VERSION "HNNBNNNYNNNNNNNNNNNNNNNNNNNNNNNNNNNNNNNNNN/4/%%%/4/'%**4NNN///"

NS_ :

BS_:

BU_: Frontradar Frontsensorik

BO_ 262 ESP_05: 8 Vector__XXX
 SG_ ESP_05_CRC : 0|8@1+ (1,0) [0|255] ""  Frontradar,Frontsensorik
 SG_ ESP_05_BZ : 8|4@1+ (1,0) [0|15] ""  Frontradar,Frontsensorik
 SG_ ESP_QBit_Bremsdruck : 12|1@1+ (1,0) [0|1] ""  Frontradar,Frontsensorik
 SG_ ESP_QBit_Fahrer_bremst : 13|1@1+ (1,0) [0|1] ""  Frontradar
 SG_ ESP_Schwelle_Unterdruck : 14|2@1+ (1,0) [0|3] "" Vector__XXX
 SG_ ESP_Bremsdruck : 16|10@1+ (0.3,-30) [-30|276.6] "Unit_Bar"  Frontradar,Frontsensorik
 SG_ ESP_Fahrer_bremst : 26|1@1+ (1,0) [0|1] ""  Frontradar
 SG_ ESP_Verz_TSK_aktiv : 27|1@1+ (1,0) [0|1] "" Vector__XXX
 SG_ ESP_Lenkeingriff_ADS : 28|1@1+ (1,0) [0|1] "" Vector__XXX
 SG_ ESP_Konsistenz_TSK : 29|1@1+ (1,0) [0|1] "" Vector__XXX
 SG_ ESP_Bremsruck_AWV2 : 30|1@1+ (1,0) [0|1] "" Vector__XXX
 SG_ ESP_Konsistenz_AWV2 : 31|1@1+ (1,0) [0|1] "" Vector__XXX
 SG_ ECD_Fehler : 32|1@1+ (1,0) [0|1] "" Vector__XXX
 SG_ ECD_nicht_verfuegbar : 33|1@1+ (1,0) [0|1] "" Vector__XXX
 SG_ ESP_Status_Bremsentemp : 34|1@1+ (1,0) [0|1] ""  Frontradar
 SG_ ESP_Autohold_Standby : 35|1@1+ (1,0) [0|1] ""  Frontradar
 SG_ ESP_HDC_Standby : 36|1@1+ (1,0) [0|1] ""  Frontradar
 SG_ ESP_HBA_aktiv : 37|1@1+ (1,0) [0|1] "" Vector__XXX
 SG_ ESP_Prefill_ausgeloest : 38|1@1+ (1,0) [0|1] "" Vector__XXX
 SG_ ESP_Rueckwaertsfahrt_erkannt : 39|1@1+ (1,0) [0|1] "" Vector__XXX
 SG_ ESP_Status_Anfahrhilfe : 40|1@1+ (1,0) [0|1] "" Vector__XXX
 SG_ ESP_HDC_aktiv : 41|1@1+ (1,0) [0|1] ""  Frontradar
 SG_ ESP_StartStopp_Info : 42|2@1+ (1,0) [0|3] "" Vector__XXX
 SG_ ESP_Eingr_HL : 44|1@1+ (1,0) [0|1] "" Vector__XXX
 SG_ ESP_Eingr_HR : 45|1@1+ (1,0) [0|1] "" Vector__XXX
 SG_ ESP_Eingr_VL : 46|1@1+ (1,0) [0|1] "" Vector__XXX
 SG_ ESP_Eingr_VR : 47|1@1+ (1,0) [0|1] "" Vector__XXX
 SG_ ESP_BKV_Unterdruck : 48|8@1+ (4,0) [4|1012] "Unit_MilliBar" Vector__XXX
 SG_ ESP_Autohold_aktiv : 56|1@1+ (1,0) [0|1] ""  Frontradar
 SG_ ESP_FStatus_Anfahrhilfe : 57|1@1+ (1,0) [0|1] "" Vector__XXX
 SG_ ESP_Verz_EPB_aktiv : 58|1@1+ (1,0) [0|1] ""  Frontradar
 SG_ ECD_Bremslicht : 59|1@1+ (1,0) [0|1] "" Vector__XXX
 SG_ ESP_Verzoeg_EPB_verf : 60|1@1+ (1,0) [0|1] "" Vector__XXX
 SG_ ESP_Status_Bremsdruck : 61|1@1+ (1,0) [0|1] ""  Frontradar,Frontsensorik
 SG_ ESP_Anforderung_EPB : 62|2@1+ (1,0) [0|3] "" Vector__XXX

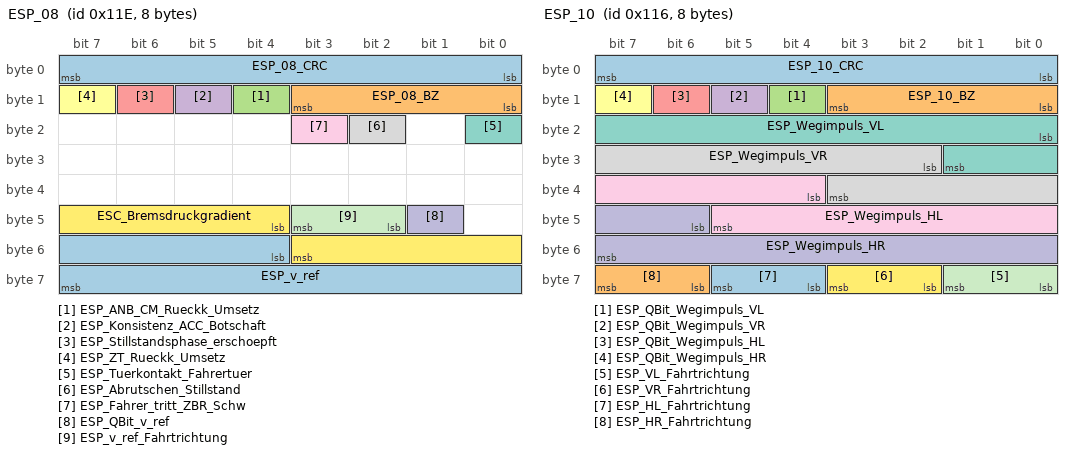
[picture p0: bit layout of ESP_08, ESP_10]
BO_ 286 ESP_08: 8 Vector__XXX
 SG_ ESP_08_CRC : 0|8@1+ (1,0) [0|255] "" Vector__XXX
 SG_ ESP_08_BZ : 8|4@1+ (1,0) [0|15] "" Vector__XXX
 SG_ ESP_ANB_CM_Rueckk_Umsetz : 12|1@1+ (1,0) [0|1] "" Vector__XXX
 SG_ ESP_Konsistenz_ACC_Botschaft : 13|1@1+ (1,0) [0|1] "" Vector__XXX
 SG_ ESP_Stillstandsphase_erschoepft : 14|1@1+ (1,0) [0|1] "" Vector__XXX
 SG_ ESP_ZT_Rueckk_Umsetz : 15|1@1+ (1,0) [0|1] "" Vector__XXX
 SG_ ESP_Tuerkontakt_Fahrertuer : 16|1@1+ (1,0) [0|1] "" Vector__XXX
 SG_ ESP_Abrutschen_Stillstand : 18|1@1+ (1,0) [0|1] "" Vector__XXX
 SG_ ESP_Fahrer_tritt_ZBR_Schw : 19|1@1+ (1,0) [0|1] "" Vector__XXX
 SG_ ESP_QBit_v_ref : 41|1@1+ (1,0) [0|1] "" Vector__XXX
 SG_ ESP_v_ref_Fahrtrichtung : 42|2@1+ (1,0) [0|3] "" Vector__XXX
 SG_ ESC_Bremsdruckgradient : 44|8@1+ (10,0) [0|2500] "Unit_BarPerSecon" Vector__XXX
 SG_ ESP_v_ref : 52|12@1+ (0.125,0) [0|511.5] "Unit_KiloMeterPerHour" Vector__XXX

BO_ 278 ESP_10: 8 Vector__XXX
 SG_ ESP_10_CRC : 0|8@1+ (1,0) [0|255] ""  Frontradar
 SG_ ESP_10_BZ : 8|4@1+ (1,0) [0|15] ""  Frontradar
 SG_ ESP_QBit_Wegimpuls_VL : 12|1@1+ (1,0) [0|1] ""  Frontradar
 SG_ ESP_QBit_Wegimpuls_VR : 13|1@1+ (1,0) [0|1] ""  Frontradar
 SG_ ESP_QBit_Wegimpuls_HL : 14|1@1+ (1,0) [0|1] ""  Frontradar
 SG_ ESP_QBit_Wegimpuls_HR : 15|1@1+ (1,0) [0|1] ""  Frontradar
 SG_ ESP_Wegimpuls_VL : 16|10@1+ (1,0) [0|1000] ""  Frontradar
 SG_ ESP_Wegimpuls_VR : 26|10@1+ (1,0) [0|1000] ""  Frontradar
 SG_ ESP_Wegimpuls_HL : 36|10@1+ (1,0) [0|1000] ""  Frontradar
 SG_ ESP_Wegimpuls_HR : 46|10@1+ (1,0) [0|1000] ""  Frontradar
 SG_ ESP_VL_Fahrtrichtung : 56|2@1+ (1,0) [0|3] ""  Frontradar
 SG_ ESP_VR_Fahrtrichtung : 58|2@1+ (1,0) [0|3] ""  Frontradar
 SG_ ESP_HL_Fahrtrichtung : 60|2@1+ (1,0) [0|3] ""  Frontradar
 SG_ ESP_HR_Fahrtrichtung : 62|2@1+ (1,0) [0|3] ""  Frontradar

BO_ 418 ESP_15: 8 Vector__XXX
 SG_ ESP_15_CRC : 0|8@1+ (1,0) [0|255] ""  Frontradar
 SG_ ESP_15_BZ : 8|4@1+ (1,0) [0|15] ""  Frontradar
 SG_ HMS_P_beibehalten_GE : 12|2@1+ (1,0) [0|3] "" Vector__XXX
 SG_ HMS_Konsistenz_GE : 14|1@1+ (1,0) [0|1] "" Vector__XXX
 SG_ HMS_Konsistenz_IPA : 15|1@1+ (1,0) [0|1] "" Vector__XXX
 SG_ HMS_Konsistenz_EBKV : 16|1@1+ (1,0) [0|1] "" Vector__XXX
 SG_ HMS_Konsistenz_RCTA : 17|1@1+ (1,0) [0|1] "" Vector__XXX
 SG_ HMS_Konsistenz_STA : 18|1@1+ (1,0) [0|1] "" Vector__XXX
 SG_ HMS_Konsistenz_MO : 19|1@1+ (1,0) [0|1] "" Vector__XXX
 SG_ HMS_halten_nicht_verfuegbar : 20|1@1+ (1,0) [0|1] "" Vector__XXX
 SG_ NL_PRIM_STP_01_Status : 21|3@1+ (1,0) [0|7] "" Vector__XXX
 SG_ HMS_Notstopp_Status : 29|3@1+ (1,0) [0|7] "" Vector__XXX
 SG_ HMS_parken_nicht_verfuegbar : 32|1@1+ (1,0) [0|1] "" Vector__XXX
 SG_ HMS_Anforderung_GE : 33|3@1+ (1,0) [0|7] "" Vector__XXX
 SG_ HMS_Systemstatus : 36|4@1+ (1,0) [0|15] ""  Frontradar
 SG_ HMS_Stillstand : 40|3@1+ (1,0) [0|7] "" Vector__XXX
 SG_ HMS_aktives_System : 43|5@1+ (1,0) [0|31] ""  Frontradar
 SG_ HMS_Konsistenz_HVLM : 48|1@1+ (1,0) [0|1] "" Vector__XXX
 SG_ HMS_Konsistenz_ACC : 49|1@1+ (1,0) [0|1] "" Vector__XXX
 SG_ HMS_Fehlerstatus : 50|3@1+ (1,0) [0|7] ""  Frontradar
 SG_ ESP_Index_Haltemoment : 53|1@1+ (1,0) [0|1] "" Vector__XXX
 SG_ ESP_Haltemoment : 54|10@1+ (10,0) [0|10210] "Unit_NewtoMeter" Vector__XXX

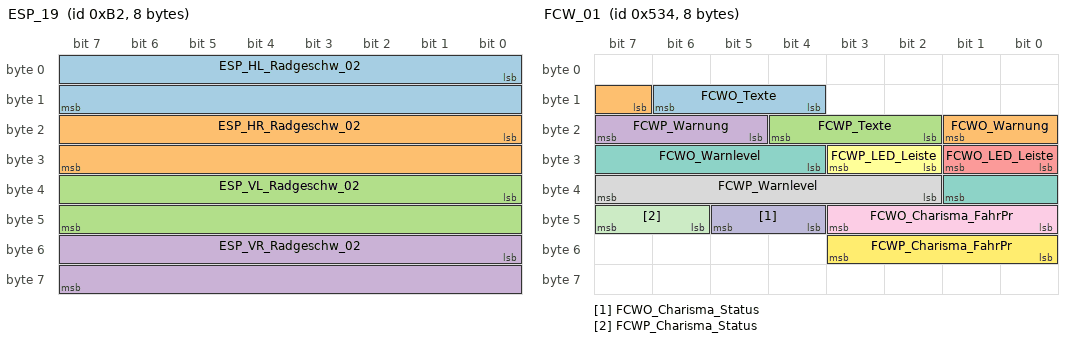
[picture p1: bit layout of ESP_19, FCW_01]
BO_ 178 ESP_19: 8 Vector__XXX
 SG_ ESP_HL_Radgeschw_02 : 0|16@1+ (0.0075,0) [0|491.49] "Unit_KiloMeterPerHour"  Frontradar
 SG_ ESP_HR_Radgeschw_02 : 16|16@1+ (0.0075,0) [0|491.49] "Unit_KiloMeterPerHour"  Frontradar
 SG_ ESP_VL_Radgeschw_02 : 32|16@1+ (0.0075,0) [0|491.49] "Unit_KiloMeterPerHour"  Frontradar
 SG_ ESP_VR_Radgeschw_02 : 48|16@1+ (0.0075,0) [0|491.49] "Unit_KiloMeterPerHour"  Frontradar

BO_ 1629 ESP_20: 8 Vector__XXX
 SG_ ESP_20_CRC : 0|8@1+ (1,0) [0|255] ""  Frontradar,Frontsensorik
 SG_ ESP_20_BZ : 8|4@1+ (1,0) [0|15] ""  Frontradar,Frontsensorik
 SG_ BR_Systemart : 12|2@1+ (1,0) [0|3] "" Vector__XXX
 SG_ ESP_SpannungsAnf_02 : 14|2@1+ (1,0) [0|3] "" Vector__XXX
 SG_ ESP_Zaehnezahl : 16|8@1+ (1,0) [0|255] ""  Frontradar,Frontsensorik
 SG_ ESP_Charisma_FahrPr : 24|4@1+ (1,0) [0|15] "" Vector__XXX
 SG_ ESP_Charisma_Status : 28|2@1+ (1,0) [0|3] "" Vector__XXX
 SG_ ESP_Wiederstart_Anz_01 : 30|1@1+ (1,0) [0|1] "" Vector__XXX
 SG_ ESP_Wiederstart_Anz_02 : 31|1@1+ (1,0) [0|1] "" Vector__XXX
 SG_ ESP_Wiederstart_Anz_03 : 32|1@1+ (1,0) [0|1] "" Vector__XXX
 SG_ ESP_Wiederstart_Anz_04 : 33|1@1+ (1,0) [0|1] "" Vector__XXX
 SG_ ESP_Stoppverbot_Anz_01 : 34|1@1+ (1,0) [0|1] "" Vector__XXX
 SG_ ESP_Stoppverbot_Anz_02 : 35|1@1+ (1,0) [0|1] "" Vector__XXX
 SG_ ESP_Stoppverbot_Anz_03 : 36|1@1+ (1,0) [0|1] "" Vector__XXX
 SG_ ESP_Stoppverbot_Anz_04 : 37|1@1+ (1,0) [0|1] "" Vector__XXX
 SG_ ESP_Stoppverbot_Anz_05 : 38|1@1+ (1,0) [0|1] "" Vector__XXX
 SG_ ESP_Stoppverbot_Anz_06 : 39|1@1+ (1,0) [0|1] "" Vector__XXX
 SG_ ESP_Stoppverbot_Anz_07 : 40|1@1+ (1,0) [0|1] "" Vector__XXX
 SG_ ESP_Stoppverbot_Anz_Std : 41|1@1+ (1,0) [0|1] "" Vector__XXX
 SG_ ESP_Dachrelingsensor : 42|2@1+ (1,0) [0|3] "" Vector__XXX
 SG_ ESP_Stoppverbot_Anz_08 : 44|1@1+ (1,0) [0|1] "" Vector__XXX
 SG_ HDC_Charisma_FahrPr : 45|4@1+ (1,0) [0|15] "" Vector__XXX
 SG_ HDC_Charisma_Status : 49|2@1+ (1,0) [0|3] "" Vector__XXX
 SG_ BR_QBit_Reifenumfang : 51|1@1+ (1,0) [0|1] ""  Frontradar,Frontsensorik
 SG_ BR_Reifenumfang : 52|12@1+ (1,0) [0|4095] "Unit_MilliMeter"  Frontradar,Frontsensorik

BO_ 253 ESP_21: 8 Vector__XXX
 SG_ ESP_21_CRC : 0|8@1+ (1,0) [0|255] ""  Frontradar,Frontsensorik
 SG_ ESP_21_BZ : 8|4@1+ (1,0) [0|15] ""  Frontradar,Frontsensorik
 SG_ BR_Eingriffsmoment : 12|10@1+ (1,-509) [-509|509] "" Vector__XXX
 SG_ ESP_PLA_Bremseingriff : 22|1@1+ (1,0) [0|1] "" Vector__XXX
 SG_ ESP_Diagnose : 23|1@1+ (1,0) [0|1] ""  Frontradar
 SG_ ESC_Reku_Freigabe : 24|1@1+ (1,0) [0|1] "" Vector__XXX
 SG_ ESC_v_Signal_Qualifier_High_Low : 25|3@1+ (1,0) [0|7] "" Vector__XXX
 SG_ ESP_Vorsteuerung : 28|1@1+ (1,0) [0|1] "" Vector__XXX
 SG_ ESP_AWV3_Brems_aktiv : 29|1@1+ (1,0) [0|1] "" Vector__XXX
 SG_ OBD_Schlechtweg : 30|1@1+ (1,0) [0|1] "" Vector__XXX
 SG_ OBD_QBit_Schlechtweg : 31|1@1+ (1,0) [0|1] "" Vector__XXX
 SG_ ESP_v_Signal : 32|16@1+ (0.01,0) [0|655.32] "Unit_KiloMeterPerHour"  Frontradar,Frontsensorik
 SG_ ASR_Tastung_passiv : 48|1@1+ (1,0) [0|1] ""  Frontradar,Frontsensorik
 SG_ ESP_Tastung_passiv : 49|1@1+ (1,0) [0|1] ""  Frontradar,Frontsensorik
 SG_ ESP_Systemstatus : 50|1@1+ (1,0) [0|1] ""  Frontradar
 SG_ ASR_Schalteingriff : 51|2@1+ (1,0) [0|3] "" Vector__XXX
 SG_ ESP_Haltebestaetigung : 53|1@1+ (1,0) [0|1] ""  Frontradar
 SG_ ESP_MKB_Abbruch_Geschw : 54|1@1+ (1,0) [0|1] "" Vector__XXX
 SG_ ESP_QBit_v_Signal : 55|1@1+ (1,0) [0|1] ""  Frontradar,Frontsensorik
 SG_ ABS_Bremsung : 56|1@1+ (1,0) [0|1] ""  Frontradar,Frontsensorik
 SG_ ASR_Anf : 57|1@1+ (1,0) [0|1] ""  Frontradar
 SG_ MSR_Anf : 58|1@1+ (1,0) [0|1] ""  Frontradar
 SG_ EBV_Eingriff : 59|1@1+ (1,0) [0|1] ""  Frontradar
 SG_ EDS_Eingriff : 60|1@1+ (1,0) [0|1] ""  Frontradar
 SG_ ESP_Eingriff : 61|1@1+ (1,0) [0|1] ""  Frontradar,Frontsensorik
 SG_ ESP_ASP : 62|1@1+ (1,0) [0|1] ""  Frontradar
 SG_ ESP_Anhaltevorgang_ACC_aktiv : 63|1@1+ (1,0) [0|1] "" Vector__XXX

BO_ 427 ESP_33: 8 Vector__XXX
 SG_ ESP_33_CRC : 0|8@1+ (1,0) [0|255] ""  Frontradar
 SG_ ESP_33_BZ : 8|4@1+ (1,0) [0|15] ""  Frontradar
 SG_ ESC_AHW_aktiv : 12|3@1+ (1,0) [0|7] ""  Frontradar
 SG_ ESC_AHW_nicht_verfuegbar : 15|1@1+ (1,0) [0|1] ""  Frontradar
 SG_ ESC_ANB_CM_aktiv : 16|2@1+ (1,0) [0|3] ""  Frontradar
 SG_ ESC_ANB_CM_nicht_verfuegbar : 18|1@1+ (1,0) [0|1] ""  Frontradar
 SG_ ESC_Warnruck_aktiv : 19|4@1+ (1,0) [0|15] ""  Frontradar
 SG_ ESC_Warnruck_nicht_verfuegbar : 23|1@1+ (1,0) [0|1] ""  Frontradar
 SG_ ESC_Prefill_aktiv : 24|1@1+ (1,0) [0|1] ""  Frontradar
 SG_ ESC_Prefill_nicht_verfuegbar : 25|1@1+ (1,0) [0|1] ""  Frontradar
 SG_ ESC_HBA_aktiv : 26|1@1+ (1,0) [0|1] ""  Frontradar
 SG_ ESC_HBA_nicht_verfuegbar : 27|1@1+ (1,0) [0|1] ""  Frontradar
 SG_ ESC_TSK_SRBM_Anf : 28|1@1+ (1,0) [0|1] ""  Frontradar
 SG_ ESC_TSK_SRBM_nicht_verfuegbar : 29|1@1+ (1,0) [0|1] "" Vector__XXX
 SG_ ESC_Verz_Reg_aktiv : 30|4@1+ (1,0) [0|15] ""  Frontradar
 SG_ ESC_Verz_Reg_nicht_verfuegbar : 34|1@1+ (1,0) [0|1] ""  Frontradar
 SG_ ESC_Verz_Reg_TB_nicht_verfuegbar : 35|1@1+ (1,0) [0|1] ""  Frontradar
 SG_ ESC_Verz_Reg_ZB_nicht_verfuegbar : 36|1@1+ (1,0) [0|1] ""  Frontradar
 SG_ ESC_Bremslicht_unplausibel : 37|1@1+ (1,0) [0|1] ""  Frontradar
 SG_ ESC_Konsistenz_ACC : 38|1@1+ (1,0) [0|1] ""  Frontradar
 SG_ ESC_Konsistenz_AWV : 39|1@1+ (1,0) [0|1] ""  Frontradar
 SG_ ESC_Konsistenz_ARA : 40|1@1+ (1,0) [0|1] "" Vector__XXX
 SG_ ESC_Konsistenz_IPA : 41|1@1+ (1,0) [0|1] "" Vector__XXX
 SG_ ESC_Konsistenz_FCW : 42|1@1+ (1,0) [0|1] "" Vector__XXX
 SG_ ESC_Konsistenz_NV : 43|1@1+ (1,0) [0|1] "" Vector__XXX
 SG_ ESC_Konsistenz_RCTA : 44|1@1+ (1,0) [0|1] "" Vector__XXX
 SG_ ESC_Konsistenz_TSK : 45|1@1+ (1,0) [0|1] "" Vector__XXX
 SG_ ESC_Konsistenz_vFGS : 46|1@1+ (1,0) [0|1] "" Vector__XXX
 SG_ ESC_Konsistenz_STA : 47|1@1+ (1,0) [0|1] "" Vector__XXX
 SG_ ESC_Fahrer_Bremsdruck_bestimmend : 48|1@1+ (1,0) [0|1] "" Vector__XXX
 SG_ ESC_Konsistenz_EA : 49|1@1+ (1,0) [0|1] "" Vector__XXX
 SG_ ESC_Konsistenz_BFF : 50|1@1+ (1,0) [0|1] "" Vector__XXX
 SG_ ESC_Konsistenz_MKB : 51|1@1+ (1,0) [0|1] "" Vector__XXX
 SG_ ESC_Verz_ASIL_Verfuegbarkeit : 52|3@1+ (1,0) [0|7] ""  Frontradar
 SG_ ESC_Pumpenanlauf_aktiv : 55|1@1+ (1,0) [0|1] ""  Frontradar
 SG_ ESC_Konsistenz_AGW : 56|1@1+ (1,0) [0|1] "" Vector__XXX
 SG_ ESC_Konsistenz_KAS : 57|1@1+ (1,0) [0|1] "" Vector__XXX
 SG_ ESC_Konsistenz_PCF : 58|1@1+ (1,0) [0|1] "" Vector__XXX

BO_ 264 Fahrwerk_01: 8 Vector__XXX
 SG_ Fahrwerk_01_CRC : 0|8@1+ (1,0) [0|255] "" Vector__XXX
 SG_ Fahrwerk_01_BZ : 8|4@1+ (1,0) [0|15] "" Vector__XXX
 SG_ FA_Hoehenwerte_kalibriert M : 12|1@1+ (1,0) [0|1] "" Vector__XXX
 SG_ FA_ESP_Zuschaltung : 13|1@1+ (1,0) [0|1] "" Vector__XXX
 SG_ FA_Hoehenwert_VL_00 m0 : 16|8@1+ (1,-127) [-127|126] "Unit_MilliMeter" Vector__XXX
 SG_ FA_Hoehenwert_VL_01 m1 : 16|8@1+ (0.4,0) [0|100] "Unit_PerCent" Vector__XXX
 SG_ FA_Hoehenwert_VR_00 m0 : 24|8@1+ (1,-127) [-127|126] "Unit_MilliMeter" Vector__XXX
 SG_ FA_Hoehenwert_VR_01 m1 : 24|8@1+ (0.4,0) [0|100] "Unit_PerCent" Vector__XXX
 SG_ FA_Hoehenwert_HL_00 m0 : 32|8@1+ (1,-127) [-127|126] "Unit_MilliMeter" Vector__XXX
 SG_ FA_Hoehenwert_HL_01 m1 : 32|8@1+ (0.4,0) [0|100] "Unit_PerCent" Vector__XXX
 SG_ FA_Hoehenwert_HR_00 m0 : 40|8@1+ (1,-127) [-127|126] "Unit_MilliMeter" Vector__XXX
 SG_ FA_Hoehenwert_HR_01 m1 : 40|8@1+ (0.4,0) [0|100] "Unit_PerCent" Vector__XXX

BO_ 1332 FCW_01: 8 Vector__XXX
 SG_ FCWO_Texte : 12|3@1+ (1,0) [0|7] "" Vector__XXX
 SG_ FCWO_Warnung : 15|3@1+ (1,0) [0|7] "" Vector__XXX
 SG_ FCWP_Texte : 18|3@1+ (1,0) [0|7] "" Vector__XXX
 SG_ FCWP_Warnung : 21|3@1+ (1,0) [0|7] "" Vector__XXX
 SG_ FCWO_LED_Leiste : 24|2@1+ (1,0) [0|3] "" Vector__XXX
 SG_ FCWP_LED_Leiste : 26|2@1+ (1,0) [0|3] "" Vector__XXX
 SG_ FCWO_Warnlevel : 28|6@1+ (1,0) [0|63] "" Vector__XXX
 SG_ FCWP_Warnlevel : 34|6@1+ (1,0) [0|63] ""  Frontradar
 SG_ FCWO_Charisma_FahrPr : 40|4@1+ (1,0) [0|15] "" Vector__XXX
 SG_ FCWO_Charisma_Status : 44|2@1+ (1,0) [0|3] "" Vector__XXX
 SG_ FCWP_Charisma_Status : 46|2@1+ (1,0) [0|3] "" Vector__XXX
 SG_ FCWP_Charisma_FahrPr : 48|4@1+ (1,0) [0|15] "" Vector__XXX

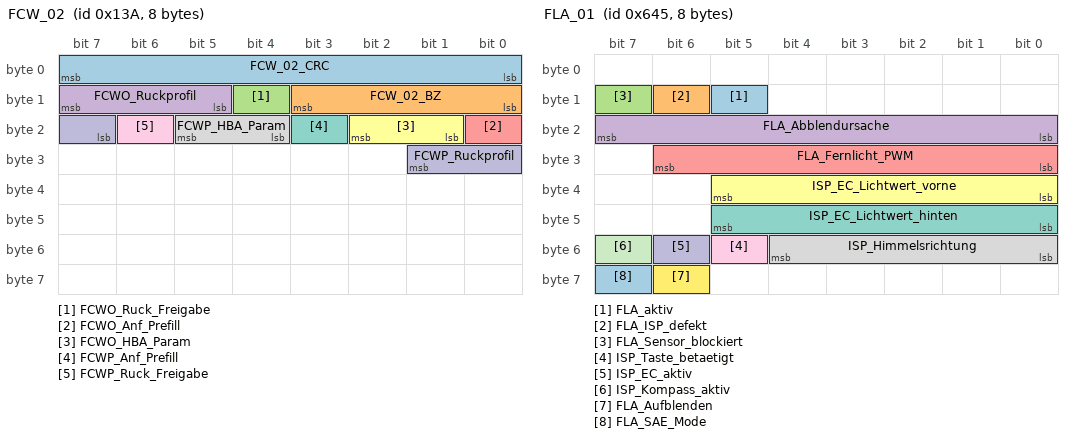
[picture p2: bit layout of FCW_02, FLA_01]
BO_ 314 FCW_02: 8 Vector__XXX
 SG_ FCW_02_CRC : 0|8@1+ (1,0) [0|255] "" Vector__XXX
 SG_ FCW_02_BZ : 8|4@1+ (1,0) [0|15] "" Vector__XXX
 SG_ FCWO_Ruck_Freigabe : 12|1@1+ (1,0) [0|1] "" Vector__XXX
 SG_ FCWO_Ruckprofil : 13|3@1+ (1,0) [0|7] "" Vector__XXX
 SG_ FCWO_Anf_Prefill : 16|1@1+ (1,0) [0|1] "" Vector__XXX
 SG_ FCWO_HBA_Param : 17|2@1+ (1,0) [0|3] "" Vector__XXX
 SG_ FCWP_Anf_Prefill : 19|1@1+ (1,0) [0|1] "" Vector__XXX
 SG_ FCWP_HBA_Param : 20|2@1+ (1,0) [0|3] "" Vector__XXX
 SG_ FCWP_Ruck_Freigabe : 22|1@1+ (1,0) [0|1] "" Vector__XXX
 SG_ FCWP_Ruckprofil : 23|3@1+ (1,0) [0|7] "" Vector__XXX

BO_ 1605 FLA_01: 8 Frontsensorik
 SG_ FLA_aktiv : 13|1@1+ (1,0) [0|1] "" Vector__XXX
 SG_ FLA_ISP_defekt : 14|1@1+ (1,0) [0|1] "" Vector__XXX
 SG_ FLA_Sensor_blockiert : 15|1@1+ (1,0) [0|1] "" Vector__XXX
 SG_ FLA_Abblendursache : 16|8@1+ (1,0) [0|255] "" Vector__XXX
 SG_ FLA_Fernlicht_PWM : 24|7@1+ (1,0) [0|100] "Unit_PerCent" Vector__XXX
 SG_ ISP_EC_Lichtwert_vorne : 32|6@1+ (1,0) [0|61] "Unit_None" Vector__XXX
 SG_ ISP_EC_Lichtwert_hinten : 40|6@1+ (1,0) [0|61] "Unit_None" Vector__XXX
 SG_ ISP_Himmelsrichtung : 48|5@1+ (12,0) [0|348] "Unit_DegreOfArc" Vector__XXX
 SG_ ISP_Taste_betaetigt : 53|1@1+ (1,0) [0|1] "" Vector__XXX
 SG_ ISP_EC_aktiv : 54|1@1+ (1,0) [0|1] "" Vector__XXX
 SG_ ISP_Kompass_aktiv : 55|1@1+ (1,0) [0|1] "" Vector__XXX
 SG_ FLA_Aufblenden : 62|1@1+ (1,0) [0|1] "" Vector__XXX
 SG_ FLA_SAE_Mode : 63|1@1+ (1,0) [0|1] "" Vector__XXX

BO_ 987 Gateway_72: 8 Vector__XXX
 SG_ BCM_01_alt : 0|1@1+ (1,0) [0|1] ""  Frontradar,Frontsensorik
 SG_ SMLS_01_alt : 1|1@1+ (1,0) [0|1] ""  Frontradar,Frontsensorik
 SG_ ZV_02_alt : 2|1@1+ (1,0) [0|1] ""  Frontradar
 SG_ Wischer_01_alt : 3|1@1+ (1,0) [0|1] ""  Frontradar,Frontsensorik
 SG_ Anhaenger_01_alt : 4|1@1+ (1,0) [0|1] ""  Frontradar,Frontsensorik
 SG_ Klima_Sensor_02_alt : 5|1@1+ (1,0) [0|1] ""  Frontradar,Frontsensorik
 SG_ Verdeck_01_alt : 6|1@1+ (1,0) [0|1] "" Vector__XXX
 SG_ Klima_11_alt : 7|1@1+ (1,0) [0|1] "" Vector__XXX
 SG_ WFS_01_alt : 8|1@1+ (1,0) [0|1] ""  Frontradar,Frontsensorik
 SG_ Licht_Anf_01_alt : 9|1@1+ (1,0) [0|1] "" Vector__XXX
 SG_ ZV_verriegelt_extern_soll : 10|1@1+ (1,0) [0|1] "" Vector__XXX
 SG_ BH_Lichthupe : 11|1@1+ (1,0) [0|1] "" Vector__XXX
 SG_ WFS_Klemmenfreigabe : 12|1@1+ (1,0) [0|1] "" Vector__XXX
 SG_ ZV_Tankklappe_offen : 13|1@1+ (1,0) [0|1] "" Vector__XXX
 SG_ AAG_Anhaenger_abgesteckt : 14|1@1+ (1,0) [0|1] "" Vector__XXX
 SG_ BCM1_LDS_Stellung : 15|3@1+ (1,0) [0|7] "" Vector__XXX
 SG_ VS_Verdeck_Anf : 18|1@1+ (1,0) [0|1] "" Vector__XXX
 SG_ VS_VD_entriegelt : 19|1@1+ (1,0) [0|1] "" Vector__XXX
 SG_ ZV_HFS_offen : 20|1@1+ (1,0) [0|1] ""  Frontradar
 SG_ ZV_HBFS_offen : 21|1@1+ (1,0) [0|1] ""  Frontradar
 SG_ VS_VD_offen_ver : 22|1@1+ (1,0) [0|1] "" Vector__XXX
 SG_ VS_VD_zu_ver : 23|1@1+ (1,0) [0|1] "" Vector__XXX
 SG_ ZV_BT_offen : 24|1@1+ (1,0) [0|1] ""  Frontradar
 SG_ BCM1_Rueckfahrlicht_Schalter : 25|1@1+ (1,0) [0|1] ""  Frontradar,Frontsensorik
 SG_ ZV_FT_offen : 26|1@1+ (1,0) [0|1] ""  Frontradar
 SG_ Wischer_vorne_aktiv : 27|1@1+ (1,0) [0|1] ""  Frontradar,Frontsensorik
 SG_ AAG_Anhaenger_erkannt : 28|1@1+ (1,0) [0|1] ""  Frontradar,Frontsensorik
 SG_ BCM1_MH_Schalter : 29|1@1+ (1,0) [0|1] ""  Frontradar
 SG_ ZV_HD_offen : 30|1@1+ (1,0) [0|1] "" Vector__XXX
 SG_ Waschen_vorne_aktiv : 31|1@1+ (1,0) [0|1] "" Vector__XXX
 SG_ KL_Thermomanagement : 32|2@1+ (1,0) [0|3] "" Vector__XXX
 SG_ WFS_Schluessel_Fahrberecht : 34|4@1+ (1,0) [0|15] ""  Frontradar,Frontsensorik
 SG_ BCM_Rueckfahrlicht_Anf : 38|1@1+ (1,0) [0|1] "" Vector__XXX
 SG_ WWSs_01_alt : 39|1@1+ (1,0) [0|1] ""  Frontradar,Frontsensorik
 SG_ BCM_Tankklappensteller_Fehler : 40|1@1+ (1,0) [0|1] "" Vector__XXX
 SG_ ZV_verriegelt_soll : 42|2@1+ (1,0) [0|3] "" Vector__XXX
 SG_ ZV_Schluessel_Zugang : 44|4@1+ (1,0) [0|15] "" Vector__XXX
 SG_ WFS_ID_Geb_autorisiert_in_Kl15 : 48|1@1+ (1,0) [0|1] "" Vector__XXX
 SG_ BH_Fernlicht : 49|1@1+ (1,0) [0|1] ""  Frontsensorik
 SG_ BH_Blinker_li : 50|1@1+ (1,0) [0|1] ""  Frontradar,Frontsensorik
 SG_ BH_Blinker_re : 51|1@1+ (1,0) [0|1] ""  Frontradar,Frontsensorik
 SG_ BCM1_OBD_FStatus_ATemp : 52|4@1+ (1,0) [0|15] "" Vector__XXX
 SG_ BCM1_Aussen_Temp_ungef : 56|8@1+ (0.5,-50) [-50|76] "Unit_DegreCelsi"  Frontradar,Frontsensorik

BO_ 988 Gateway_73: 8 Vector__XXX
 SG_ Motor_12_alt : 0|1@1+ (1,0) [0|1] ""  Frontradar
 SG_ ESP_07_alt : 1|1@1+ (1,0) [0|1] ""  Frontradar
 SG_ Getriebe_11_alt : 2|1@1+ (1,0) [0|1] "" Vector__XXX
 SG_ Getriebe_13_alt : 3|1@1+ (1,0) [0|1] ""  Frontradar
 SG_ Getriebe_17_alt : 4|1@1+ (1,0) [0|1] ""  Frontradar
 SG_ GW_73_va_15 : 5|1@1+ (1,0) [0|1] "" Vector__XXX
 SG_ GW_73_va_16 : 6|1@1+ (1,0) [0|1] "" Vector__XXX
 SG_ GW_73_va_17 : 7|1@1+ (1,0) [0|1] "" Vector__XXX
 SG_ MO_QBit_Drehzahl_01 : 8|1@1+ (1,0) [0|1] ""  Frontradar
 SG_ MKE_Texte : 9|2@1+ (1,0) [0|3] ""  Frontradar
 SG_ MKE_Stufe : 11|3@1+ (1,0) [0|7] ""  Frontradar
 SG_ MO_Drehzahl_01 : 16|16@1+ (0.25,0) [0|16383] "Unit_MinutInver"  Frontradar
 SG_ GE_Fahrstufe : 40|4@1+ (1,0) [0|15] "" Vector__XXX
 SG_ GE_reserv_Fahrstufe : 44|1@1+ (1,0) [0|1] "" Vector__XXX
 SG_ GE_Notlauf : 45|1@1+ (1,0) [0|1] ""  Frontradar
 SG_ ESP_Rollenmodus_Deaktivieren : 46|1@1+ (1,0) [0|1] ""  Frontradar
 SG_ GE_Freilauf_Status : 47|3@1+ (1,0) [0|7] ""  Frontradar

BO_ 991 Gateway_76: 8 Vector__XXX
 SG_ Innenlicht_11_alt : 0|1@1+ (1,0) [0|1] ""  Frontsensorik
 SG_ Spiegel_01_alt : 1|1@1+ (1,0) [0|1] "" Vector__XXX
 SG_ Anhaenger_01_alt : 2|1@1+ (1,0) [0|1] ""  Frontradar
 SG_ Licht_hinten_01_alt : 3|1@1+ (1,0) [0|1] ""  Frontradar
 SG_ LH_EPS_01_alt : 4|1@1+ (1,0) [0|1] ""  Frontsensorik
 SG_ Klima_12_alt : 5|1@1+ (1,0) [0|1] ""  Frontsensorik
 SG_ SMLS_01_alt : 6|1@1+ (1,0) [0|1] ""  Frontsensorik
 SG_ Getriebe_14_alt : 7|1@1+ (1,0) [0|1] ""  Frontradar
 SG_ PLA_01_alt : 8|1@1+ (1,0) [0|1] ""  Frontradar
 SG_ PLA_Status_PLA_EPS : 12|4@1+ (1,0) [0|15] ""  Frontradar
 SG_ IL_Innenlicht_aktiv : 16|1@1+ (1,0) [0|1] ""  Frontsensorik
 SG_ FAS_Taster_Fehler : 17|1@1+ (1,0) [0|1] ""  Frontsensorik
 SG_ AAG_Bremslicht_H_def : 18|1@1+ (1,0) [0|1] ""  Frontradar
 SG_ LH_3_Bremsl_def : 19|1@1+ (1,0) [0|1] ""  Frontradar
 SG_ LH_Bremsl_li_ges_def : 20|1@1+ (1,0) [0|1] ""  Frontradar
 SG_ LH_Bremsl_re_ges_def : 21|1@1+ (1,0) [0|1] ""  Frontradar
 SG_ KL_Beschlagsgefahr : 22|1@1+ (1,0) [0|1] ""  Frontsensorik
 SG_ FAS_Taster : 23|1@1+ (1,0) [0|1] ""  Frontsensorik
 SG_ SP_abklappen : 24|1@1+ (1,0) [0|1] "" Vector__XXX
 SG_ SP_anklappen : 25|1@1+ (1,0) [0|1] "" Vector__XXX
 SG_ KL_Umluftklappe_Status : 26|4@1+ (1,0) [0|15] "" Vector__XXX
 SG_ GE_amax_moeglich : 30|9@1+ (0.024,-2.016) [-2.016|10.224] "Unit_MeterPerSeconSquar"  Frontradar
 SG_ KL_Geblspng_Soll : 40|8@1+ (0.05,1.45) [1.5|14] "Unit_Volt" Vector__XXX
 SG_ EPS_Charisma_FahrPr : 58|4@1+ (1,0) [0|15] ""  Frontsensorik
 SG_ GE_Zustand_Kuppltemp : 62|2@1+ (1,0) [0|3] ""  Frontradar

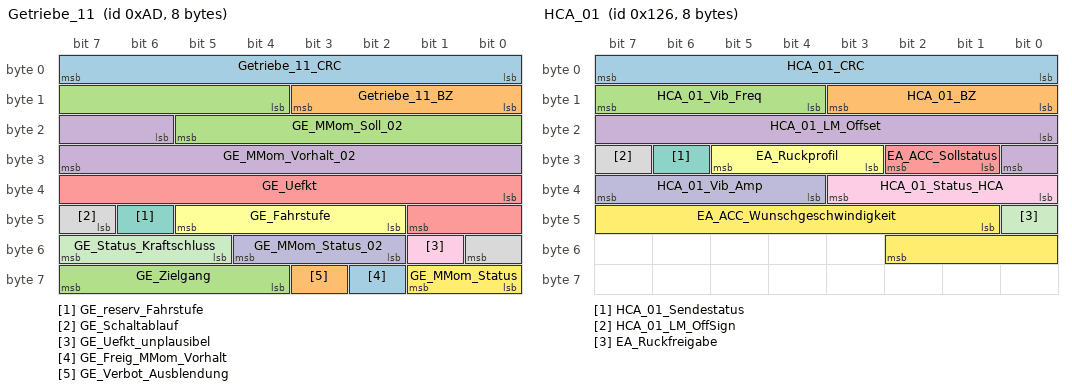
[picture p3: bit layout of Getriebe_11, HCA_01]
BO_ 173 Getriebe_11: 8 Vector__XXX
 SG_ Getriebe_11_CRC : 0|8@1+ (1,0) [0|255] ""  Frontradar
 SG_ Getriebe_11_BZ : 8|4@1+ (1,0) [0|15] ""  Frontradar
 SG_ GE_MMom_Soll_02 : 12|10@1+ (1,-509) [-509|509] "" Vector__XXX
 SG_ GE_MMom_Vorhalt_02 : 22|10@1+ (1,-509) [-509|509] "" Vector__XXX
 SG_ GE_Uefkt : 32|10@1+ (0.1,0) [0|102.2] "" Vector__XXX
 SG_ GE_Fahrstufe : 42|4@1+ (1,0) [0|15] ""  Frontradar
 SG_ GE_reserv_Fahrstufe : 46|1@1+ (1,0) [0|1] "" Vector__XXX
 SG_ GE_Schaltablauf : 47|2@1+ (1,0) [0|3] "" Vector__XXX
 SG_ GE_Uefkt_unplausibel : 49|1@1+ (1,0) [0|1] "" Vector__XXX
 SG_ GE_MMom_Status_02 : 50|3@1+ (1,0) [0|7] "" Vector__XXX
 SG_ GE_Status_Kraftschluss : 53|3@1+ (1,0) [0|7] "" Vector__XXX
 SG_ GE_MMom_Status : 56|2@1+ (1,0) [0|3] "" Vector__XXX
 SG_ GE_Freig_MMom_Vorhalt : 58|1@1+ (1,0) [0|1] "" Vector__XXX
 SG_ GE_Verbot_Ausblendung : 59|1@1+ (1,0) [0|1] "" Vector__XXX
 SG_ GE_Zielgang : 60|4@1+ (1,0) [0|15] "" Vector__XXX

BO_ 299 GRA_ACC_01: 8 Vector__XXX
 SG_ GRA_ACC_01_CRC : 0|8@1+ (1,0) [0|255] ""  Frontradar
 SG_ GRA_ACC_01_BZ : 8|4@1+ (1,0) [0|15] ""  Frontradar
 SG_ GRA_Hauptschalter : 12|1@1+ (1,0) [0|1] ""  Frontradar
 SG_ GRA_Abbrechen : 13|1@1+ (1,0) [0|1] ""  Frontradar
 SG_ GRA_Typ_Hauptschalter : 14|1@1+ (1,0) [0|1] ""  Frontradar
 SG_ GRA_Limiter : 15|1@1+ (1,0) [0|1] "" Vector__XXX
 SG_ GRA_Tip_Setzen : 16|1@1+ (1,0) [0|1] ""  Frontradar
 SG_ GRA_Tip_Hoch : 17|1@1+ (1,0) [0|1] ""  Frontradar
 SG_ GRA_Tip_Runter : 18|1@1+ (1,0) [0|1] ""  Frontradar
 SG_ GRA_Tip_Wiederaufnahme : 19|1@1+ (1,0) [0|1] ""  Frontradar
 SG_ GRA_Verstellung_Zeitluecke : 20|2@1+ (1,0) [0|3] ""  Frontradar
 SG_ GRA_Codierung : 22|2@1+ (1,0) [0|3] ""  Frontradar
 SG_ GRA_Fehler : 24|1@1+ (1,0) [0|1] ""  Frontradar
 SG_ GRA_LIM_Taste_verfuegbar : 25|1@1+ (1,0) [0|1] "" Vector__XXX
 SG_ GRA_Tip_Stufe_2 : 26|1@1+ (1,0) [0|1] ""  Frontradar
 SG_ GRA_Typ_Bedienteil : 27|3@1+ (1,0) [0|7] ""  Frontradar
 SG_ GRA_reserveByte4 : 30|2@1+ (1,0) [0|3] "" Vector__XXX
 SG_ GRA_reserveByte5 : 32|8@1+ (1,0) [0|255] "" Vector__XXX
 SG_ GRA_reserveByte6 : 40|8@1+ (1,0) [0|255] "" Vector__XXX
 SG_ GRA_reserveByte7 : 48|8@1+ (1,0) [0|255] "" Vector__XXX
 SG_ GRA_reserveByte8 : 56|8@1+ (1,0) [0|255] "" Vector__XXX

BO_ 294 HCA_01: 8 Frontsensorik
 SG_ HCA_01_CRC : 0|8@1+ (1,0) [0|255] "" Vector__XXX
 SG_ HCA_01_BZ : 8|4@1+ (1,0) [0|15] "" Vector__XXX
 SG_ HCA_01_Vib_Freq : 12|4@1+ (1,15) [15|30] "Unit_Hertz" Vector__XXX
 SG_ HCA_01_LM_Offset : 16|9@1+ (0.01,0) [0|5.11] "Unit_NewtoMeter" Vector__XXX
 SG_ EA_ACC_Sollstatus : 25|2@1+ (1,0) [0|3] ""  Frontradar
 SG_ EA_Ruckprofil : 27|3@1+ (1,0) [0|7] "" Vector__XXX
 SG_ HCA_01_Sendestatus : 30|1@1+ (1,0) [0|1] "" Vector__XXX
 SG_ HCA_01_LM_OffSign : 31|1@1+ (1,0) [0|1] "" Vector__XXX
 SG_ HCA_01_Status_HCA : 32|4@1+ (1,0) [0|15] "" Vector__XXX
 SG_ HCA_01_Vib_Amp : 36|4@1+ (0.2,0) [0|3] "Unit_NewtoMeter" Vector__XXX
 SG_ EA_Ruckfreigabe : 40|1@1+ (1,0) [0|1] "" Vector__XXX
 SG_ EA_ACC_Wunschgeschwindigkeit : 41|10@1+ (0.32,0) [0|327.04] "Unit_KiloMeterPerHour"  Frontradar

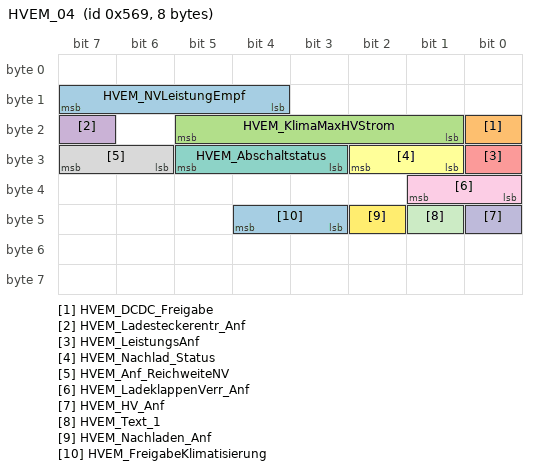
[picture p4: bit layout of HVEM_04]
BO_ 1385 HVEM_04: 8 Vector__XXX
 SG_ HVEM_NVLeistungEmpf : 12|4@1+ (100,0) [0|1500] "Unit_Watt" Vector__XXX
 SG_ HVEM_DCDC_Freigabe : 16|1@1+ (1,0) [0|1] "" Vector__XXX
 SG_ HVEM_KlimaMaxHVStrom : 17|5@1+ (1,0) [0|31] "Unit_Amper" Vector__XXX
 SG_ HVEM_Ladesteckerentr_Anf : 23|1@1+ (1,0) [0|1] "" Vector__XXX
 SG_ HVEM_LeistungsAnf : 24|1@1+ (1,0) [0|1] "" Vector__XXX
 SG_ HVEM_Nachlad_Status : 25|2@1+ (1,0) [0|3] "" Vector__XXX
 SG_ HVEM_Abschaltstatus : 27|3@1+ (1,0) [0|7] "" Vector__XXX
 SG_ HVEM_Anf_ReichweiteNV : 30|2@1+ (1,0) [0|3] "" Vector__XXX
 SG_ HVEM_LadeklappenVerr_Anf : 32|2@1+ (1,0) [0|3] "" Vector__XXX
 SG_ HVEM_HV_Anf : 40|1@1+ (1,0) [0|1] "" Vector__XXX
 SG_ HVEM_Text_1 : 41|1@1+ (1,0) [0|1] "" Vector__XXX
 SG_ HVEM_Nachladen_Anf : 42|1@1+ (1,0) [0|1] "" Vector__XXX
 SG_ HVEM_FreigabeKlimatisierung : 43|2@1+ (1,0) [0|3] "" Vector__XXX

BO_ 1879 ISO_ACC_Req: 8 Vector__XXX
 SG_ ISO_ACC_Req_Data : 0|64@1+ (1,0) [0|1.84467440737096E+019] ""  Frontradar

BO_ 1985 ISO_ACC_Resp: 8 Frontradar
 SG_ ISO_ACC_Resp_Data : 0|64@1+ (1,0) [0|1.84467440737096E+019] "" Vector__XXX

BO_ 1840 ISO_FLA_Req: 8 Vector__XXX
 SG_ ISO_FLA_Req_Data : 0|64@1+ (1,0) [0|1.84467440737096E+019] "" Vector__XXX

BO_ 1946 ISO_FLA_Resp: 8 Vector__XXX
 SG_ ISO_FLA_Resp_Data : 0|64@1+ (1,0) [0|1.84467440737096E+019] "" Vector__XXX

BO_ 1793 ISO_Funktionaler_Req_01: 8 Vector__XXX
 SG_ ISO_01_Req_Data : 0|64@1+ (1,0) [0|1.84467440737096E+019] "" Vector__XXX

BO_ 1794 ISO_Funktionaler_Req_02: 8 Vector__XXX
 SG_ ISO_02_Req_Data : 0|64@1+ (1,0) [0|1.84467440737096E+019] "" Vector__XXX

BO_ 1796 ISO_Funktionaler_Req_04: 8 Vector__XXX
 SG_ ISO_04_Req_Data : 0|64@1+ (1,0) [0|1.84467440737096E+019] "" Vector__XXX

BO_ 1797 ISO_Funktionaler_Req_05: 8 Vector__XXX
 SG_ ISO_05_Req_Data : 0|64@1+ (1,0) [0|1.84467440737096E+019] "" Vector__XXX

BO_ 1798 ISO_Funktionaler_Req_06: 8 Vector__XXX
 SG_ ISO_06_Req_Data : 0|64@1+ (1,0) [0|1.84467440737096E+019] "" Vector__XXX

BO_ 1799 ISO_Funktionaler_Req_07: 8 Vector__XXX
 SG_ ISO_07_Req_Data : 0|64@1+ (1,0) [0|1.84467440737096E+019] "" Vector__XXX

BO_ 1800 ISO_Funktionaler_Req_08: 8 Vector__XXX
 SG_ ISO_08_Req_Data : 0|64@1+ (1,0) [0|1.84467440737096E+019] "" Vector__XXX

CM_ SG_ 262 ESP_05_CRC "Für MLB:
'Berechnung siehe Lastenheft 'Kommunikationsabsicherung für FlexRay und CAN''

Ab MQB und MLBevo:
'Berechnung siehe Lastenheft 'End-to-End Kommunikationsabsicherung''

Endwerte siehe Begleitdokument 'S-PDU Kennungsfolgen'";
CM_ SG_ 262 ESP_QBit_Bremsdruck "QBit des Bremsdrucks. Gesetzt bei Ersatzwert, Init oder Fehler.";
CM_ SG_ 262 ESP_QBit_Fahrer_bremst "Gültigkeit der Bremsdruckschwelleninformation des Signals ESP_Fahrer_bremst vom ESP SG
0x1 = Druckschwelleninformation kann noch nicht oder aufgrund eines Fehlers nicht ausgegeben werden
";
CM_ SG_ 262 ESP_Schwelle_Unterdruck "Verwendung im MQB für HBV-Projekte oder wenn für St/St ein Unterdrucksensor verbaut ist";
CM_ SG_ 262 ESP_Bremsdruck "Rohwert des Bremsdrucks [Vordruck durch Fahrervorgabe (Pvor). Bei aktivem Druckaufbau (Stabilisierungseingriffe) kein Pvor]
";
CM_ SG_ 262 ESP_Fahrer_bremst "Bit wird gesetzt beim Überschreiten der Bremsdruckschwelle

Weiterführende Informationen im Lastenheft spezifiziert und in der entsprechenden Fachabteilung zu erfragen.
";
CM_ SG_ 262 ESP_Verz_TSK_aktiv "Rückmeldeinformation an den Triebsstrangkoordinator/ACC, dass die ECD-Verzögerungsanforderung aktuell umgesetzt wird";
CM_ SG_ 262 ESP_Lenkeingriff_ADS "Im Falle eines fahrzeugstabilisierenden Lenkeingriffs des ADS-Systems soll ACC/GRA deaktiviert werden.

Im MQB wird dieses Signal nicht unterstützt!";
CM_ SG_ 262 ESP_Konsistenz_TSK "Rückmeldung zum Sender einer Verzögerungsanforderung (Triebstrangskoordinator) bezüglich Prüfung der Checksumme, des Botschaftszählers, des langen Timeout und DLC. Wird auch gesetzt bei Verzögerungsanforderung größer einer applizierbaren Schwelle.
";
CM_ SG_ 262 ESP_Bremsruck_AWV2 "Das Signal dient als Rückmeldung zum ACC, dass ein angeforderter AWV2-Bremsruck durchgeführt wird. Die positive Rückmeldung löst u.a. eine entsprechende Fahrerinformation im Kombiinstrument aus";
CM_ SG_ 262 ESP_Konsistenz_AWV2 "Rückmeldung zum Sender einer AWV-Anforderung (ACC-Steuergerät) bezüglich Prüfung der Checksumme, des Botschaftszählers, des langen Timeout und DLC.
";
CM_ SG_ 262 ECD_Fehler "ESP kann die Verzögerungsregelung/Bremsenregelung aufgrund eines internen Fehlers nicht ausführen, mit Fehlereintrag im ESP.
";
CM_ SG_ 262 ECD_nicht_verfuegbar "ESP kann die Verzögerungsregelung/Bremsenregelung temporär nicht ausführen (z.B. Netzwerkmanagement-Betriebe - KL15 Aus; v<18km/h; ESP in Diagnose, ...), ohne Fehlereintrag im ESP.

";
CM_ SG_ 262 ESP_Status_Bremsentemp "ECD-Bremsscheibentemperaturmodell. Rückmeldung für Sender einer ECD Verzögerungsanforderung, ohne Fehlereintrag im ESP";
CM_ SG_ 262 ESP_Autohold_Standby "Rückmeldung an EPB, dass der Fahrer die Funktion Autohold mindestens einmal angefordert hat. Im Fall eines ESP-Ausfalles oder einer Übernahmeaufforderung erfolgt die EPB-Zuschaltung nur nach Setzen dieses Bits. Bit wird gesetzt nach Betätigung des Autohol";
CM_ SG_ 262 ESP_HDC_Standby "Verwendung/Bedienung im MQB und AU57x Allroad:
Flag wird vom ESP gesetzt, wenn über den HDC-Taster die HDC-Funktion eingeschalten wurde";
CM_ SG_ 262 ESP_HBA_aktiv "Verwendung/Bedienung ab D4
Signal gibt an, ob der hydraulische Bremsassistent im Regler aktiviert wurde

Im MQB wird das Signal nicht unterstützt!

";
CM_ SG_ 262 ESP_Prefill_ausgeloest "MLB: Verwendung/Bedienung ab D4
zeigt, ob die Funktion Prefill (aufgrund Fahrpedalgradient) ausgelöst wird; zeigt keinen Funktionszustand bezüglich Fehlerstilllegung

MQB: Wird gesetzt bei jeder Art von aktivem Prefill";
CM_ SG_ 262 ESP_Rueckwaertsfahrt_erkannt "nur bei AU57x und AU416 sowie Audi B8PA
Info, ob Rückwärtsfahrt über internen Algorithmus sicher erkannt

Im MQB wird das Signal nicht unterstützt!";
CM_ SG_ 262 ESP_Status_Anfahrhilfe "Funktionsstatus des Berganfahrassistenten
MQB: Auswertung im Getriebe zwecks Standabkopplung";
CM_ SG_ 262 ESP_HDC_aktiv "MQB und AU57x Allroad: Mit diesem Statusbit wird eine gerade aktive Regelung des Bergabfahrassistenten (Hill Descent Control) signalisiert.";
CM_ SG_ 262 ESP_StartStopp_Info "Stopp-Freigabe und Start-Anforderung an den Start-Stopp-Koordinator";
CM_ SG_ 262 ESP_Eingr_HL "wird von QSP und Neigungsanzeige verwendet

Flag wird vom ESP gesetzt, sobald aufgrund eines ESP-Eingriffs am Rad aktiv Druck aufgebaut wird.
Frühestens mit öffnen des Ventils und spätestens bei einem Bremsmoment von 100Nm. Flag bleibt solange gesetzt ";
CM_ SG_ 262 ESP_Eingr_HR "wird von QSP und Neigungsanzeige verwendet

Flag wird vom ESP gesetzt, sobald aufgrund eines ESP-Eingriffs am Rad aktiv Druck aufgebaut wird.
Frühestens mit öffnen des Ventils und spätestens bei einem Bremsmoment von 100Nm. Flag bleibt solange gesetzt ";
CM_ SG_ 262 ESP_Eingr_VL "wird von QSP und Neigungsanzeige verwendet

Flag wird vom ESP gesetzt, sobald aufgrund eines ESP-Eingriffs am Rad aktiv Druck aufgebaut wird.
Frühestens mit öffnen des Ventils und spätestens bei einem Bremsmoment von 100Nm. Flag bleibt solange gesetzt ";
CM_ SG_ 262 ESP_Eingr_VR "wird von QSP und Neigungsanzeige verwendet

Flag wird vom ESP gesetzt, sobald aufgrund eines ESP-Eingriffs am Rad aktiv Druck aufgebaut wird.
Frühestens mit öffnen des Ventils und spätestens bei einem Bremsmoment von 100Nm. Flag bleibt solange gesetzt ";
CM_ SG_ 262 ESP_BKV_Unterdruck "Der maximale Wert wird auf 1012 mbar begrenzt.
Dieses Signal wird im AU64x nicht unterstützt.

Hinweis: Auch bei nicht verbautem BKV-Unterdrucksensor könnte während der Initialisierung der Initialisierungswert gesendet werden.";
CM_ SG_ 262 ESP_Autohold_aktiv "Rückmeldung an EPB, dass Autohold aktiv ist.";
CM_ SG_ 262 ESP_FStatus_Anfahrhilfe "Bei gesetztem Bit steht die Funktion Berganfahrassistent (Hillhold) nicht zur Verfügung";
CM_ SG_ 262 ESP_Verz_EPB_aktiv "Bei gesetztem Bit wird die Verzögerungsanforderung von EPB umgesetzt.";
CM_ SG_ 262 ECD_Bremslicht "Bremslichtansteuerung durch ECD-Funktion";
CM_ SG_ 262 ESP_Verzoeg_EPB_verf "Bei gesetztem Bit ist der Verzögerungsregeler für EPB verfügbar.";
CM_ SG_ 262 ESP_Status_Bremsdruck "MLB: Bei gesetztem Bit liegt p > ca. 2 bar an, hervorgerufen durch Fahrer, ASR, FZR, ECD, Bremsregler ... bei Abfall des Bits ist p < X bar, bei aktivem ECD-Eingriff Ende des Eingriffs 

Weiterführende Informationen im Lastenheft spezifiziert und in der";
CM_ SG_ 262 ESP_Anforderung_EPB "ESP fordert von der EPB Öffnen bzw. Schliessen an. Notwendig wegen Autohold-Funktion.";
CM_ BO_ 286 "ab MQB mit DLC 8";
CM_ SG_ 286 ESP_08_CRC "Für MLB:
'Berechnung siehe Lastenheft 'Kommunikationsabsicherung für FlexRay und CAN''

Ab MQB und MLBevo:
'Berechnung siehe Lastenheft 'End-to-End Kommunikationsabsicherung''

Endwerte siehe Begleitdokument 'S-PDU Kennungsfolgen'";
CM_ SG_ 286 ESP_ANB_CM_Rueckk_Umsetz "Das Signal dient als Rückmeldung zum ACC, dass eine angeforderte ANB-CM durchgeführt wird. Die positive Rückmeldung löst u.a. eine entsprechende Fahrerinformation im Kombiinstrument aus";
CM_ SG_ 286 ESP_Konsistenz_ACC_Botschaft "Rückmeldung zum Sender der Verzögerungsanforderung ACC bezüglich Prüfung CHK/CRC, BZ und langer Timeout. Wird auch gesetzt bei einer Verzögerungsanforderung größer als eine applizierbare Schwelle.

Im D4/C7: Botschaft ACC_05
Im MQB: Botschaft ACC_07";
CM_ SG_ 286 ESP_Stillstandsphase_erschoepft "Rückmeldung vom ESP, dass eine angefordertes sicheres Halten im Stillstand nicht mehr länger möglich ist.";
CM_ SG_ 286 ESP_ZT_Rueckk_Umsetz "Das Signal dient als Rückmeldung zum ACC, dass eine angeforderte Zielbremsung/Teilbremsung durchgeführt wird. Die positive Rückmeldung löst u.a. eine entsprechende Fahrerinformation im Kombiinstrument aus";
CM_ SG_ 286 ESP_Tuerkontakt_Fahrertuer "Logischer Pegel der HW-Leitung zum Türkontaktschalter im ESP-SG.
0 > Schalter geschlossen
1 > Schalter offen

Ungefilterter und unplausibilisierter Status der HW-Leitung vom Fahrertür-Türkontaktschalter zum ESP.
Redundanz für Systemsicherheit notwend";
CM_ SG_ 286 ESP_Abrutschen_Stillstand "Das ESP teilt über dieses Bit mit, dass ein Abrutschen im Stillstand erkannt wurde.

Im MQB wird das Signal nicht unterstützt!";
CM_ SG_ 286 ESP_Fahrer_tritt_ZBR_Schw "Rückmeldung des ESP an AWV, ob der Fahrer die aktuell gültige ZBR-Schwelle übertritt";
CM_ SG_ 286 ESP_QBit_v_ref "QBit der Referenzgeschwindigkeit ESP_v_ref. Gesetzt bei Ersatzwert, Init oder Fehler.
Detailinformationen zu dem Signal sind dem Lastenheft 'Signalexport - Funktionale Anforderungen an ESP' zu entnehmen - Signal ESP_St_v_fzg_ref";
CM_ SG_ 286 ESP_v_ref_Fahrtrichtung "Signal stellt die Informationen über die Fahrtrichtung des Fahrzeuges dar. Sie wird als Vorzeichen der Referenzgeschwindigkeit ESP_v_ref interpretiert und basiert auf den Drehrichtungen der Räder.
Detailinformationen zu dem Signal sind dem Lastenheft 'Si";
CM_ SG_ 286 ESC_Bremsdruckgradient "Das Signal zeigt den vom Fahrer gedruckten Bremsdruckgradienten";
CM_ SG_ 286 ESP_v_ref "MLBevo:
Signal wird nur von einem BOSCH ESP System zur Verfügung gestellt. Exklusives Signal vom BOSCH ESP zum BOSCH Airbag für ROSEII Funktion und für Fahrwerkregelsysteme. 
Verwendung nur nach vorheriger Abstimmung mit den verantwortlichen EF Fachbere";
CM_ SG_ 278 ESP_10_CRC "Für MLB:
'Berechnung siehe Lastenheft 'Kommunikationsabsicherung für FlexRay und CAN''

Ab MQB und MLBevo:
'Berechnung siehe Lastenheft 'End-to-End Kommunikationsabsicherung''

Endwerte siehe Begleitdokument 'S-PDU Kennungsfolgen'

Wird im Projekt";
CM_ SG_ 278 ESP_10_BZ "Botschaftszähler

Wird im Projekt D4 und D4Hybrid nicht verwendet!  Wird im D4 PA verwendet";
CM_ SG_ 278 ESP_QBit_Wegimpuls_VL "Qualifizierungsbit Wegimpulszähler VL

Wird im Projekt D4 und D4Hybrid nicht verwendet!  Wird im D4 PA verwendet";
CM_ SG_ 278 ESP_QBit_Wegimpuls_VR "Qualifizierungsbit Wegimpulszähler VR

Wird im Projekt D4 und D4Hybrid nicht verwendet!  Wird im D4 PA verwendet";
CM_ SG_ 278 ESP_QBit_Wegimpuls_HL "Qualifizierungsbit Wegimpulszähler HL

Wird im Projekt D4 und D4Hybrid nicht verwendet!  Wird im D4 PA verwendet";
CM_ SG_ 278 ESP_QBit_Wegimpuls_HR "Qualifizierungsbit Wegimpulszähler HR

Wird im Projekt D4 und D4Hybrid nicht verwendet!  Wird im D4 PA verwendet";
CM_ SG_ 278 ESP_Wegimpuls_VL "Wegimpulszähler VL.
Anzahl der Wegimpulse Vorderrad links (steigende und fallende Flanke)
Zähler läuft grundsätzlich vorwärts, auch bei Rückwärtsfahrt.
Nach SG-Reset ist immer, ohne Ausnahme, 1mal der Init Wert 1021 zu senden.

Wird im Projekt D4 und";
CM_ SG_ 278 ESP_Wegimpuls_VR "Wegimpulszähler VR.
Anzahl der Wegimpulse Vorderrad rechts (steigende und fallende Flanke)
Zähler läuft grundsätzlich vorwärts, auch bei Rückwärtsfahrt.
Nach SG-Reset ist immer, ohne Ausnahme, 1mal der Init Wert 1021 zu senden.

Wird im Projekt D4 un";
CM_ SG_ 278 ESP_Wegimpuls_HL "Wegimpulszähler HL.
Anzahl der Wegimpulse Hinterrad links (steigende und fallende Flanke)
Zähler läuft grundsätzlich vorwärts, auch bei Rückwärtsfahrt.
Nach SG-Reset ist immer, ohne Ausnahme, 1mal der Init Wert 1021 zu senden.

Wird im Projekt D4 und";
CM_ SG_ 278 ESP_Wegimpuls_HR "Wegimpulszähler HR.
Anzahl der Wegimpulse Hinterrad rechts (steigende und fallende Flanke)
Zähler läuft grundsätzlich vorwärts, auch bei Rückwärtsfahrt.
Nach SG-Reset ist immer, ohne Ausnahme, 1mal der Init Wert 1021 zu senden.

Wird im Projekt D4 un";
CM_ SG_ 278 ESP_VL_Fahrtrichtung "Drehrichtung Rad VL

Weiterführende Informationen im Lastenheft spezifiziert und in der entsprechenden Fachabteilung zu erfragen.

Wird im Projekt D4 und D4Hybrid nicht verwendet!  Wird im D4 PA verwendet";
CM_ SG_ 278 ESP_VR_Fahrtrichtung "Drehrichtung Rad VR

Weiterführende Informationen im Lastenheft spezifiziert und in der entsprechenden Fachabteilung zu erfragen.

Wird im Projekt D4 und D4Hybrid nicht verwendet!  Wird im D4 PA verwendet";
CM_ SG_ 278 ESP_HL_Fahrtrichtung "Drehrichtung Rad HL

Weiterführende Informationen im Lastenheft spezifiziert und in der entsprechenden Fachabteilung zu erfragen.

Wird im Projekt D4 und D4Hybrid nicht verwendet!  Wird im D4 PA verwendet";
CM_ SG_ 278 ESP_HR_Fahrtrichtung "Drehrichtung Rad HR

Weiterführende Informationen im Lastenheft spezifiziert und in der entsprechenden Fachabteilung zu erfragen.

Wird im Projekt D4 und D4Hybrid nicht verwendet!  Wird im D4 PA verwendet";
CM_ BO_ 418 "MLBevo verlangsamte 100ms-Botscahft";
CM_ SG_ 418 ESP_15_CRC "Für MLB:
'Berechnung siehe Lastenheft 'Kommunikationsabsicherung für FlexRay und CAN''

Ab MQB und MLBevo:
'Berechnung siehe Lastenheft 'End-to-End Kommunikationsabsicherung''

Endwerte siehe Begleitdokument 'S-PDU Kennungsfolgen'

Wird im Projekt";
CM_ SG_ 418 ESP_15_BZ "Botschaftszähler";
CM_ SG_ 418 HMS_P_beibehalten_GE "Fordert das Getriebe auf in Stellung 'P' zu bleiben.";
CM_ SG_ 418 HMS_Konsistenz_GE "Zeigt an, ob die Kommunikation und die Anforderungen plausibel sind.";
CM_ SG_ 418 HMS_Konsistenz_IPA "Zeigt an, ob die Kommunikation und die Anforderungen plausibel sind.
";
CM_ SG_ 418 HMS_Konsistenz_EBKV "Zeigt an, ob die Kommunikation und die Anforderungen plausibel sind.
";
CM_ SG_ 418 HMS_Konsistenz_RCTA "Zeigt an, ob die Kommunikation und die Anforderungen plausibel sind.";
CM_ SG_ 418 HMS_Konsistenz_STA "Zeigt an, ob die Kommunikation und die Anforderungen plausibel sind.";
CM_ SG_ 418 HMS_Konsistenz_MO "Zeigt an, ob die Kommunikation und die Anforderungen plausibel sind.";
CM_ SG_ 418 HMS_halten_nicht_verfuegbar "Rueckmeldung HMS-Teilfunktion 'Halten' nicht verfuegbar.";
CM_ SG_ 418 NL_PRIM_STP_01_Status "Das Primär- Bremsregelsystem übermittelt seinen Systemstatus an zFAS und Sekundär- Bremsregelsystem. 

Der Staupilot ermittelt sich über den Status des Primär-und des Sekundärbremsregelsystems den Gesamtzustand des Notlaufreglers. ";
CM_ SG_ 418 HMS_Notstopp_Status "Statusinformation des Notstoppsystems an die beteiligten Systeme.";
CM_ SG_ 418 HMS_parken_nicht_verfuegbar "Rueckmeldung HMS-Teilfunktionen 'Parken' nicht verfuegbar.";
CM_ SG_ 418 HMS_Anforderung_GE "Fordert vom Getriebe bestimmte Schaltstellungen an.";
CM_ SG_ 418 HMS_Systemstatus "Zeigt den aktuellen Systemstatus des HMS an.";
CM_ SG_ 418 HMS_Stillstand "Das Signal zeigt, basierend auf den vier ESP-Raddrehzahlinformatioen, gefiltert und/oder entprellt mehrstufig den Fahrzeuggeschwindigkeitszustand an.";
CM_ SG_ 418 HMS_aktives_System "Zeigt an, von welchem System die Anforderung gerade umgesetzt wird.";
CM_ SG_ 418 HMS_Konsistenz_HVLM "Zeigt an, ob die Kommunikation und die Anforderungen plausibel sind.";
CM_ SG_ 418 HMS_Konsistenz_ACC "Zeigt an, ob die Kommunikation und die Anforderungen plausibel sind.";
CM_ SG_ 418 HMS_Fehlerstatus "Zeigt den Fehlerstatus des Haltemanagementsystems HMS an.
Details zu den Werten 3/4:
3=Systemeinschränkung, Parken EPB oder GSG nicht möglich
4=Systemstörung bzw. Parken EPB und GSG nicht möglich  ";
CM_ SG_ 418 ESP_Index_Haltemoment "Zeigt an, ob das Summen-Radmoment von ESP_Haltemoment ein Bremsmoment (bergab) oder ein Antriebsmoment (bergauf) darstellt.";
CM_ SG_ 418 ESP_Haltemoment "Zeigt in Abhängigkeit von ESP_Index_Haltemoment das notwendige Summen-Radmoment an (bergab: Bremsmoment; bergauf: Antriebsmoment), das mindestens notwendig ist um das Fahrzeug an der aktuellen Neigung zu halten.";
CM_ SG_ 178 ESP_HL_Radgeschw_02 "Radgeschwindigkeit hinten links";
CM_ SG_ 178 ESP_HR_Radgeschw_02 "Radgeschwindigkeit hinten rechts";
CM_ SG_ 178 ESP_VL_Radgeschw_02 "Radgeschwindigkeit vorne links";
CM_ SG_ 178 ESP_VR_Radgeschw_02 "Radgeschwindigkeit vorne rechts";
CM_ BO_ 1629 "neu im MQB";
CM_ SG_ 1629 ESP_20_CRC "Für MLB:
'Berechnung siehe Lastenheft 'Kommunikationsabsicherung für FlexRay und CAN''

Ab MQB und MLBevo:
'Berechnung siehe Lastenheft 'End-to-End Kommunikationsabsicherung''

Endwerte siehe Begleitdokument 'S-PDU Kennungsfolgen'";
CM_ SG_ 1629 BR_Systemart "Identifikation des verbauten Bremssystems

Dient dem Kombi zur Plausibilisierung";
CM_ SG_ 1629 ESP_SpannungsAnf_02 "Forderung des ESP-SG's zur Spannungsanhebung.";
CM_ SG_ 1629 ESP_Zaehnezahl "Konstanter Wert der Zähnezahl des verwendeten Impulsrades wird ausgegeben, jeder Empfänger der Wegimpulse muss die Zähnezahl einlesen, um eine volle Umdrehung des Rades zu erkennen. 

Weiterführende Informationen im Lastenheft spezifiziert und in der en";
CM_ SG_ 1629 ESP_Charisma_FahrPr "MLBevo: Aktuelles Fahrprogramm des Charisma-Teilnehmers (siehe Systemlastenheft Drive Select)
MQB: Istwert der Kennlinie (siehe Systemlastenheft MQB FPA)";
CM_ SG_ 1629 ESP_Charisma_Status "Systemstatus des Charismateilnehmers

Wert 0x3 ist nur für Fahrzeuge ab MQB relevant";
CM_ SG_ 1629 ESP_Wiederstart_Anz_01 "Dieses Signal gibt die detaillierte Begründung für einen Wiederstart vom Bremsensteuergerät an. ";
CM_ SG_ 1629 ESP_Wiederstart_Anz_02 "Dieses Signal gibt die detaillierte Begründung für einen Wiederstart vom Bremsensteuergerät an. ";
CM_ SG_ 1629 ESP_Wiederstart_Anz_03 "Dieses Signal gibt die detaillierte Begründung für einen Wiederstart vom Bremsensteuergerät an. ";
CM_ SG_ 1629 ESP_Wiederstart_Anz_04 "Dieses Signal gibt die detaillierte Begründung für einen Wiederstart vom Bremsensteuergerät an.";
CM_ SG_ 1629 ESP_Stoppverbot_Anz_01 "Dieses Signal gibt die detaillierte Begründung für ein Stoppverbot vom Bremsensteuergerät an.";
CM_ SG_ 1629 ESP_Stoppverbot_Anz_02 "Dieses Signal gibt die detaillierte Begründung für ein Stoppverbot vom Bremsensteuergerät an.";
CM_ SG_ 1629 ESP_Stoppverbot_Anz_03 "Dieses Signal gibt die detaillierte Begründung für ein Stoppverbot vom Bremsensteuergerät an.";
CM_ SG_ 1629 ESP_Stoppverbot_Anz_04 "Dieses Signal gibt die detaillierte Begründung für ein Stoppverbot vom Bremsensteuergerät an.";
CM_ SG_ 1629 ESP_Stoppverbot_Anz_05 "Dieses Signal gibt die detaillierte Begründung für ein Stoppverbot vom Bremsensteuergerät an.";
CM_ SG_ 1629 ESP_Stoppverbot_Anz_06 "Dieses Signal gibt die detaillierte Begründung für ein Stoppverbot vom Bremsensteuergerät an.";
CM_ SG_ 1629 ESP_Stoppverbot_Anz_07 "Dieses Signal gibt die detaillierte Begründung für ein Stoppverbot vom Bremsensteuergerät an.";
CM_ SG_ 1629 ESP_Stoppverbot_Anz_Std "Dieses Signal gibt die detaillierte Begründung für ein Stoppverbot vom Bremsensteuergerät an.";
CM_ SG_ 1629 ESP_Dachrelingsensor "Erkennung auf Verbau des Dachrelingsensors und Dachquerträger.";
CM_ SG_ 1629 ESP_Stoppverbot_Anz_08 "Dieses Signal gibt die detaillierte Begründung für ein Stoppverbot vom Bremsensteuergerät an.";
CM_ SG_ 1629 HDC_Charisma_FahrPr "MLBevo: Aktuelles Fahrprogramm des Charisma-Teilnehmers (siehe Systemlastenheft Drive Select)
MQB: Istwert der Kennlinie (siehe Systemlastenheft MQB FPA)";
CM_ SG_ 1629 HDC_Charisma_Status "Systemstatus des Charismateilnehmers

Wert 0x3 ist nur für Fahrzeuge ab MQB relevant";
CM_ SG_ 1629 BR_QBit_Reifenumfang "Gesetzt bei Ersatzwert, Init oder Fehler.";
CM_ SG_ 1629 BR_Reifenumfang "Mittlerer Radumfang gerechnet in Millimeter.
Von der Bremse plausibilisierter Wert (Kopie von KBI_Reifenumfang wenn dieser plausibel) oder Ersatzwert aus Bremse wenn KBI_Reifenumfang unplausibel. Bitte das QBit beachten!";
CM_ BO_ 253 "Neue Momente im MQB
Struktur ab MQB mit CRC8 entstanden aus ESP_01";
CM_ SG_ 253 ESP_21_CRC "Für MLB:
'Berechnung siehe Lastenheft 'Kommunikationsabsicherung für FlexRay und CAN''

Ab MQB und MLBevo:
'Berechnung siehe Lastenheft 'End-to-End Kommunikationsabsicherung''

Endwerte siehe Begleitdokument 'S-PDU Kennungsfolgen'";
CM_ SG_ 253 BR_Eingriffsmoment "Einheitenloser Wert! Faktor in MO_Faktor_Momente_02 in Motor_Code_01 beachten!
Schnelle reduzierende (ASR) oder erhöhende (MSR) Momentanforderung an den Motor.";
CM_ SG_ 253 ESP_PLA_Bremseingriff "Signalisierung des aktiven Bremseingriffes des ESP aufgrund einer Bremsanforderung vom PLA.";
CM_ SG_ 253 ESP_Diagnose "MLB: Nach Diagnoseende wird ein SW-Reset ausgelöst welcher einen Kommunikatiosausfall für max. 150ms verursacht. Dies ist bei SG mit verschärfter Timeoutüberwachung (nicht nach Konzern-LH) zu beachten.

MQB: Weiterführende Informationen im Lastenheft sp";
CM_ SG_ 253 ESC_Reku_Freigabe "Mit diesem Bit wird die Rekuperation im Motorsteuergerät erlaubt. Bei Ausfall ESC wird Rekuperation nicht freigegeben.";
CM_ SG_ 253 ESC_v_Signal_Qualifier_High_Low "Das Qualifizerungssignal ESC_v_Signal_Qualifier_High_Low gibt eine Information über die Güte der vom Bremsregelsystem ausgegebenen Geschwindigkeitsinformation 'mittlere Geschwindigkeit', wobei Vertrauensbereiche für das ausgegebene Geschwindigkeitssignal ";
CM_ SG_ 253 ESP_Vorsteuerung "zur Unterscheidung zwischen ESP-Vorsteuermaßnahmen und ESP-Regeleingriffen";
CM_ SG_ 253 ESP_AWV3_Brems_aktiv "Teil-, Ziel- oder Notbremsung wird im ESP für AWV3 umgesetzt (das MSG nutzt diese Info für den Abwurf der GRA-Regelung).";
CM_ SG_ 253 OBD_Schlechtweg "Für Ausblendung der Zündaussetzererkennung im Motorsteuergerät (Otto). Bit wird gesetzt, wenn Rad-Drehbeschleunigung im ESP > Grenzwert ist. Vorteil gegenüber Radgeschwindigkeiten, dass ESP alle 2 ms dynamisch die Rad-Drehbeschleunigung errechnet und dem ";
CM_ SG_ 253 ESP_v_Signal "Geschwindigkeitssignal vom ABS/ASR oder ESP. Mittelwert der angetriebenen Räder.
Bei MSR oder ABS Eingriffen wird die ABS-Referenzgeschwindigkeit für >= 200ms eingespiegelt (Zeit wird mit Aktiv-Flanke der Funktionsbits getriggert)

MQB: Bei Frontantrie";
CM_ SG_ 253 ASR_Tastung_passiv "ASR deaktiviert oder Schwellen geändert (projektabhängig)
Weiterführende Informationen im Lastenheft spezifiziert und in der entsprechenden Fachabteilung zu erfragen.
";
CM_ SG_ 253 ESP_Tastung_passiv "ESP deaktiviert oder Schwellen geändert (projektabhängig)
Weiterführende Informationen im Lastenheft spezifiziert und in der entsprechenden Fachabteilung zu erfragen.";
CM_ SG_ 253 ESP_Systemstatus "Fehler steht für Stillegung ESP mit Fehlereintrag.

MLB: Flag wird bei Unterspannung im Stand bis einmalig 6km/h (AU48x) oder 10 km/h (AU641, AU57x) überschritten nicht gesetzt (Ausblendung Startvorgang)
Im AU64x, AU57x gilt ESP D4 Funktionsanforderung";
CM_ SG_ 253 ASR_Schalteingriff "Wunsch an das Getriebe während einer ASR Regelung

MLB: Es wird nur 0x0 und 0x1 genutzt

";
CM_ SG_ 253 ESP_Haltebestaetigung "Rückmeldung vom ESP-SG, dass das Fahrzeug aufgrund einer externen Bremsanforderung (z. B. ACC, PLA, ANB, o. ä.) abgebremst wurde und im Stillstand gehalten wird.";
CM_ SG_ 253 ESP_MKB_Abbruch_Geschw "Im Falle einer Multikollisionsbremsung teilt das ESP den Abbruch der MKB aufgrund der unteren Geschwindigkeitsschwelle mit.";
CM_ SG_ 253 ESP_QBit_v_Signal "Geschwindigkeit wird vom ABS/ASR oder ESP aus Ersatzwerten errechnet, wenn Bit gesetzt ist. Güte des Signals ist verändert.";
CM_ SG_ 253 ABS_Bremsung "Antiblockiersystem, Bit zeigt auch Druckabbau an (z.B. ESP hat zuviel Druck aufgebaut oder ungebremste Regelung auf Bahnübergang)
Weiterführende Informationen im Lastenheft spezifiziert und in der entsprechenden Fachabteilung zu erfragen.";
CM_ SG_ 253 ASR_Anf "MLB: Die Momentenanforderung 'ASR_MSR_Moment_schnell' und 'ASR_Moment_langsam' sind auszuführen
MQB: Die Momentenanforderung 'BR_Eingriffsmoment' ist auszuführen";
CM_ SG_ 253 MSR_Anf "MLB: Die Momentenanforderung 'ASR_MSR_Moment_schnell' ist auszuführen.
MQB: Die Momentenanforderung 'BR_Eingriffsmoment' ist auszuführen";
CM_ SG_ 253 EBV_Eingriff "Elektronische Bremskraftverteilung, aktueller Eingriff (Druckhalten, Druckabbau)

Im MLB: kein ABS / ESP-Eingriff ???";
CM_ SG_ 253 EDS_Eingriff "Elektronische Differentialsperre";
CM_ SG_ 253 ESP_Eingriff "Eingriff des Fahrdynamikreglers";
CM_ SG_ 253 ESP_ASP "MLB: Anhaenger-Stabilisierungs-Programm
MQB: Gespannstabilisierung";
CM_ SG_ 253 ESP_Anhaltevorgang_ACC_aktiv "Zeigt an, ob ACC-Anhaltevorgang aktiv";
CM_ SG_ 427 ESP_33_CRC "Für MLB:
'Berechnung siehe Lastenheft 'Kommunikationsabsicherung für FlexRay und CAN''

Ab MQB und MLBevo:
'Berechnung siehe Lastenheft 'End-to-End Kommunikationsabsicherung''

Endwerte siehe Begleitdokument 'S-PDU Kennungsfolgen'";
CM_ SG_ 427 ESC_AHW_aktiv "Rueckmeldung Anhaltewegregelung aktiv
";
CM_ SG_ 427 ESC_AHW_nicht_verfuegbar "Rueckmeldung Anhaltewegregelung nicht verfuegbar
";
CM_ SG_ 427 ESC_ANB_CM_aktiv "Rueckmeldung ANB_CM (Autom_Notbremsung_Collision_Mitigation) aktiv
";
CM_ SG_ 427 ESC_ANB_CM_nicht_verfuegbar "Rueckmeldung ANB_CM nicht verfuegbar
";
CM_ SG_ 427 ESC_Warnruck_aktiv "Rueckmeldung Warnruck aktiv";
CM_ SG_ 427 ESC_Warnruck_nicht_verfuegbar "Rueckmeldung Warnruck nicht verfuegbar";
CM_ SG_ 427 ESC_Prefill_aktiv "Rueckmeldung Prefill aktiv";
CM_ SG_ 427 ESC_Prefill_nicht_verfuegbar "Rueckmeldung Prefill nicht verfuegbar";
CM_ SG_ 427 ESC_HBA_aktiv "Rueckmeldung HBA (hydraulischer Bremsassistent) aktiv";
CM_ SG_ 427 ESC_HBA_nicht_verfuegbar "Rueckmeldung HBA (hydraulischer Bremsassistent) nicht verfuegbar";
CM_ SG_ 427 ESC_TSK_SRBM_Anf "Quittierung fuer TSK (SRBM=Summenradbremsmoment) Anforderung";
CM_ SG_ 427 ESC_TSK_SRBM_nicht_verfuegbar "Rueckmeldung TSK (SRBM= Summenradbremsmoment) nicht verfuegbar";
CM_ SG_ 427 ESC_Verz_Reg_aktiv "Rueckmeldung Verzoegerungsregelung aktiv";
CM_ SG_ 427 ESC_Verz_Reg_nicht_verfuegbar "Rueckmeldung Verzoegerungsregelung nicht verfuegbar";
CM_ SG_ 427 ESC_Verz_Reg_TB_nicht_verfuegbar "Rueckmeldung Verzoegerungsregelung (Teilbremsung) nicht verfuegbar";
CM_ SG_ 427 ESC_Verz_Reg_ZB_nicht_verfuegbar "Rueckmeldung Verzoegerungsregelung ZB (Zielbremsung) nicht verfuegbar";
CM_ SG_ 427 ESC_Bremslicht_unplausibel "Plausibilisierung der Rückmeldeinformation von BCM/AAG bezüglich Anforderung ESC_Bremslicht";
CM_ SG_ 427 ESC_Konsistenz_ACC "Rueckmeldung Konsistenz der ACC Botschaften";
CM_ SG_ 427 ESC_Konsistenz_AWV "Rueckmeldung Konsistenz der AWV Botschaften";
CM_ SG_ 427 ESC_Konsistenz_ARA "Rueckmeldung Konsistenz der ARA Botschaften";
CM_ SG_ 427 ESC_Konsistenz_IPA "Rueckmeldung Konsistenz der IPA Botschaften";
CM_ SG_ 427 ESC_Konsistenz_FCW "Rueckmeldung Konsistenz der FCW Botschaften";
CM_ SG_ 427 ESC_Konsistenz_NV "Rueckmeldung Konsistenz der NightVision Botschaften";
CM_ SG_ 427 ESC_Konsistenz_RCTA "Rueckmeldung Konsistenz der RCTA (Rear Cross Traffic Alert) Botschaften";
CM_ SG_ 427 ESC_Konsistenz_TSK "Rueckmeldung Konsistenz der TSK Botschaften";
CM_ SG_ 427 ESC_Konsistenz_vFGS "Rueckmeldung Konsistenz der vFGS Botschaften";
CM_ SG_ 427 ESC_Konsistenz_STA "Rueckmeldung Konsistenz der STA Botschaften";
CM_ SG_ 427 ESC_Fahrer_Bremsdruck_bestimmend "Das Signal zeigt an, dass der Fahrer Bremsdruck bestimmend ist";
CM_ SG_ 427 ESC_Konsistenz_EA "Rueckmeldung Konsistenz der EA Botschaften (HCA)";
CM_ SG_ 427 ESC_Konsistenz_BFF "Rückmeldung Konsistenz der Verzögerungsanforderung an das ESC-Steuergerät der Funktion 'Bremsen im freien Fahren' vom PDC_PLA_ARA-Steuergerät";
CM_ SG_ 427 ESC_Konsistenz_MKB "Rückmeldung Konsistenz für MKB-Verzögerungsanfoorderung";
CM_ SG_ 427 ESC_Verz_ASIL_Verfuegbarkeit "Gibt die Verfuegbarkeit der VZM-Regelung an, wobei folgende Zustaende beruecksichtigt werden:
-Nicht Verfuegbarkeit wegen Sonderbetriebszustaenden (z.B. Produktionsmodus)
-ueber VZM abgebaute Fahrzeuggeschwindigkeit bei Verzögerungen a>5m/s², wobei gilt";
CM_ SG_ 427 ESC_Pumpenanlauf_aktiv "Bestätigung der Durchführung eines Vorsteuerpumpenanlaufes";
CM_ SG_ 427 ESC_Konsistenz_AGW "Rückmeldung Konsistenz der AGW-Botschaft an das ESC.";
CM_ SG_ 427 ESC_Konsistenz_KAS "Rückmeldung Konsistenz für Kreuzungsassistent-Anforderungen";
CM_ SG_ 427 ESC_Konsistenz_PCF "Rückmeldung der Konsistenz der PCF-Anforderungen";
CM_ BO_ 264 "ab MQB mit CRC-8";
CM_ SG_ 264 Fahrwerk_01_CRC "Für MLB:
'Berechnung siehe Lastenheft 'Kommunikationsabsicherung für FlexRay und CAN''

Ab MQB und MLBevo:
'Berechnung siehe Lastenheft 'End-to-End Kommunikationsabsicherung''

Endwerte siehe Begleitdokument 'S-PDU Kennungsfolgen'";
CM_ SG_ 264 FA_Hoehenwerte_kalibriert "Legt fest, wie die Höhensensorwerte interpretiert werden müssen. Umschaltung kalibrierte Höhenwerte / Rohsignale in Byte 3-6

Achtung:
Im AUDI B8 Konstante: 0x1. D.h. es werden nur Rohwerte bedient!
Im AUDI D4 Konstante: 0x0. D.h. es werden nur Millim";
CM_ SG_ 264 FA_ESP_Zuschaltung "Zwangsweise Aktivierung der ESP-Funktionalität wird angefordert auch bei Passivtastung";
CM_ SG_ 264 FA_Hoehenwert_VL_00 "Aktueller Höhenwert (kalibriert) Vorne Links; ungefiltertes Signal
Einheit, Offset und Faktor sind abhänig von 'FA_Hoehenwert_kalibriert'

Achtung:
Wird im AUDI B8 nicht bedient";
CM_ SG_ 264 FA_Hoehenwert_VL_01 "Aktueller Höhenwert (Rohwerte) Vorne Links; ungefiltertes Signal
Einheit, Offset und Faktor sind abhänig von 'FA_Hoehenwert_kalibriert'";
CM_ SG_ 264 FA_Hoehenwert_VR_00 "Aktueller Höhenwert (kalibriert) Vorne Rechts; ungefiltertes Signal
Einheit, Offset und Faktor sind abhänig von 'FA_Hoehenwert_kalibriert'

Achtung:
Wird im AUDI B8 nicht bedient";
CM_ SG_ 264 FA_Hoehenwert_VR_01 "Aktueller Höhenwert (Rohwerte) Vorne Rechts; ungefiltertes Signal
Einheit, Offset und Faktor sind abhänig von 'FA_Hoehenwert_kalibriert'";
CM_ SG_ 264 FA_Hoehenwert_HL_00 "Aktueller Höhenwert (kalibriert) Hinten Links; ungefiltertes Signal
Einheit, Offset und Faktor sind abhänig von 'FA_Hoehenwert_kalibriert'

Achtung:
Wird im AUDI B8 nicht bedient";
CM_ SG_ 264 FA_Hoehenwert_HL_01 "Aktueller Höhenwert (Rohwerte) Hinten Links; ungefiltertes Signal
Einheit, Offset und Faktor sind abhänig von 'FA_Hoehenwert_kalibriert'";
CM_ SG_ 264 FA_Hoehenwert_HR_00 "Aktueller Höhenwert (kalibriert) Hinten Rechts; ungefiltertes Signal
Einheit, Offset und Faktor sind abhänig von 'FA_Hoehenwert_kalibriert'

Achtung:
Wird im AUDI B8 nicht bedient";
CM_ SG_ 264 FA_Hoehenwert_HR_01 "Aktueller Höhenwert (Rohwerte) Hinten Rechts; ungefiltertes Signal
Einheit, Offset und Faktor sind abhänig von 'FA_Hoehenwert_kalibriert'";
CM_ SG_ 1332 FCWO_Texte "Hinweisanzeige im Kombi 'Hauptdisplay' durch kamerabasierte Kollisionswarnung (FCWO)

3 = Demomodus --> nur für VW
4 = System_aus --> nur für PAG
6 = ESC_aus --> nur für AUDI";
CM_ SG_ 1332 FCWO_Warnung "Warnungsanzeige im Kombi 'Hauptdisplay' durch kamerabasierte Kollisionswarnung (FCWO)";
CM_ SG_ 1332 FCWP_Texte "Hinweisanzeige im Kombi 'Hauptdisplay' durch kamerabasierte Fußgängerwarnung (FCWP)

3 = Demomodus => nur für VW
4 = System aus => nur für PAG
6 = ESC aus => nur für AUDI";
CM_ SG_ 1332 FCWP_Warnung "Warnungsanzeige im Kombi 'Hauptdisplay' durch kamerabasierte Fußgängerwarnung (FCWP)";
CM_ SG_ 1332 FCWO_LED_Leiste "Ansteuerung der LED-Leiste durch kamerabasierte Kollisionswarnung (FCWO)";
CM_ SG_ 1332 FCWP_LED_Leiste "Ansteuerung der LED-Leiste durch kamerabasierte Fußgängerwarnung (FCWP)";
CM_ SG_ 1332 FCWO_Warnlevel "aktueller Warnlevel des kamerabasierten Forward-Collision-Warning";
CM_ SG_ 1332 FCWP_Warnlevel "Warnlevel der Fußgaengerwarnung";
CM_ SG_ 1332 FCWO_Charisma_FahrPr "MLBevo: Aktuelles Fahrprogramm des Charisma-Teilnehmers (siehe Systemlastenheft Drive Select)";
CM_ SG_ 1332 FCWO_Charisma_Status "Verfügbarkeit der Funktion FCWO für die Ansteuerung durch den Charisma-Koordinator";
CM_ SG_ 1332 FCWP_Charisma_Status "Verfügbarkeit der Funktion FCWP für die Ansteuerung durch den Charisma-Koordinator";
CM_ SG_ 1332 FCWP_Charisma_FahrPr "Aktuell eingestelltes Fahrprogramm der Funktion FCWP (Forward Collision Warning Pedestrian)";
CM_ SG_ 314 FCW_02_CRC "Checksumme";
CM_ SG_ 314 FCW_02_BZ "Botschaftszähler";
CM_ SG_ 314 FCWO_Ruck_Freigabe "Freigabit für die Warnruck-Anforderung an das ESP";
CM_ SG_ 314 FCWO_Ruckprofil "Anforderung an ESP, welcher Ruck aus einer Auswahl von max.
7 verschiedenen Ruckprofilen verwendet werden soll.
Eine Umsetzung der Ruckanforderung im ESP erfolgt nur mit gesetztem Bit 'FCWO_Ruck_ Freigabe'.";
CM_ SG_ 314 FCWO_Anf_Prefill "Anforderung an ESP, dass die Prefill-Funktion aktiviert werden soll.";
CM_ SG_ 314 FCWO_HBA_Param "Anforderung an ESP, welcher HBA-Parametersatz verwendet werden soll.";
CM_ SG_ 314 FCWP_Anf_Prefill "Anforderung an ESP, dass die Prefill-Funktion aktiviert werden soll.";
CM_ SG_ 314 FCWP_HBA_Param "Anforderung an ESP, welcher HBA-Parametersatz verwendet werden soll.";
CM_ SG_ 314 FCWP_Ruck_Freigabe "Freigabit für die Warnruck-Anforderung an das ESP";
CM_ SG_ 314 FCWP_Ruckprofil "Anforderung an ESP, welcher Ruck aus einer Auswahl von max. 7 verschiedenen Ruckprofilen verwendet werden soll. Eine Umsetzung der Ruckanforderung im ESP erfolgt nur mit gesetztem Bit 'FCWP_Ruck_ Freigabe'.";
CM_ SG_ 1605 FLA_aktiv "FLA aktiv  (200ms Task)";
CM_ SG_ 1605 FLA_ISP_defekt "FLA Innenspiegel defekt
interner Fehler  (200ms Task)";
CM_ SG_ 1605 FLA_Sensor_blockiert "FLA Sensor blockiert
Sichtbeeinträchtigung CMOS-Kamera  (200ms Task)";
CM_ SG_ 1605 FLA_Abblendursache "FLA Abblendursache
(20ms Task)";
CM_ SG_ 1605 FLA_Fernlicht_PWM "FLA PWM Vorgabe Fernlicht
(20ms Task)";
CM_ SG_ 1605 ISP_EC_Lichtwert_vorne "Innenspiegel: Lichtwert vorne
";
CM_ SG_ 1605 ISP_EC_Lichtwert_hinten "Innenspiegel: Lichtwert hinten
";
CM_ SG_ 1605 ISP_Himmelsrichtung "Himmelsrichtung Kompass im EC Spiegel
Wertebereich 0-29 (12°-Schritte, 0-348°)
";
CM_ SG_ 1605 ISP_Taste_betaetigt "ISP Taste betätigt
(200ms Task)";
CM_ SG_ 1605 ISP_EC_aktiv "Status Innenspiegel (EC-Spiegel)
";
CM_ SG_ 1605 ISP_Kompass_aktiv "Status Kompass Innenspiegel
";
CM_ SG_ 1605 FLA_Aufblenden "FLA Aufblenden (20ms Task)";
CM_ SG_ 1605 FLA_SAE_Mode "Rückmeldung an den Fahrer, über Wechsel in den SAE Modus --> wird nur für den amerikanischen Markt benötigt.";
CM_ BO_ 987 "Komfort -> Antrieb, Extended, Fahrwerk, Infotainment";
CM_ SG_ 987 ZV_verriegelt_extern_soll "Sollzustand: Verriegelung Fahrzeug aussen
";
CM_ SG_ 987 BH_Lichthupe "Betaetigung Lichthupe
";
CM_ SG_ 987 WFS_Klemmenfreigabe "Freigabe von der WFS zum Einschalten der Klemme 15 und Klemme S";
CM_ SG_ 987 ZV_Tankklappe_offen "Öffnungsstatus der Tankklappe";
CM_ SG_ 987 AAG_Anhaenger_abgesteckt "Anhaenger wurde bei Kl. 15 aus abgesteckt";
CM_ SG_ 987 BCM1_LDS_Stellung "Das Signal wird vom AFS / LWR Steuergerät empfangen und dient der Verifizierung der Lichtdrehschalterstellung. Intelligente Lichtfunktionen wie dyn. KL und gleitende Leuchtweite (GLW) nur bei LDS = 'AUTO'.";
CM_ SG_ 987 VS_Verdeck_Anf "



";
CM_ SG_ 987 VS_VD_entriegelt "

";
CM_ SG_ 987 ZV_HFS_offen "gespiegeltes Bit HFS_Tuer_geoeffnet TSG_HFS_1 Botschaft";
CM_ SG_ 987 ZV_HBFS_offen "gespiegeltes Bit HBFS_Tuer_geoeffnet TSG_HBFS_1 Botschaft";
CM_ SG_ 987 VS_VD_offen_ver "

";
CM_ SG_ 987 VS_VD_zu_ver "
";
CM_ SG_ 987 ZV_BT_offen "gespiegeltes Bit BT_Tuer_geoeffnet TSG_BT_1 Botschaft";
CM_ SG_ 987 BCM1_Rueckfahrlicht_Schalter "Rückfahrlichtschalter
ab MQB/ MLBevo: Die Ganginformation wird unentprellt übertragen, im AT-Getriebe wird evtl. kurzzeitig der R-Gang angezeigt. Eine Entprellung muß im Empfänger erfolgen (typisch 400ms).";
CM_ SG_ 987 ZV_FT_offen "gespiegeltes Bit FT_Tuer_geoeffnet TSG_FT_1 Botschaft";
CM_ SG_ 987 Wischer_vorne_aktiv "Status: Wischer vorne ";
CM_ SG_ 987 AAG_Anhaenger_erkannt "Erkennung Anhaenger ";
CM_ SG_ 987 BCM1_MH_Schalter "Motorhaubenkontakt";
CM_ SG_ 987 ZV_HD_offen "Status Heckdeckel
";
CM_ SG_ 987 Waschen_vorne_aktiv "Status: Waschen vorne aktiv 
";
CM_ SG_ 987 KL_Thermomanagement "Stufen des Thermomanagements;
Bei Klemme 15 AUS und erkannten Timeout zum Klimabedienteil (z.B. Klimabedienteil während des Motorsteuergeräte-Kommunikations-Nachlaufs bereits im NM-Zustand ¿Bus Sleep¿)
erfolgt keine Ansteuerung der Wasserpumpe durch die";
CM_ SG_ 987 WFS_Schluessel_Fahrberecht "Schlüsselnummer Fahrberechtigung
0 = ungueltig, xxxx = Schluessel-Nr.";
CM_ SG_ 987 BCM_Rueckfahrlicht_Anf "Anforderung Rückfahrlicht (Sollzustand). 
Das Signal wird entprellt (typisch 400ms) und bei KL15EIN gesendet. Das Signal ist unabhängig von der Position des Heckdeckels (kein Überhitzungsschutz).";
CM_ SG_ 987 WWSs_01_alt "Veraltet Bit für die LIN-Botschaft WWSs_01.

Betroffene Signale:

Wischer_vorne_aktiv";
CM_ SG_ 987 BCM_Tankklappensteller_Fehler "Fehler: nicht Funktionalität des Tankklappenstellers";
CM_ SG_ 987 ZV_verriegelt_soll "Fahrzeug Gesamtverriegelungsstatus Sollzustand für Ladestecker- und Ladeklappenverriegelung. ";
CM_ SG_ 987 ZV_Schluessel_Zugang "aktuelle Funkschlüsselnummer";
CM_ SG_ 987 WFS_ID_Geb_autorisiert_in_Kl15 "Authorisierung des Schlüssels im aktiven Klemme-15-Zyklus";
CM_ SG_ 987 BH_Fernlicht "Betaetigung Fernlicht
";
CM_ SG_ 987 BH_Blinker_li "Blinkerhebel Richtung links
";
CM_ SG_ 987 BH_Blinker_re "Blinkerhebel Richtung rechts
";
CM_ SG_ 987 BCM1_OBD_FStatus_ATemp "Fehlerstatus Umgebungstemperatursensor (OBD relevanter Sensor)
";
CM_ SG_ 987 BCM1_Aussen_Temp_ungef "ungefilterter Wert des Aussentemperatursensors
";
CM_ BO_ 988 "Antrieb, Fahrwerk -> Extended, Infotainment, Komfort";
CM_ SG_ 988 MO_QBit_Drehzahl_01 "AUDI D4: Zykluszeit: 10ms (siehe Zykluszeit schnell/Cycletime Fast)

Achtung:
Reduktion der Zykluszeit Motor_03 auf 10ms geplant.
Projektabhängig soll künftig mit 10ms gesendet werden.
Empfänger die in weiteren Konzern-Projekten eingesetzt werden müs";
CM_ SG_ 988 MKE_Texte "Systemhinweis und Sicherheitshinweis für Anzeige im Kombi";
CM_ SG_ 988 MKE_Stufe "Das Signal bildet die Müdigkeitsstufe im Kombi ab:
0 - deaktiviert
1 - nicht_verfügbar
2 - Stufe_1
3 - Stufe_2
4 - Stufe_3
5 - Stufe_4
6 - reserviert
7 - reserviert";
CM_ SG_ 988 MO_Drehzahl_01 "Im Fehlerfall wird die Motordrehzahl über die Nockenwellendrehzahl als Ersatzgrösse ausgegeben

Bei Parallelhybrid: Getriebeeingangsdrehzahl (=E-Maschinen Drehzahl)

Hinweis: 
Ehemaliger Fehlerwert 0xFFFF wird senderseitig nicht unterstützt. 
Diesen";
CM_ SG_ 988 GE_Fahrstufe "Fahrprogramm des Getriebes

Hinweis: Zwischenstellung '0x0' darf nur für Zustandswechsel P/R, R/N, N/D ausgegeben werden, nicht für D/S oder D/Tippgasse wegen Abschaltkriterium GRA/ACC";
CM_ SG_ 988 GE_reserv_Fahrstufe "reserviert, falls künftig Erweiterung von GE_Fahrstufe nötig";
CM_ SG_ 988 GE_Notlauf "AL/DL: Signalisiert wenn sich das Getriebe (bei DL ein Teilgetriebe) im Notlauf befindet.
VL: Wird gesetzt wenn kein Kraftschluss möglich ist.";
CM_ SG_ 988 ESP_Rollenmodus_Deaktivieren "Zwang zum Abbruch des Rollenmodus mit anschließender ESP-Vollfunktion.
MQB: Zwang zum Abbruch des Rollenmodus in allen Funktionsteilnehmern (Empfänger) mit anschließender ESP-Vollfunktion (Sender).
Signal wird vom ESP dauerhaft mit gültigen Werten bedat";
CM_ SG_ 988 GE_Freilauf_Status "Freilauf-Status-Signal vom Frailauf-Master an aktive Freilauf-Teilnehmer. In diesem Signal zeigt der Freilauf-Master an, welchen aktuellen Status die Freilauf-Betriebsstrategie hat.";
CM_ BO_ 991 "Antrieb, Fahrwerk, Komfort -> Extended";
CM_ SG_ 991 PLA_Status_PLA_EPS "Schnittstelle zum Austausch von Statusinformationen der internen Statusmaschine. Erforderlich zum Aktivieren der automatischen Lenkung.";
CM_ SG_ 991 IL_Innenlicht_aktiv "Status Innenlicht";
CM_ SG_ 991 FAS_Taster_Fehler "Fehlerstatus FAS Taster
";
CM_ SG_ 991 AAG_Bremslicht_H_def "Anhaenger Bremslicht defekt";
CM_ SG_ 991 LH_3_Bremsl_def "Fehlerstatus 3. Bremsleuchte
";
CM_ SG_ 991 LH_Bremsl_li_ges_def "Fehlerstatus Bremslicht hinten links (Detektion Totalausfall)
";
CM_ SG_ 991 LH_Bremsl_re_ges_def "Fehlerstatus Bremslicht hinten rechts (Detektion Totalausfall)";
CM_ SG_ 991 KL_Beschlagsgefahr "Beschlagsgefahr auf der Frontscheibe im Bereich des Spiegelfusses. Dient zur präventiven Ansteuerung der  Kamera-Scheibenheizung, um Kamera-Blindheit zu vermeiden
PHEV: volle Leistungsfreigabe 
HV Heizer und HV EKK bei Scheibenbeschlag ";
CM_ SG_ 991 FAS_Taster "Betaetigung FAS Taster
";
CM_ SG_ 991 SP_abklappen "Spiegel abklappen";
CM_ SG_ 991 SP_anklappen "Spiegel anklappen";
CM_ SG_ 991 KL_Umluftklappe_Status "Status Umluftklappe

";
CM_ SG_ 991 GE_amax_moeglich "AL/DL: maximal mögliche Beschleunigung unter Berücksichtigung aller möglichen Gänge.

Eine Reduzierung des maximalen Motormoments durch Efficiency wird in dem Signal berücksichtigt.

VL: maximal mögliche Beschleunigung bei Nenndrehzahl (Efficency wird";
CM_ SG_ 991 KL_Geblspng_Soll "Ausgabe des Sollwertes für die Spannung des Klimagebläsemotores vorne.







";
CM_ SG_ 991 EPS_Charisma_FahrPr "MLBevo: Aktuelles Fahrprogramm des Charisma-Teilnehmers (siehe Systemlastenheft Drive Select)
MQB: Istwert der Kennlinie (siehe Systemlastenheft MQB FPA)";
CM_ SG_ 991 GE_Zustand_Kuppltemp "Dieses Signal gibt den Temperaturzustand der Kupplung im DQ-Getriebe (z. Zt. DQ2x0, DQ500) an das ACC-System.";
CM_ SG_ 173 Getriebe_11_CRC "Für MLB:
'Berechnung siehe Lastenheft 'Kommunikationsabsicherung für FlexRay und CAN''

Ab MQB und MLBevo:
'Berechnung siehe Lastenheft 'End-to-End Kommunikationsabsicherung''

Endwerte siehe Begleitdokument 'S-PDU Kennungsfolgen'";
CM_ SG_ 173 Getriebe_11_BZ "Botschaftszähler";
CM_ SG_ 173 GE_MMom_Soll_02 "Momenteneingriff an den Motor.
Fordert vom MSG eine kurzfristige Reduzierung oder Anhebung des Moments.
Das Signal ist nur gültig in Kombination mit GE_MMom_Status (bei MQB) bzw. GE_MMom_Status_02 (bei MLBevo).

Achtung:
Einheitenloser Wert! Faktor i";
CM_ SG_ 173 GE_MMom_Vorhalt_02 "Anforderung einer Momentenreserve durch das Getriebe, gilt nur mit Freigabe durch 
GE_Freig_MMom_Vorhalt

Anforderung wird als Absolut-Wert umgesetzt, nicht als Relativ-Wert/Delta zum aktuellen Ist-Moment (d. h. eine Momentenreserve wird eingestellt, w";
CM_ SG_ 173 GE_Uefkt "Übertragungsfunktion des Getriebes
Drehzahlverhältnis = Eingangsdrehzahl / Ausgangsdrehzahl

AL: Wandlerverstärkung x Drehzahlverhältnis
VL: Drehzahlverhältnis
DL: Drehzahlverhältnis der aktiven und kraftschluß führenden Welle zum Abtrieb, bei Schalt";
CM_ SG_ 173 GE_Fahrstufe "Fahrprogramm des Getriebes

Hinweis: Zwischenstellung '0x0' darf nur für Zustandswechsel P/R, R/N, N/D ausgegeben werden, nicht für D/S oder D/Tippgasse wegen Abschaltkriterium GRA/ACC";
CM_ SG_ 173 GE_reserv_Fahrstufe "reserviert, falls künftig Erweiterung von GE_Fahrstufe nötig";
CM_ SG_ 173 GE_Schaltablauf "Das Signal zeigt den aktuellen Status eines Schaltvorgangs.

Bei Signal = 0 liegt kein Schaltvorgang vor.
Bei Signal =2 liegt die Befüllphase der zuschaltenden Kupplung bzw. 
                      die Vorbereitungsphase dazu vor.

Mit den unterschie";
CM_ SG_ 173 GE_Uefkt_unplausibel "Das Signal darf nur im Reku-Manager in Hybrid-Varianten verwendet werden.
Zeigt an, ob die Plausibilisierung Momenten-Verhältnis zu Drehzahl-Verhältnis i.O. ist.
Ein gesetztes Signal meldet eine unplausible GE_Uefkt bzw. GE_Uefkt_02.";
CM_ SG_ 173 GE_MMom_Status_02 "Das Signal qualifiziert GE_MMom_Soll_02 und gibt an, wie GE_MMom_Soll_02 umgesetzt werden soll.
Werte:
0= kein Eingriff
1=   absoluter reduzierender Eingriff auf Gesamt Antrieb nur über schnellen Pfad 
2 = absoluter, erhöhender Eingriff auf Gesamt-Ant";
CM_ SG_ 173 GE_Status_Kraftschluss "Zeigt den Ist-Status des Kraftschlusses im Getriebe.
(Anmerkung: meist wird damit der Zustand des Anfahrelements beschrieben, d.h. bei DL/DQ die Kupplung;  bei AQ/AL der Wandler incl. Überbrückungskupplung)
0 = offen, kein Kraftschluss
1 = offen mit Kr";
CM_ SG_ 173 GE_MMom_Status "Qualifiziert 
MLB: GE_MMom_Soll
MQB: GE_MMom_Soll_02";
CM_ SG_ 173 GE_Freig_MMom_Vorhalt "Freigabe für die Anforderung einer Momentenreserve durch das Getriebe über das Signal
MLB: GE_MMom_Vorhalt
MQB/MLBevo: GE_MMom_Vorhalt_02";
CM_ SG_ 173 GE_Verbot_Ausblendung "Verbot Einspritzausblendung für komfortable Schaltungen";
CM_ SG_ 173 GE_Zielgang "VL-Getriebe:
Signalisiert den Zielgang im manuellen Modus während eines Schaltvorgangs bzw. die momentane simulierte Gangstufe wenn kein Schaltvorgang aktiv ist. In den Fahrprogrammen 'D' und 'S' ist die Übersetzung variabel und somit wird dauerhaft 'Ist";
CM_ SG_ 299 GRA_ACC_01_CRC "Für MLB:
'Berechnung siehe Lastenheft 'Kommunikationsabsicherung für FlexRay und CAN''

Ab MQB und MLBevo:
'Berechnung siehe Lastenheft 'End-to-End Kommunikationsabsicherung''

Endwerte siehe Begleitdokument 'S-PDU Kennungsfolgen'";
CM_ SG_ 299 GRA_ACC_01_BZ "4bit Botschaftszaehler, wird mit jeder Sendebotschaft inkrementiert";
CM_ SG_ 299 GRA_Hauptschalter "Stellung des GRA/ACC-Hauptschalters: 
Bei gerastetem Hauptschalter:
0: Hauptschalter aus
1: Hauptschalter ein
Bei getastetem Hauptschalter:
0: Taster nicht betätigt
1: Taster betätigt";
CM_ SG_ 299 GRA_Abbrechen "GRA : aus mit speichern
ACC : Soft aus";
CM_ SG_ 299 GRA_Typ_Hauptschalter "Variante des GRA/ACC-Hauptschalters:
0: gerasteter Hauptschalter (bzw. Taster mit Speicherung des Status im SMLS (PAG))
1: getasteter Hauptschalter, keine Speicherung des Status im SMLS";
CM_ SG_ 299 GRA_Limiter "Stellung des Limiter-Tasters";
CM_ SG_ 299 GRA_Tip_Setzen "Tippschalter Set";
CM_ SG_ 299 GRA_Tip_Hoch "Tippschalter Tip Up / Geschwindigkeit erhöhen";
CM_ SG_ 299 GRA_Tip_Runter "Tippschalter Tip Down / Geschwindigkeit reduzieren";
CM_ SG_ 299 GRA_Tip_Wiederaufnahme "Tippschalter Wiederaufnahme";
CM_ SG_ 299 GRA_Verstellung_Zeitluecke "Verstellung der Zeitlücke für ACC

DIST -1 = Zeitluecke um 1 Stufe kleiner
DIST +1 = Zeitluecke um 1 Stufe groeßer
DIST Toggle = Zeitlücke um 1 Stufe kleiner, von kleinster Stufe auf größte Stufe";
CM_ SG_ 299 GRA_Codierung "Das Signal zeigt an, ob das Sende-SG (SMLS/MFL) auf GRA- oder ACC-Bedienteil codiert ist:
0: kein GRA- oder ACC Bedienteil
1: GRA-Bedienteil
2: ACC-Bedienteil
3: Limiter_Only-Bedienteil";
CM_ SG_ 299 GRA_Fehler "Das Signal zeigt an, dass das Sende-SG (SMLS/MFG) einen Defekt des GRA-Bedienteils erkannt hat und hierzu ein FSPE abgelegt wurde.";
CM_ SG_ 299 GRA_LIM_Taste_verfuegbar "Das Signal zeigt an, ob eine Limiter-Umschalttaste am jeweiligen GRA/ACC-Bedienelement vorhanden ist.";
CM_ SG_ 299 GRA_Tip_Stufe_2 "Signal zeigt an, dass der zweistufige GRA/ACC-Hebel (8_Positions_Bedienteil) in der 2. Tip-Stufe betätigt wird. Das Signal wird nur gleichzeitig mit dem Signal GRA_Tip_Hoch oder GRA_Tip_Runter gesetzt, wobei die Bits GRA_Tip_Hoch bzw. GRA_Tip_Runter die R";
CM_ SG_ 299 GRA_Typ_Bedienteil "Das Signal kennzeichnet die Variante des GRA/ACC-Bedienteils:
0: Init
1: 4-Positionen-Bedienteil (z.B. GRA im Blinkerhebel)
2: 6-Positionen-Bedienteil (GRA/ACC-Bedienteil mit separaten Stellungen für Set/Resume/TipUp/TipDown) 
3: 8-Positionen-Bediente";
CM_ SG_ 299 GRA_reserveByte4 "Zweck: Befüllen der reservierten Bitpositionen mit 0 (wg. LIN-Teilnehmer MFL)";
CM_ SG_ 299 GRA_reserveByte5 "Zweck: Befüllen der reservierten Bitpositionen mit 0 (wg. LIN-Teilnehmer MFL)";
CM_ SG_ 299 GRA_reserveByte6 "Zweck: Befüllen der reservierten Bitpositionen mit 0 (wg. LIN-Teilnehmer MFL)";
CM_ SG_ 299 GRA_reserveByte7 "Zweck: Befüllen der reservierten Bitpositionen mit 0 (wg. LIN-Teilnehmer MFL)";
CM_ SG_ 299 GRA_reserveByte8 "Zweck: Befüllen der reservierten Bitpositionen mit 0 (wg. LIN-Teilnehmer MFL)";
CM_ BO_ 294 "für MQB verändertes Sendeverhalten
(nicht IL-kompatibel, da zwei Inaktiv-Werte im Signal HCA_01_Status_HCA)";
CM_ SG_ 294 HCA_01_CRC "Für MLB:
'Berechnung siehe Lastenheft 'Kommunikationsabsicherung für Flexray und CAN''

Ab MQB und MLBevo:
'Berechnung siehe Lastenheft 'End-to-End Kommunikationsabsicherung'

Endwerte siehe Begleitdokument 'S-PDU Kennungsfolge'";
CM_ SG_ 294 HCA_01_Vib_Freq "Frequenz der Lenkradvibration";
CM_ SG_ 294 HCA_01_LM_Offset "Von HCA angefordertes Lenkmoment (Betrag)";
CM_ SG_ 294 EA_ACC_Sollstatus "Status-Anforderung ACC von Emergency Alert. Statuswechsel bei Flanke. Solange Wert=1, wird EA_ACC_Wunschgeschwindigkeit übernommen. Wert=2 führt zu Zustand ¿ACC_GRA_passiv¿";
CM_ SG_ 294 EA_Ruckprofil "Emergency Alert Anforderung an ESP, welcher Ruck verwendet werden soll. Eine Umsetzung der Ruckanforderung im ESP erfolgt nur mit gesetztem Bit 'EA_Ruckfreigabe'.";
CM_ SG_ 294 HCA_01_Sendestatus "Gibt den Sendestatus der HCA_01 an (notwendig für IL-Unterstützung)";
CM_ SG_ 294 HCA_01_LM_OffSign "Vorzeichen des HCA-Lenkmoments";
CM_ SG_ 294 HCA_01_Status_HCA "Statusinformation vom HCA und Manoevrierassistent für Handshakemechanismus mit der Lenkung";
CM_ SG_ 294 HCA_01_Vib_Amp "Momentenamplitude der Lenkradvibration";
CM_ SG_ 294 EA_Ruckfreigabe "Emergency Alert Freigabit für die Warnruck-Anforderung an das ESP";
CM_ SG_ 294 EA_ACC_Wunschgeschwindigkeit "Emergency Alert Anforderung neue Wunschgeschwindigkeit";
CM_ SG_ 1385 HVEM_NVLeistungEmpf "Maximaler Sollwert der aktuellen Leistung der NV-Seite des DCDC-Wandlers.";
CM_ SG_ 1385 HVEM_DCDC_Freigabe "Freigabe des DCDC wenn das Fzg nicht Fahrbereit ist.";
CM_ SG_ 1385 HVEM_KlimaMaxHVStrom "Kommuniziert dem Klimasteuergerät den max. Aufnahmestrom";
CM_ SG_ 1385 HVEM_Ladesteckerentr_Anf "Anforderung Ladestecker entriegeln nach ZV Auf Befehl";
CM_ SG_ 1385 HVEM_LeistungsAnf "Anforderung an NV-EM zur Erhöhung der Performance den Energieverbrauch auf der NV-Seite zu reduzieren.";
CM_ SG_ 1385 HVEM_Nachlad_Status "Status der Umsetzung der Nachladeanforderung der NV-Seite.";
CM_ SG_ 1385 HVEM_Abschaltstatus "Status der Reduzierungsstufen der Klimakomponenten beim Laden

0 = 100% (keine Reduzierung)
1 = 75%
2 = 50%
3 = 25%
7 = Init";
CM_ SG_ 1385 HVEM_Anf_ReichweiteNV "Anforderung an NV-EM zur Erhöhung der Reichweite den Energieverbrauch auf der NV-Seite zu reduzieren.";
CM_ SG_ 1385 HVEM_LadeklappenVerr_Anf "Anforderung eines Ver- oder Entriegelns der Ladedosenklappe über die ZV.";
CM_ SG_ 1385 HVEM_HV_Anf "HV Anforderung des HV Energiemanagements an das MSG";
CM_ SG_ 1385 HVEM_Text_1 "Meldung bei einem Anzeige SOC<10% ('Achtung Batterie laden. Funktionen eingeschränkt')";
CM_ SG_ 1385 HVEM_Nachladen_Anf "Anforderung für HV Laden bei gestecktem Stecker und deaktivierter Ladeanforderung";
CM_ SG_ 1385 HVEM_FreigabeKlimatisierung "Klimatisierung freigeben";
CM_ SG_ 1879 ISO_ACC_Req_Data "Diagnose Request Adaptive Cruise Control";
CM_ SG_ 1985 ISO_ACC_Resp_Data "Diagnose Response Adaptive Cruise Control";
CM_ SG_ 1840 ISO_FLA_Req_Data "Diagnose Request Fernlichtassistent";
CM_ SG_ 1946 ISO_FLA_Resp_Data "Diagnose Response Fernlichtassistent";
BA_DEF_ BO_  "DiagRequest" ENUM  "No","Yes";
BA_DEF_ BO_  "DiagResponse" ENUM  "No","Yes";
BA_DEF_ BO_  "DiagState" ENUM  "No","Yes";
BA_DEF_ BO_  "GenMsgChkConstant" HEX 0 4095;
BA_DEF_ BO_  "GenMsgCycleTime" INT 0 65535;
BA_DEF_ BO_  "GenMsgCycleTimeFast" INT 0 65535;
BA_DEF_ BO_  "GenMsgDelayTime" INT 0 100000;
BA_DEF_ BO_  "GenMsgILSupport" ENUM  "No","Yes";
BA_DEF_ BO_  "GenMsgNrOfRepetition" INT 0 100;
BA_DEF_ BO_  "GenMsgPDUConstants" STRING ;
BA_DEF_ BO_  "GenMsgSendType" ENUM  "Cyclic","not_used","not_used","not_used","not_used","not_used","not_used","IfActive","NoMsgSendType";
BA_DEF_ BO_  "GenMsgStartDelayTime" INT 0 100000;
BA_DEF_ BO_  "NmMessage" ENUM  "No","Yes";
BA_DEF_ BO_  "NmhMessage" ENUM  "No","Yes";
BA_DEF_ BO_  "MsgType" ENUM  "Application","NM ","NMH","TP2.0","ISO-TP ","BAP","EID","KS";
BA_DEF_ BO_  "VAGTP20_API" HEX 0 255;
BA_DEF_ BO_  "VAGTP20_DynConnection" ENUM  "No","Yes";
BA_DEF_ BO_  "VAGTP20_DynSetup" ENUM  "No","Yes";
BA_DEF_ BO_  "VAGTP20_StatConnection" ENUM  "No","Yes";
BA_DEF_ SG_  "GenSigActiveRepetitions" INT -2147483648 2147483647;
BA_DEF_ SG_  "GenSigInactiveValue" INT -2147483648 2147483647;
BA_DEF_ SG_  "GenSigSendType" ENUM  "Cyclic","OnWrite","OnWriteWithRepetition","OnChange","OnChangeWithRepetition","IfActive","IfActiveWithRepetition","NoSigSendType","OnChangeAndIfActive","OnChangeAndIfActiveWithRepetition";
BA_DEF_ SG_  "GenSigStartValue" INT -2147483648 2147483647;
BA_DEF_ SG_  "NWM-WakeupAllowed" ENUM  "No","Yes";
BA_DEF_ SG_  "GenSigFuncType" ENUM  "NoFunction","MsgCounter","CRC-8","XOR","XOR-2","DatedBit","SW-Kl15","CHK","Constant","Protocol","CRC-8-SAE_J1850";
BA_DEF_ SG_  "GenSigSwitchedByIgnition" ENUM  "No","Yes";
BA_DEF_ SG_  "Fehlerwert" HEX 0 2147483647;
BA_DEF_ SG_  "GenSigMissingSourceValue" HEX 0 2147483647;
BA_DEF_REL_ BU_SG_REL_  "GenSigTimeoutTime" INT 0 65535;
BA_DEF_DEF_REL_ "GenSigTimeoutTime" 0;
BA_DEF_DEF_  "DiagRequest" "No";
BA_DEF_DEF_  "DiagResponse" "No";
BA_DEF_DEF_  "DiagState" "No";
BA_DEF_DEF_  "GenMsgChkConstant" 0;
BA_DEF_DEF_  "GenMsgCycleTime" 0;
BA_DEF_DEF_  "GenMsgCycleTimeFast" 0;
BA_DEF_DEF_  "GenMsgDelayTime" 0;
BA_DEF_DEF_  "GenMsgILSupport" "No";
BA_DEF_DEF_  "GenMsgNrOfRepetition" 0;
BA_DEF_DEF_  "GenMsgPDUConstants" "";
BA_DEF_DEF_  "GenMsgSendType" "NoMsgSendType";
BA_DEF_DEF_  "GenMsgStartDelayTime" 0;
BA_DEF_DEF_  "NmMessage" "No";
BA_DEF_DEF_  "NmhMessage" "No";
BA_DEF_DEF_  "MsgType" "Application";
BA_DEF_DEF_  "VAGTP20_API" 0;
BA_DEF_DEF_  "VAGTP20_DynConnection" "No";
BA_DEF_DEF_  "VAGTP20_DynSetup" "No";
BA_DEF_DEF_  "VAGTP20_StatConnection" "No";
BA_DEF_DEF_  "GenSigActiveRepetitions" 0;
BA_DEF_DEF_  "GenSigInactiveValue" 0;
BA_DEF_DEF_  "GenSigSendType" "NoSigSendType";
BA_DEF_DEF_  "GenSigStartValue" 0;
BA_DEF_DEF_  "NWM-WakeupAllowed" "No";
BA_DEF_DEF_  "GenSigFuncType" "NoFunction";
BA_DEF_DEF_  "GenSigSwitchedByIgnition" "Yes";
BA_DEF_DEF_  "Fehlerwert" 0;
BA_DEF_DEF_  "GenSigMissingSourceValue" 0;
BA_ "GenMsgSendType" BO_ 262 0;
BA_ "GenMsgPDUConstants" BO_ 262 "0x07,0x07,0x07,0x07,0x07,0x07,0x07,0x07,0x07,0x07,0x07,0x07,0x07,0x07,0x07,0x07";
BA_ "GenMsgILSupport" BO_ 262 1;
BA_ "GenMsgCycleTime" BO_ 262 20;
BA_ "GenMsgChkConstant" BO_ 262 7;
BA_ "GenMsgSendType" BO_ 286 0;
BA_ "GenMsgPDUConstants" BO_ 286 "0xd2,0xd2,0xd2,0xd2,0xd2,0xd2,0xd2,0xd2,0xd2,0xd2,0xd2,0xd2,0xd2,0xd2,0xd2,0xd2";
BA_ "GenMsgILSupport" BO_ 286 1;
BA_ "GenMsgCycleTime" BO_ 286 20;
BA_ "GenMsgChkConstant" BO_ 286 210;
BA_ "GenMsgSendType" BO_ 278 0;
BA_ "GenMsgPDUConstants" BO_ 278 "0xac,0xac,0xac,0xac,0xac,0xac,0xac,0xac,0xac,0xac,0xac,0xac,0xac,0xac,0xac,0xac";
BA_ "GenMsgILSupport" BO_ 278 1;
BA_ "GenMsgCycleTime" BO_ 278 20;
BA_ "GenMsgChkConstant" BO_ 278 172;
BA_ "GenMsgSendType" BO_ 418 0;
BA_ "GenMsgPDUConstants" BO_ 418 "0xcb,0x47,0xd7,0xd2,0x56,0x3e,0x20,0xea,0x6e,0x6d,0x8c,0x1b,0xdf,0x49,0xaa,0xab";
BA_ "GenMsgILSupport" BO_ 418 1;
BA_ "GenMsgDelayTime" BO_ 418 20;
BA_ "GenMsgCycleTime" BO_ 418 200;
BA_ "GenMsgSendType" BO_ 178 0;
BA_ "GenMsgILSupport" BO_ 178 1;
BA_ "GenMsgCycleTime" BO_ 178 10;
BA_ "GenMsgSendType" BO_ 1629 0;
BA_ "GenMsgPDUConstants" BO_ 1629 "0xac,0xb3,0xab,0xeb,0x7a,0xe1,0x3b,0xf7,0x73,0xba,0x7c,0x9e,0x06,0x5f,0x02,0xd9";
BA_ "GenMsgILSupport" BO_ 1629 1;
BA_ "GenMsgDelayTime" BO_ 1629 200;
BA_ "GenMsgCycleTime" BO_ 1629 1000;
BA_ "GenMsgSendType" BO_ 253 0;
BA_ "GenMsgPDUConstants" BO_ 253 "0xb4,0xef,0xf8,0x49,0x1e,0xe5,0xc2,0xc0,0x97,0x19,0x3c,0xc9,0xf1,0x98,0xd6,0x61";
BA_ "GenMsgILSupport" BO_ 253 1;
BA_ "GenMsgCycleTime" BO_ 253 20;
BA_ "GenMsgSendType" BO_ 427 0;
BA_ "GenMsgPDUConstants" BO_ 427 "0x13,0x21,0x9b,0x6a,0x9a,0x62,0xd4,0x65,0x18,0xf1,0xab,0x16,0x32,0x89,0xe7,0x26";
BA_ "GenMsgILSupport" BO_ 427 1;
BA_ "GenMsgDelayTime" BO_ 427 20;
BA_ "GenMsgCycleTime" BO_ 427 200;
BA_ "GenMsgSendType" BO_ 264 0;
BA_ "GenMsgPDUConstants" BO_ 264 "0x09,0x09,0x09,0x09,0x09,0x09,0x09,0x09,0x09,0x09,0x09,0x09,0x09,0x09,0x09,0x09";
BA_ "GenMsgILSupport" BO_ 264 1;
BA_ "GenMsgCycleTime" BO_ 264 25;
BA_ "GenMsgChkConstant" BO_ 264 9;
BA_ "GenMsgSendType" BO_ 1332 0;
BA_ "GenMsgILSupport" BO_ 1332 1;
BA_ "GenMsgDelayTime" BO_ 1332 20;
BA_ "GenMsgCycleTime" BO_ 1332 200;
BA_ "GenMsgSendType" BO_ 314 0;
BA_ "GenMsgPDUConstants" BO_ 314 "0xb4,0x24,0x5a,0x8b,0xaa,0xb6,0xd5,0x97,0xb9,0x82,0x3d,0x96,0x7d,0x5d,0x64,0x9b";
BA_ "GenMsgILSupport" BO_ 314 1;
BA_ "GenMsgCycleTime" BO_ 314 20;
BA_ "GenMsgSendType" BO_ 1605 0;
BA_ "GenMsgILSupport" BO_ 1605 1;
BA_ "GenMsgDelayTime" BO_ 1605 20;
BA_ "GenMsgCycleTime" BO_ 1605 1000;
BA_ "GenMsgSendType" BO_ 987 0;
BA_ "GenMsgILSupport" BO_ 987 1;
BA_ "GenMsgDelayTime" BO_ 987 10;
BA_ "GenMsgCycleTime" BO_ 987 100;
BA_ "GenMsgSendType" BO_ 988 0;
BA_ "GenMsgILSupport" BO_ 988 1;
BA_ "GenMsgDelayTime" BO_ 988 10;
BA_ "GenMsgCycleTime" BO_ 988 50;
BA_ "GenMsgSendType" BO_ 991 0;
BA_ "GenMsgILSupport" BO_ 991 1;
BA_ "GenMsgDelayTime" BO_ 991 10;
BA_ "GenMsgCycleTime" BO_ 991 100;
BA_ "GenMsgSendType" BO_ 173 0;
BA_ "GenMsgPDUConstants" BO_ 173 "0x3f,0x69,0x39,0xdc,0x94,0xf9,0x14,0x64,0xd8,0x6a,0x34,0xce,0xa2,0x55,0xb5,0x2c";
BA_ "GenMsgILSupport" BO_ 173 1;
BA_ "GenMsgCycleTime" BO_ 173 50;
BA_ "GenMsgSendType" BO_ 299 0;
BA_ "GenMsgPDUConstants" BO_ 299 "0x6a,0x38,0xb4,0x27,0x22,0xef,0xe1,0xbb,0xf8,0x80,0x84,0x49,0xc7,0x9e,0x1e,0x2b";
BA_ "GenMsgILSupport" BO_ 299 1;
BA_ "GenMsgCycleTime" BO_ 299 30;
BA_ "GenMsgSendType" BO_ 294 0;
BA_ "GenMsgPDUConstants" BO_ 294 "0xda,0xda,0xda,0xda,0xda,0xda,0xda,0xda,0xda,0xda,0xda,0xda,0xda,0xda,0xda,0xda";
BA_ "GenMsgILSupport" BO_ 294 1;
BA_ "GenMsgCycleTimeFast" BO_ 294 20;
BA_ "GenMsgCycleTime" BO_ 294 1000;
BA_ "GenMsgChkConstant" BO_ 294 218;
BA_ "GenMsgSendType" BO_ 1385 0;
BA_ "GenMsgILSupport" BO_ 1385 1;
BA_ "GenMsgDelayTime" BO_ 1385 50;
BA_ "GenMsgCycleTime" BO_ 1385 500;
BA_ "MsgType" BO_ 1879 4;
BA_ "DiagRequest" BO_ 1879 1;
BA_ "MsgType" BO_ 1985 4;
BA_ "DiagResponse" BO_ 1985 1;
BA_ "MsgType" BO_ 1840 4;
BA_ "DiagRequest" BO_ 1840 1;
BA_ "MsgType" BO_ 1946 4;
BA_ "DiagResponse" BO_ 1946 1;
BA_ "MsgType" BO_ 1793 4;
BA_ "DiagState" BO_ 1793 1;
BA_ "MsgType" BO_ 1794 4;
BA_ "DiagState" BO_ 1794 1;
BA_ "MsgType" BO_ 1796 4;
BA_ "DiagState" BO_ 1796 1;
BA_ "MsgType" BO_ 1797 4;
BA_ "DiagState" BO_ 1797 1;
BA_ "MsgType" BO_ 1798 4;
BA_ "DiagState" BO_ 1798 1;
BA_ "MsgType" BO_ 1799 4;
BA_ "DiagState" BO_ 1799 1;
BA_ "MsgType" BO_ 1800 4;
BA_ "DiagState" BO_ 1800 1;
BA_ "GenSigSwitchedByIgnition" SG_ 262 ESP_05_CRC 0;
BA_ "GenSigFuncType" SG_ 262 ESP_05_CRC 2;
BA_ "GenSigSendType" SG_ 262 ESP_05_CRC 0;
BA_ "GenSigSwitchedByIgnition" SG_ 262 ESP_05_BZ 0;
BA_ "GenSigFuncType" SG_ 262 ESP_05_BZ 1;
BA_ "GenSigSendType" SG_ 262 ESP_05_BZ 0;
BA_ "GenSigSwitchedByIgnition" SG_ 262 ESP_QBit_Bremsdruck 0;
BA_ "GenSigStartValue" SG_ 262 ESP_QBit_Bremsdruck 1;
BA_ "GenSigSendType" SG_ 262 ESP_QBit_Bremsdruck 0;
BA_ "GenSigSwitchedByIgnition" SG_ 262 ESP_QBit_Fahrer_bremst 0;
BA_ "GenSigStartValue" SG_ 262 ESP_QBit_Fahrer_bremst 1;
BA_ "GenSigSendType" SG_ 262 ESP_QBit_Fahrer_bremst 0;
BA_ "GenSigSwitchedByIgnition" SG_ 262 ESP_Schwelle_Unterdruck 0;
BA_ "GenSigSendType" SG_ 262 ESP_Schwelle_Unterdruck 0;
BA_ "Fehlerwert" SG_ 262 ESP_Bremsdruck 1023;
BA_ "GenSigSwitchedByIgnition" SG_ 262 ESP_Bremsdruck 0;
BA_ "GenSigStartValue" SG_ 262 ESP_Bremsdruck 100;
BA_ "GenSigSendType" SG_ 262 ESP_Bremsdruck 0;
BA_ "GenSigSwitchedByIgnition" SG_ 262 ESP_Fahrer_bremst 0;
BA_ "GenSigSendType" SG_ 262 ESP_Fahrer_bremst 0;
BA_ "GenSigSwitchedByIgnition" SG_ 262 ESP_Verz_TSK_aktiv 0;
BA_ "GenSigSendType" SG_ 262 ESP_Verz_TSK_aktiv 0;
BA_ "GenSigSwitchedByIgnition" SG_ 262 ESP_Lenkeingriff_ADS 0;
BA_ "GenSigSendType" SG_ 262 ESP_Lenkeingriff_ADS 0;
BA_ "GenSigSwitchedByIgnition" SG_ 262 ESP_Konsistenz_TSK 0;
BA_ "GenSigSendType" SG_ 262 ESP_Konsistenz_TSK 0;
BA_ "GenSigSwitchedByIgnition" SG_ 262 ESP_Bremsruck_AWV2 0;
BA_ "GenSigSendType" SG_ 262 ESP_Bremsruck_AWV2 0;
BA_ "GenSigSwitchedByIgnition" SG_ 262 ESP_Konsistenz_AWV2 0;
BA_ "GenSigSendType" SG_ 262 ESP_Konsistenz_AWV2 0;
BA_ "GenSigSwitchedByIgnition" SG_ 262 ECD_Fehler 0;
BA_ "GenSigSendType" SG_ 262 ECD_Fehler 0;
BA_ "GenSigSwitchedByIgnition" SG_ 262 ECD_nicht_verfuegbar 0;
BA_ "GenSigStartValue" SG_ 262 ECD_nicht_verfuegbar 1;
BA_ "GenSigSendType" SG_ 262 ECD_nicht_verfuegbar 0;
BA_ "GenSigSwitchedByIgnition" SG_ 262 ESP_Status_Bremsentemp 0;
BA_ "GenSigSendType" SG_ 262 ESP_Status_Bremsentemp 0;
BA_ "GenSigSwitchedByIgnition" SG_ 262 ESP_Autohold_Standby 0;
BA_ "GenSigSendType" SG_ 262 ESP_Autohold_Standby 0;
BA_ "GenSigSwitchedByIgnition" SG_ 262 ESP_HDC_Standby 0;
BA_ "GenSigSendType" SG_ 262 ESP_HDC_Standby 0;
BA_ "GenSigSwitchedByIgnition" SG_ 262 ESP_HBA_aktiv 0;
BA_ "GenSigSendType" SG_ 262 ESP_HBA_aktiv 0;
BA_ "GenSigSwitchedByIgnition" SG_ 262 ESP_Prefill_ausgeloest 0;
BA_ "GenSigSendType" SG_ 262 ESP_Prefill_ausgeloest 0;
BA_ "GenSigSwitchedByIgnition" SG_ 262 ESP_Rueckwaertsfahrt_erkannt 0;
BA_ "GenSigSendType" SG_ 262 ESP_Rueckwaertsfahrt_erkannt 0;
BA_ "GenSigSwitchedByIgnition" SG_ 262 ESP_Status_Anfahrhilfe 0;
BA_ "GenSigSendType" SG_ 262 ESP_Status_Anfahrhilfe 0;
BA_ "GenSigSwitchedByIgnition" SG_ 262 ESP_HDC_aktiv 0;
BA_ "GenSigSendType" SG_ 262 ESP_HDC_aktiv 0;
BA_ "GenSigSwitchedByIgnition" SG_ 262 ESP_StartStopp_Info 0;
BA_ "GenSigSendType" SG_ 262 ESP_StartStopp_Info 0;
BA_ "GenSigSwitchedByIgnition" SG_ 262 ESP_Eingr_HL 0;
BA_ "GenSigSendType" SG_ 262 ESP_Eingr_HL 0;
BA_ "GenSigSwitchedByIgnition" SG_ 262 ESP_Eingr_HR 0;
BA_ "GenSigSendType" SG_ 262 ESP_Eingr_HR 0;
BA_ "GenSigSwitchedByIgnition" SG_ 262 ESP_Eingr_VL 0;
BA_ "GenSigSendType" SG_ 262 ESP_Eingr_VL 0;
BA_ "GenSigSwitchedByIgnition" SG_ 262 ESP_Eingr_VR 0;
BA_ "GenSigSendType" SG_ 262 ESP_Eingr_VR 0;
BA_ "Fehlerwert" SG_ 262 ESP_BKV_Unterdruck 255;
BA_ "GenSigSwitchedByIgnition" SG_ 262 ESP_BKV_Unterdruck 0;
BA_ "GenSigStartValue" SG_ 262 ESP_BKV_Unterdruck 254;
BA_ "GenSigSendType" SG_ 262 ESP_BKV_Unterdruck 0;
BA_ "GenSigSwitchedByIgnition" SG_ 262 ESP_Autohold_aktiv 0;
BA_ "GenSigSendType" SG_ 262 ESP_Autohold_aktiv 0;
BA_ "Fehlerwert" SG_ 262 ESP_FStatus_Anfahrhilfe 1;
BA_ "GenSigSwitchedByIgnition" SG_ 262 ESP_FStatus_Anfahrhilfe 0;
BA_ "GenSigSendType" SG_ 262 ESP_FStatus_Anfahrhilfe 0;
BA_ "GenSigSwitchedByIgnition" SG_ 262 ESP_Verz_EPB_aktiv 0;
BA_ "GenSigSendType" SG_ 262 ESP_Verz_EPB_aktiv 0;
BA_ "GenSigSwitchedByIgnition" SG_ 262 ECD_Bremslicht 0;
BA_ "GenSigSendType" SG_ 262 ECD_Bremslicht 0;
BA_ "GenSigSwitchedByIgnition" SG_ 262 ESP_Verzoeg_EPB_verf 0;
BA_ "GenSigSendType" SG_ 262 ESP_Verzoeg_EPB_verf 0;
BA_ "GenSigSwitchedByIgnition" SG_ 262 ESP_Status_Bremsdruck 0;
BA_ "GenSigSendType" SG_ 262 ESP_Status_Bremsdruck 0;
BA_ "GenSigSwitchedByIgnition" SG_ 262 ESP_Anforderung_EPB 0;
BA_ "GenSigSendType" SG_ 262 ESP_Anforderung_EPB 0;
BA_ "GenSigSwitchedByIgnition" SG_ 286 ESP_08_CRC 0;
BA_ "GenSigFuncType" SG_ 286 ESP_08_CRC 2;
BA_ "GenSigSendType" SG_ 286 ESP_08_CRC 0;
BA_ "GenSigSwitchedByIgnition" SG_ 286 ESP_08_BZ 0;
BA_ "GenSigFuncType" SG_ 286 ESP_08_BZ 1;
BA_ "GenSigSendType" SG_ 286 ESP_08_BZ 0;
BA_ "GenSigSwitchedByIgnition" SG_ 286 ESP_ANB_CM_Rueckk_Umsetz 0;
BA_ "GenSigSendType" SG_ 286 ESP_ANB_CM_Rueckk_Umsetz 0;
BA_ "GenSigSwitchedByIgnition" SG_ 286 ESP_Konsistenz_ACC_Botschaft 0;
BA_ "GenSigSendType" SG_ 286 ESP_Konsistenz_ACC_Botschaft 0;
BA_ "GenSigSwitchedByIgnition" SG_ 286 ESP_Stillstandsphase_erschoepft 0;
BA_ "GenSigSendType" SG_ 286 ESP_Stillstandsphase_erschoepft 0;
BA_ "GenSigSwitchedByIgnition" SG_ 286 ESP_ZT_Rueckk_Umsetz 0;
BA_ "GenSigSendType" SG_ 286 ESP_ZT_Rueckk_Umsetz 0;
BA_ "GenSigSwitchedByIgnition" SG_ 286 ESP_Tuerkontakt_Fahrertuer 0;
BA_ "GenSigSendType" SG_ 286 ESP_Tuerkontakt_Fahrertuer 0;
BA_ "GenSigSwitchedByIgnition" SG_ 286 ESP_Abrutschen_Stillstand 0;
BA_ "GenSigSendType" SG_ 286 ESP_Abrutschen_Stillstand 0;
BA_ "GenSigSwitchedByIgnition" SG_ 286 ESP_Fahrer_tritt_ZBR_Schw 0;
BA_ "GenSigSendType" SG_ 286 ESP_Fahrer_tritt_ZBR_Schw 0;
BA_ "GenSigSwitchedByIgnition" SG_ 286 ESP_QBit_v_ref 0;
BA_ "GenSigStartValue" SG_ 286 ESP_QBit_v_ref 1;
BA_ "GenSigSendType" SG_ 286 ESP_QBit_v_ref 0;
BA_ "GenSigSwitchedByIgnition" SG_ 286 ESP_v_ref_Fahrtrichtung 0;
BA_ "GenSigSendType" SG_ 286 ESP_v_ref_Fahrtrichtung 0;
BA_ "Fehlerwert" SG_ 286 ESC_Bremsdruckgradient 255;
BA_ "GenSigSwitchedByIgnition" SG_ 286 ESC_Bremsdruckgradient 0;
BA_ "GenSigStartValue" SG_ 286 ESC_Bremsdruckgradient 254;
BA_ "GenSigSendType" SG_ 286 ESC_Bremsdruckgradient 0;
BA_ "Fehlerwert" SG_ 286 ESP_v_ref 4095;
BA_ "GenSigSwitchedByIgnition" SG_ 286 ESP_v_ref 0;
BA_ "GenSigStartValue" SG_ 286 ESP_v_ref 4094;
BA_ "GenSigSendType" SG_ 286 ESP_v_ref 0;
BA_ "GenSigSwitchedByIgnition" SG_ 278 ESP_10_CRC 0;
BA_ "GenSigFuncType" SG_ 278 ESP_10_CRC 2;
BA_ "GenSigSendType" SG_ 278 ESP_10_CRC 0;
BA_ "GenSigSwitchedByIgnition" SG_ 278 ESP_10_BZ 0;
BA_ "GenSigFuncType" SG_ 278 ESP_10_BZ 1;
BA_ "GenSigSendType" SG_ 278 ESP_10_BZ 0;
BA_ "GenSigSwitchedByIgnition" SG_ 278 ESP_QBit_Wegimpuls_VL 0;
BA_ "GenSigStartValue" SG_ 278 ESP_QBit_Wegimpuls_VL 1;
BA_ "GenSigSendType" SG_ 278 ESP_QBit_Wegimpuls_VL 0;
BA_ "GenSigSwitchedByIgnition" SG_ 278 ESP_QBit_Wegimpuls_VR 0;
BA_ "GenSigStartValue" SG_ 278 ESP_QBit_Wegimpuls_VR 1;
BA_ "GenSigSendType" SG_ 278 ESP_QBit_Wegimpuls_VR 0;
BA_ "GenSigSwitchedByIgnition" SG_ 278 ESP_QBit_Wegimpuls_HL 0;
BA_ "GenSigStartValue" SG_ 278 ESP_QBit_Wegimpuls_HL 1;
BA_ "GenSigSendType" SG_ 278 ESP_QBit_Wegimpuls_HL 0;
BA_ "GenSigSwitchedByIgnition" SG_ 278 ESP_QBit_Wegimpuls_HR 0;
BA_ "GenSigStartValue" SG_ 278 ESP_QBit_Wegimpuls_HR 1;
BA_ "GenSigSendType" SG_ 278 ESP_QBit_Wegimpuls_HR 0;
BA_ "Fehlerwert" SG_ 278 ESP_Wegimpuls_VL 1023;
BA_ "GenSigSwitchedByIgnition" SG_ 278 ESP_Wegimpuls_VL 0;
BA_ "GenSigStartValue" SG_ 278 ESP_Wegimpuls_VL 1021;
BA_ "GenSigSendType" SG_ 278 ESP_Wegimpuls_VL 0;
BA_ "Fehlerwert" SG_ 278 ESP_Wegimpuls_VR 1023;
BA_ "GenSigSwitchedByIgnition" SG_ 278 ESP_Wegimpuls_VR 0;
BA_ "GenSigStartValue" SG_ 278 ESP_Wegimpuls_VR 1021;
BA_ "GenSigSendType" SG_ 278 ESP_Wegimpuls_VR 0;
BA_ "Fehlerwert" SG_ 278 ESP_Wegimpuls_HL 1023;
BA_ "GenSigSwitchedByIgnition" SG_ 278 ESP_Wegimpuls_HL 0;
BA_ "GenSigStartValue" SG_ 278 ESP_Wegimpuls_HL 1021;
BA_ "GenSigSendType" SG_ 278 ESP_Wegimpuls_HL 0;
BA_ "Fehlerwert" SG_ 278 ESP_Wegimpuls_HR 1023;
BA_ "GenSigSwitchedByIgnition" SG_ 278 ESP_Wegimpuls_HR 0;
BA_ "GenSigStartValue" SG_ 278 ESP_Wegimpuls_HR 1021;
BA_ "GenSigSendType" SG_ 278 ESP_Wegimpuls_HR 0;
BA_ "GenSigSwitchedByIgnition" SG_ 278 ESP_VL_Fahrtrichtung 0;
BA_ "GenSigStartValue" SG_ 278 ESP_VL_Fahrtrichtung 2;
BA_ "GenSigSendType" SG_ 278 ESP_VL_Fahrtrichtung 0;
BA_ "GenSigSwitchedByIgnition" SG_ 278 ESP_VR_Fahrtrichtung 0;
BA_ "GenSigStartValue" SG_ 278 ESP_VR_Fahrtrichtung 2;
BA_ "GenSigSendType" SG_ 278 ESP_VR_Fahrtrichtung 0;
BA_ "GenSigSwitchedByIgnition" SG_ 278 ESP_HL_Fahrtrichtung 0;
BA_ "GenSigStartValue" SG_ 278 ESP_HL_Fahrtrichtung 2;
BA_ "GenSigSendType" SG_ 278 ESP_HL_Fahrtrichtung 0;
BA_ "GenSigSwitchedByIgnition" SG_ 278 ESP_HR_Fahrtrichtung 0;
BA_ "GenSigStartValue" SG_ 278 ESP_HR_Fahrtrichtung 2;
BA_ "GenSigSendType" SG_ 278 ESP_HR_Fahrtrichtung 0;
BA_ "GenSigSwitchedByIgnition" SG_ 418 ESP_15_CRC 0;
BA_ "GenSigFuncType" SG_ 418 ESP_15_CRC 2;
BA_ "GenSigSendType" SG_ 418 ESP_15_CRC 0;
BA_ "GenSigSwitchedByIgnition" SG_ 418 ESP_15_BZ 0;
BA_ "GenSigFuncType" SG_ 418 ESP_15_BZ 1;
BA_ "GenSigSendType" SG_ 418 ESP_15_BZ 0;
BA_ "Fehlerwert" SG_ 418 HMS_P_beibehalten_GE 3;
BA_ "GenSigSwitchedByIgnition" SG_ 418 HMS_P_beibehalten_GE 0;
BA_ "GenSigStartValue" SG_ 418 HMS_P_beibehalten_GE 2;
BA_ "GenSigSendType" SG_ 418 HMS_P_beibehalten_GE 0;
BA_ "GenSigSwitchedByIgnition" SG_ 418 HMS_Konsistenz_GE 0;
BA_ "GenSigSendType" SG_ 418 HMS_Konsistenz_GE 3;
BA_ "GenSigSwitchedByIgnition" SG_ 418 HMS_Konsistenz_IPA 0;
BA_ "GenSigSendType" SG_ 418 HMS_Konsistenz_IPA 3;
BA_ "GenSigSwitchedByIgnition" SG_ 418 HMS_Konsistenz_EBKV 0;
BA_ "GenSigSendType" SG_ 418 HMS_Konsistenz_EBKV 3;
BA_ "GenSigSwitchedByIgnition" SG_ 418 HMS_Konsistenz_RCTA 0;
BA_ "GenSigSendType" SG_ 418 HMS_Konsistenz_RCTA 3;
BA_ "GenSigSwitchedByIgnition" SG_ 418 HMS_Konsistenz_STA 0;
BA_ "GenSigSendType" SG_ 418 HMS_Konsistenz_STA 3;
BA_ "GenSigSwitchedByIgnition" SG_ 418 HMS_Konsistenz_MO 0;
BA_ "GenSigSendType" SG_ 418 HMS_Konsistenz_MO 3;
BA_ "GenSigSwitchedByIgnition" SG_ 418 HMS_halten_nicht_verfuegbar 0;
BA_ "GenSigSendType" SG_ 418 HMS_halten_nicht_verfuegbar 3;
BA_ "GenSigSwitchedByIgnition" SG_ 418 NL_PRIM_STP_01_Status 0;
BA_ "GenSigSendType" SG_ 418 NL_PRIM_STP_01_Status 3;
BA_ "GenSigSwitchedByIgnition" SG_ 418 HMS_Notstopp_Status 0;
BA_ "GenSigSendType" SG_ 418 HMS_Notstopp_Status 3;
BA_ "GenSigSwitchedByIgnition" SG_ 418 HMS_parken_nicht_verfuegbar 0;
BA_ "GenSigSendType" SG_ 418 HMS_parken_nicht_verfuegbar 3;
BA_ "GenSigSwitchedByIgnition" SG_ 418 HMS_Anforderung_GE 0;
BA_ "GenSigSendType" SG_ 418 HMS_Anforderung_GE 3;
BA_ "Fehlerwert" SG_ 418 HMS_Systemstatus 15;
BA_ "GenSigSwitchedByIgnition" SG_ 418 HMS_Systemstatus 0;
BA_ "GenSigStartValue" SG_ 418 HMS_Systemstatus 14;
BA_ "GenSigSendType" SG_ 418 HMS_Systemstatus 3;
BA_ "Fehlerwert" SG_ 418 HMS_Stillstand 7;
BA_ "GenSigSwitchedByIgnition" SG_ 418 HMS_Stillstand 0;
BA_ "GenSigStartValue" SG_ 418 HMS_Stillstand 6;
BA_ "GenSigSendType" SG_ 418 HMS_Stillstand 3;
BA_ "GenSigSwitchedByIgnition" SG_ 418 HMS_aktives_System 0;
BA_ "GenSigSendType" SG_ 418 HMS_aktives_System 3;
BA_ "GenSigSwitchedByIgnition" SG_ 418 HMS_Konsistenz_HVLM 0;
BA_ "GenSigSendType" SG_ 418 HMS_Konsistenz_HVLM 3;
BA_ "GenSigSwitchedByIgnition" SG_ 418 HMS_Konsistenz_ACC 0;
BA_ "GenSigSendType" SG_ 418 HMS_Konsistenz_ACC 3;
BA_ "GenSigSwitchedByIgnition" SG_ 418 HMS_Fehlerstatus 0;
BA_ "GenSigSendType" SG_ 418 HMS_Fehlerstatus 3;
BA_ "GenSigSwitchedByIgnition" SG_ 418 ESP_Index_Haltemoment 0;
BA_ "GenSigSendType" SG_ 418 ESP_Index_Haltemoment 0;
BA_ "Fehlerwert" SG_ 418 ESP_Haltemoment 1023;
BA_ "GenSigSwitchedByIgnition" SG_ 418 ESP_Haltemoment 0;
BA_ "GenSigStartValue" SG_ 418 ESP_Haltemoment 1022;
BA_ "GenSigSendType" SG_ 418 ESP_Haltemoment 0;
BA_ "Fehlerwert" SG_ 178 ESP_HL_Radgeschw_02 65535;
BA_ "GenSigSwitchedByIgnition" SG_ 178 ESP_HL_Radgeschw_02 0;
BA_ "GenSigStartValue" SG_ 178 ESP_HL_Radgeschw_02 65534;
BA_ "GenSigSendType" SG_ 178 ESP_HL_Radgeschw_02 0;
BA_ "Fehlerwert" SG_ 178 ESP_HR_Radgeschw_02 65535;
BA_ "GenSigSwitchedByIgnition" SG_ 178 ESP_HR_Radgeschw_02 0;
BA_ "GenSigStartValue" SG_ 178 ESP_HR_Radgeschw_02 65534;
BA_ "GenSigSendType" SG_ 178 ESP_HR_Radgeschw_02 0;
BA_ "Fehlerwert" SG_ 178 ESP_VL_Radgeschw_02 65535;
BA_ "GenSigSwitchedByIgnition" SG_ 178 ESP_VL_Radgeschw_02 0;
BA_ "GenSigStartValue" SG_ 178 ESP_VL_Radgeschw_02 65534;
BA_ "GenSigSendType" SG_ 178 ESP_VL_Radgeschw_02 0;
BA_ "Fehlerwert" SG_ 178 ESP_VR_Radgeschw_02 65535;
BA_ "GenSigSwitchedByIgnition" SG_ 178 ESP_VR_Radgeschw_02 0;
BA_ "GenSigStartValue" SG_ 178 ESP_VR_Radgeschw_02 65534;
BA_ "GenSigSendType" SG_ 178 ESP_VR_Radgeschw_02 0;
BA_ "GenSigSwitchedByIgnition" SG_ 1629 ESP_20_CRC 0;
BA_ "GenSigFuncType" SG_ 1629 ESP_20_CRC 2;
BA_ "GenSigSendType" SG_ 1629 ESP_20_CRC 0;
BA_ "GenSigSwitchedByIgnition" SG_ 1629 ESP_20_BZ 0;
BA_ "GenSigFuncType" SG_ 1629 ESP_20_BZ 1;
BA_ "GenSigSendType" SG_ 1629 ESP_20_BZ 0;
BA_ "GenSigSwitchedByIgnition" SG_ 1629 BR_Systemart 0;
BA_ "GenSigFuncType" SG_ 1629 BR_Systemart 8;
BA_ "GenSigSendType" SG_ 1629 BR_Systemart 0;
BA_ "GenSigSwitchedByIgnition" SG_ 1629 ESP_SpannungsAnf_02 0;
BA_ "GenSigSendType" SG_ 1629 ESP_SpannungsAnf_02 3;
BA_ "GenSigSwitchedByIgnition" SG_ 1629 ESP_Zaehnezahl 0;
BA_ "GenSigFuncType" SG_ 1629 ESP_Zaehnezahl 8;
BA_ "GenSigSendType" SG_ 1629 ESP_Zaehnezahl 0;
BA_ "GenSigSwitchedByIgnition" SG_ 1629 ESP_Charisma_FahrPr 0;
BA_ "GenSigSendType" SG_ 1629 ESP_Charisma_FahrPr 3;
BA_ "GenSigSwitchedByIgnition" SG_ 1629 ESP_Charisma_Status 0;
BA_ "GenSigSendType" SG_ 1629 ESP_Charisma_Status 3;
BA_ "GenSigSwitchedByIgnition" SG_ 1629 ESP_Wiederstart_Anz_01 0;
BA_ "GenSigSendType" SG_ 1629 ESP_Wiederstart_Anz_01 3;
BA_ "GenSigSwitchedByIgnition" SG_ 1629 ESP_Wiederstart_Anz_02 0;
BA_ "GenSigSendType" SG_ 1629 ESP_Wiederstart_Anz_02 3;
BA_ "GenSigSwitchedByIgnition" SG_ 1629 ESP_Wiederstart_Anz_03 0;
BA_ "GenSigSendType" SG_ 1629 ESP_Wiederstart_Anz_03 3;
BA_ "GenSigSwitchedByIgnition" SG_ 1629 ESP_Wiederstart_Anz_04 0;
BA_ "GenSigSendType" SG_ 1629 ESP_Wiederstart_Anz_04 3;
BA_ "GenSigSwitchedByIgnition" SG_ 1629 ESP_Stoppverbot_Anz_01 0;
BA_ "GenSigSendType" SG_ 1629 ESP_Stoppverbot_Anz_01 3;
BA_ "GenSigSwitchedByIgnition" SG_ 1629 ESP_Stoppverbot_Anz_02 0;
BA_ "GenSigSendType" SG_ 1629 ESP_Stoppverbot_Anz_02 3;
BA_ "GenSigSwitchedByIgnition" SG_ 1629 ESP_Stoppverbot_Anz_03 0;
BA_ "GenSigSendType" SG_ 1629 ESP_Stoppverbot_Anz_03 3;
BA_ "GenSigSwitchedByIgnition" SG_ 1629 ESP_Stoppverbot_Anz_04 0;
BA_ "GenSigSendType" SG_ 1629 ESP_Stoppverbot_Anz_04 3;
BA_ "GenSigSwitchedByIgnition" SG_ 1629 ESP_Stoppverbot_Anz_05 0;
BA_ "GenSigSendType" SG_ 1629 ESP_Stoppverbot_Anz_05 3;
BA_ "GenSigSwitchedByIgnition" SG_ 1629 ESP_Stoppverbot_Anz_06 0;
BA_ "GenSigSendType" SG_ 1629 ESP_Stoppverbot_Anz_06 3;
BA_ "GenSigSwitchedByIgnition" SG_ 1629 ESP_Stoppverbot_Anz_07 0;
BA_ "GenSigSendType" SG_ 1629 ESP_Stoppverbot_Anz_07 3;
BA_ "GenSigSwitchedByIgnition" SG_ 1629 ESP_Stoppverbot_Anz_Std 0;
BA_ "GenSigSendType" SG_ 1629 ESP_Stoppverbot_Anz_Std 3;
BA_ "Fehlerwert" SG_ 1629 ESP_Dachrelingsensor 3;
BA_ "GenSigSwitchedByIgnition" SG_ 1629 ESP_Dachrelingsensor 0;
BA_ "GenSigSendType" SG_ 1629 ESP_Dachrelingsensor 0;
BA_ "GenSigSwitchedByIgnition" SG_ 1629 ESP_Stoppverbot_Anz_08 0;
BA_ "GenSigSendType" SG_ 1629 ESP_Stoppverbot_Anz_08 3;
BA_ "GenSigSwitchedByIgnition" SG_ 1629 HDC_Charisma_FahrPr 0;
BA_ "GenSigSendType" SG_ 1629 HDC_Charisma_FahrPr 3;
BA_ "GenSigSwitchedByIgnition" SG_ 1629 HDC_Charisma_Status 0;
BA_ "GenSigSendType" SG_ 1629 HDC_Charisma_Status 3;
BA_ "GenSigSwitchedByIgnition" SG_ 1629 BR_QBit_Reifenumfang 0;
BA_ "GenSigStartValue" SG_ 1629 BR_QBit_Reifenumfang 1;
BA_ "GenSigSendType" SG_ 1629 BR_QBit_Reifenumfang 0;
BA_ "GenSigSwitchedByIgnition" SG_ 1629 BR_Reifenumfang 0;
BA_ "GenSigSendType" SG_ 1629 BR_Reifenumfang 0;
BA_ "GenSigSwitchedByIgnition" SG_ 253 ESP_21_CRC 0;
BA_ "GenSigFuncType" SG_ 253 ESP_21_CRC 2;
BA_ "GenSigSendType" SG_ 253 ESP_21_CRC 0;
BA_ "GenSigSwitchedByIgnition" SG_ 253 ESP_21_BZ 0;
BA_ "GenSigFuncType" SG_ 253 ESP_21_BZ 1;
BA_ "GenSigSendType" SG_ 253 ESP_21_BZ 0;
BA_ "Fehlerwert" SG_ 253 BR_Eingriffsmoment 1023;
BA_ "GenSigSwitchedByIgnition" SG_ 253 BR_Eingriffsmoment 0;
BA_ "GenSigStartValue" SG_ 253 BR_Eingriffsmoment 1022;
BA_ "GenSigSendType" SG_ 253 BR_Eingriffsmoment 0;
BA_ "GenSigSwitchedByIgnition" SG_ 253 ESP_PLA_Bremseingriff 0;
BA_ "GenSigSendType" SG_ 253 ESP_PLA_Bremseingriff 0;
BA_ "GenSigSwitchedByIgnition" SG_ 253 ESP_Diagnose 0;
BA_ "GenSigSendType" SG_ 253 ESP_Diagnose 0;
BA_ "GenSigSwitchedByIgnition" SG_ 253 ESC_Reku_Freigabe 0;
BA_ "GenSigSendType" SG_ 253 ESC_Reku_Freigabe 0;
BA_ "Fehlerwert" SG_ 253 ESC_v_Signal_Qualifier_High_Low 7;
BA_ "GenSigSwitchedByIgnition" SG_ 253 ESC_v_Signal_Qualifier_High_Low 0;
BA_ "GenSigStartValue" SG_ 253 ESC_v_Signal_Qualifier_High_Low 6;
BA_ "GenSigSendType" SG_ 253 ESC_v_Signal_Qualifier_High_Low 0;
BA_ "GenSigSwitchedByIgnition" SG_ 253 ESP_Vorsteuerung 0;
BA_ "GenSigSendType" SG_ 253 ESP_Vorsteuerung 0;
BA_ "GenSigSwitchedByIgnition" SG_ 253 ESP_AWV3_Brems_aktiv 0;
BA_ "GenSigSendType" SG_ 253 ESP_AWV3_Brems_aktiv 0;
BA_ "GenSigSwitchedByIgnition" SG_ 253 OBD_Schlechtweg 0;
BA_ "GenSigSendType" SG_ 253 OBD_Schlechtweg 0;
BA_ "GenSigSwitchedByIgnition" SG_ 253 OBD_QBit_Schlechtweg 0;
BA_ "GenSigStartValue" SG_ 253 OBD_QBit_Schlechtweg 1;
BA_ "GenSigSendType" SG_ 253 OBD_QBit_Schlechtweg 0;
BA_ "GenSigMissingSourceValue" SG_ 253 ESP_v_Signal 65534;
BA_ "Fehlerwert" SG_ 253 ESP_v_Signal 65535;
BA_ "GenSigSwitchedByIgnition" SG_ 253 ESP_v_Signal 0;
BA_ "GenSigStartValue" SG_ 253 ESP_v_Signal 65534;
BA_ "GenSigSendType" SG_ 253 ESP_v_Signal 0;
BA_ "GenSigSwitchedByIgnition" SG_ 253 ASR_Tastung_passiv 0;
BA_ "GenSigSendType" SG_ 253 ASR_Tastung_passiv 0;
BA_ "GenSigSwitchedByIgnition" SG_ 253 ESP_Tastung_passiv 0;
BA_ "GenSigSendType" SG_ 253 ESP_Tastung_passiv 0;
BA_ "GenSigSwitchedByIgnition" SG_ 253 ESP_Systemstatus 0;
BA_ "GenSigSendType" SG_ 253 ESP_Systemstatus 0;
BA_ "GenSigSwitchedByIgnition" SG_ 253 ASR_Schalteingriff 0;
BA_ "GenSigSendType" SG_ 253 ASR_Schalteingriff 0;
BA_ "GenSigSwitchedByIgnition" SG_ 253 ESP_Haltebestaetigung 0;
BA_ "GenSigSendType" SG_ 253 ESP_Haltebestaetigung 0;
BA_ "GenSigSwitchedByIgnition" SG_ 253 ESP_MKB_Abbruch_Geschw 0;
BA_ "GenSigSendType" SG_ 253 ESP_MKB_Abbruch_Geschw 0;
BA_ "GenSigSwitchedByIgnition" SG_ 253 ESP_QBit_v_Signal 0;
BA_ "GenSigStartValue" SG_ 253 ESP_QBit_v_Signal 1;
BA_ "GenSigSendType" SG_ 253 ESP_QBit_v_Signal 0;
BA_ "GenSigSwitchedByIgnition" SG_ 253 ABS_Bremsung 0;
BA_ "GenSigSendType" SG_ 253 ABS_Bremsung 0;
BA_ "GenSigSwitchedByIgnition" SG_ 253 ASR_Anf 0;
BA_ "GenSigSendType" SG_ 253 ASR_Anf 0;
BA_ "GenSigSwitchedByIgnition" SG_ 253 MSR_Anf 0;
BA_ "GenSigSendType" SG_ 253 MSR_Anf 0;
BA_ "GenSigSwitchedByIgnition" SG_ 253 EBV_Eingriff 0;
BA_ "GenSigSendType" SG_ 253 EBV_Eingriff 0;
BA_ "GenSigSwitchedByIgnition" SG_ 253 EDS_Eingriff 0;
BA_ "GenSigSendType" SG_ 253 EDS_Eingriff 0;
BA_ "GenSigSwitchedByIgnition" SG_ 253 ESP_Eingriff 0;
BA_ "GenSigSendType" SG_ 253 ESP_Eingriff 0;
BA_ "GenSigSwitchedByIgnition" SG_ 253 ESP_ASP 0;
BA_ "GenSigSendType" SG_ 253 ESP_ASP 0;
BA_ "GenSigSwitchedByIgnition" SG_ 253 ESP_Anhaltevorgang_ACC_aktiv 0;
BA_ "GenSigSendType" SG_ 253 ESP_Anhaltevorgang_ACC_aktiv 0;
BA_ "GenSigSwitchedByIgnition" SG_ 427 ESP_33_CRC 0;
BA_ "GenSigFuncType" SG_ 427 ESP_33_CRC 2;
BA_ "GenSigSendType" SG_ 427 ESP_33_CRC 0;
BA_ "GenSigSwitchedByIgnition" SG_ 427 ESP_33_BZ 0;
BA_ "GenSigFuncType" SG_ 427 ESP_33_BZ 1;
BA_ "GenSigSendType" SG_ 427 ESP_33_BZ 0;
BA_ "GenSigSwitchedByIgnition" SG_ 427 ESC_AHW_aktiv 0;
BA_ "GenSigSendType" SG_ 427 ESC_AHW_aktiv 3;
BA_ "GenSigSwitchedByIgnition" SG_ 427 ESC_AHW_nicht_verfuegbar 0;
BA_ "GenSigSendType" SG_ 427 ESC_AHW_nicht_verfuegbar 3;
BA_ "GenSigSwitchedByIgnition" SG_ 427 ESC_ANB_CM_aktiv 0;
BA_ "GenSigSendType" SG_ 427 ESC_ANB_CM_aktiv 3;
BA_ "GenSigSwitchedByIgnition" SG_ 427 ESC_ANB_CM_nicht_verfuegbar 0;
BA_ "GenSigSendType" SG_ 427 ESC_ANB_CM_nicht_verfuegbar 3;
BA_ "GenSigSwitchedByIgnition" SG_ 427 ESC_Warnruck_aktiv 0;
BA_ "GenSigSendType" SG_ 427 ESC_Warnruck_aktiv 3;
BA_ "GenSigSwitchedByIgnition" SG_ 427 ESC_Warnruck_nicht_verfuegbar 0;
BA_ "GenSigSendType" SG_ 427 ESC_Warnruck_nicht_verfuegbar 3;
BA_ "GenSigSwitchedByIgnition" SG_ 427 ESC_Prefill_aktiv 0;
BA_ "GenSigSendType" SG_ 427 ESC_Prefill_aktiv 3;
BA_ "GenSigSwitchedByIgnition" SG_ 427 ESC_Prefill_nicht_verfuegbar 0;
BA_ "GenSigSendType" SG_ 427 ESC_Prefill_nicht_verfuegbar 3;
BA_ "GenSigSwitchedByIgnition" SG_ 427 ESC_HBA_aktiv 0;
BA_ "GenSigSendType" SG_ 427 ESC_HBA_aktiv 3;
BA_ "GenSigSwitchedByIgnition" SG_ 427 ESC_HBA_nicht_verfuegbar 0;
BA_ "GenSigSendType" SG_ 427 ESC_HBA_nicht_verfuegbar 3;
BA_ "GenSigSwitchedByIgnition" SG_ 427 ESC_TSK_SRBM_Anf 0;
BA_ "GenSigSendType" SG_ 427 ESC_TSK_SRBM_Anf 3;
BA_ "GenSigSwitchedByIgnition" SG_ 427 ESC_TSK_SRBM_nicht_verfuegbar 0;
BA_ "GenSigSendType" SG_ 427 ESC_TSK_SRBM_nicht_verfuegbar 3;
BA_ "GenSigSwitchedByIgnition" SG_ 427 ESC_Verz_Reg_aktiv 0;
BA_ "GenSigSendType" SG_ 427 ESC_Verz_Reg_aktiv 3;
BA_ "GenSigSwitchedByIgnition" SG_ 427 ESC_Verz_Reg_nicht_verfuegbar 0;
BA_ "GenSigSendType" SG_ 427 ESC_Verz_Reg_nicht_verfuegbar 3;
BA_ "GenSigSwitchedByIgnition" SG_ 427 ESC_Verz_Reg_TB_nicht_verfuegbar 0;
BA_ "GenSigSendType" SG_ 427 ESC_Verz_Reg_TB_nicht_verfuegbar 3;
BA_ "GenSigSwitchedByIgnition" SG_ 427 ESC_Verz_Reg_ZB_nicht_verfuegbar 0;
BA_ "GenSigSendType" SG_ 427 ESC_Verz_Reg_ZB_nicht_verfuegbar 3;
BA_ "GenSigSwitchedByIgnition" SG_ 427 ESC_Bremslicht_unplausibel 0;
BA_ "GenSigSendType" SG_ 427 ESC_Bremslicht_unplausibel 3;
BA_ "GenSigSwitchedByIgnition" SG_ 427 ESC_Konsistenz_ACC 0;
BA_ "GenSigSendType" SG_ 427 ESC_Konsistenz_ACC 3;
BA_ "GenSigSwitchedByIgnition" SG_ 427 ESC_Konsistenz_AWV 0;
BA_ "GenSigSendType" SG_ 427 ESC_Konsistenz_AWV 3;
BA_ "GenSigSwitchedByIgnition" SG_ 427 ESC_Konsistenz_ARA 0;
BA_ "GenSigSendType" SG_ 427 ESC_Konsistenz_ARA 3;
BA_ "GenSigSwitchedByIgnition" SG_ 427 ESC_Konsistenz_IPA 0;
BA_ "GenSigSendType" SG_ 427 ESC_Konsistenz_IPA 3;
BA_ "GenSigSwitchedByIgnition" SG_ 427 ESC_Konsistenz_FCW 0;
BA_ "GenSigSendType" SG_ 427 ESC_Konsistenz_FCW 3;
BA_ "GenSigSwitchedByIgnition" SG_ 427 ESC_Konsistenz_NV 0;
BA_ "GenSigSendType" SG_ 427 ESC_Konsistenz_NV 3;
BA_ "GenSigSwitchedByIgnition" SG_ 427 ESC_Konsistenz_RCTA 0;
BA_ "GenSigSendType" SG_ 427 ESC_Konsistenz_RCTA 3;
BA_ "GenSigSwitchedByIgnition" SG_ 427 ESC_Konsistenz_TSK 0;
BA_ "GenSigSendType" SG_ 427 ESC_Konsistenz_TSK 3;
BA_ "GenSigSwitchedByIgnition" SG_ 427 ESC_Konsistenz_vFGS 0;
BA_ "GenSigSendType" SG_ 427 ESC_Konsistenz_vFGS 3;
BA_ "GenSigSwitchedByIgnition" SG_ 427 ESC_Konsistenz_STA 0;
BA_ "GenSigSendType" SG_ 427 ESC_Konsistenz_STA 3;
BA_ "GenSigSwitchedByIgnition" SG_ 427 ESC_Fahrer_Bremsdruck_bestimmend 0;
BA_ "GenSigSendType" SG_ 427 ESC_Fahrer_Bremsdruck_bestimmend 3;
BA_ "GenSigSwitchedByIgnition" SG_ 427 ESC_Konsistenz_EA 0;
BA_ "GenSigSendType" SG_ 427 ESC_Konsistenz_EA 3;
BA_ "GenSigSwitchedByIgnition" SG_ 427 ESC_Konsistenz_BFF 0;
BA_ "GenSigSendType" SG_ 427 ESC_Konsistenz_BFF 3;
BA_ "GenSigSwitchedByIgnition" SG_ 427 ESC_Konsistenz_MKB 0;
BA_ "GenSigSendType" SG_ 427 ESC_Konsistenz_MKB 3;
BA_ "GenSigSwitchedByIgnition" SG_ 427 ESC_Verz_ASIL_Verfuegbarkeit 0;
BA_ "GenSigSendType" SG_ 427 ESC_Verz_ASIL_Verfuegbarkeit 3;
BA_ "GenSigSwitchedByIgnition" SG_ 427 ESC_Pumpenanlauf_aktiv 0;
BA_ "GenSigSendType" SG_ 427 ESC_Pumpenanlauf_aktiv 3;
BA_ "GenSigSwitchedByIgnition" SG_ 427 ESC_Konsistenz_AGW 0;
BA_ "GenSigSendType" SG_ 427 ESC_Konsistenz_AGW 3;
BA_ "GenSigSwitchedByIgnition" SG_ 427 ESC_Konsistenz_KAS 0;
BA_ "GenSigSendType" SG_ 427 ESC_Konsistenz_KAS 3;
BA_ "GenSigSwitchedByIgnition" SG_ 427 ESC_Konsistenz_PCF 0;
BA_ "GenSigSendType" SG_ 427 ESC_Konsistenz_PCF 3;
BA_ "GenSigFuncType" SG_ 264 Fahrwerk_01_CRC 2;
BA_ "GenSigSendType" SG_ 264 Fahrwerk_01_CRC 0;
BA_ "GenSigFuncType" SG_ 264 Fahrwerk_01_BZ 1;
BA_ "GenSigSendType" SG_ 264 Fahrwerk_01_BZ 0;
BA_ "GenSigSendType" SG_ 264 FA_Hoehenwerte_kalibriert 0;
BA_ "GenSigSendType" SG_ 264 FA_ESP_Zuschaltung 0;
BA_ "Fehlerwert" SG_ 264 FA_Hoehenwert_VL_00 255;
BA_ "GenSigStartValue" SG_ 264 FA_Hoehenwert_VL_00 254;
BA_ "Fehlerwert" SG_ 264 FA_Hoehenwert_VL_01 255;
BA_ "GenSigStartValue" SG_ 264 FA_Hoehenwert_VL_01 254;
BA_ "Fehlerwert" SG_ 264 FA_Hoehenwert_VR_00 255;
BA_ "GenSigStartValue" SG_ 264 FA_Hoehenwert_VR_00 254;
BA_ "Fehlerwert" SG_ 264 FA_Hoehenwert_VR_01 255;
BA_ "GenSigStartValue" SG_ 264 FA_Hoehenwert_VR_01 254;
BA_ "Fehlerwert" SG_ 264 FA_Hoehenwert_HL_00 255;
BA_ "GenSigStartValue" SG_ 264 FA_Hoehenwert_HL_00 254;
BA_ "Fehlerwert" SG_ 264 FA_Hoehenwert_HL_01 255;
BA_ "GenSigStartValue" SG_ 264 FA_Hoehenwert_HL_01 254;
BA_ "Fehlerwert" SG_ 264 FA_Hoehenwert_HR_00 255;
BA_ "GenSigStartValue" SG_ 264 FA_Hoehenwert_HR_00 254;
BA_ "Fehlerwert" SG_ 264 FA_Hoehenwert_HR_01 255;
BA_ "GenSigStartValue" SG_ 264 FA_Hoehenwert_HR_01 254;
BA_ "GenSigSendType" SG_ 1332 FCWO_Texte 3;
BA_ "GenSigSendType" SG_ 1332 FCWO_Warnung 3;
BA_ "GenSigSendType" SG_ 1332 FCWP_Texte 3;
BA_ "GenSigSendType" SG_ 1332 FCWP_Warnung 3;
BA_ "GenSigSendType" SG_ 1332 FCWO_LED_Leiste 3;
BA_ "GenSigSendType" SG_ 1332 FCWP_LED_Leiste 3;
BA_ "GenSigSendType" SG_ 1332 FCWO_Warnlevel 3;
BA_ "GenSigSendType" SG_ 1332 FCWP_Warnlevel 3;
BA_ "GenSigSendType" SG_ 1332 FCWO_Charisma_FahrPr 0;
BA_ "GenSigSendType" SG_ 1332 FCWO_Charisma_Status 0;
BA_ "GenSigSendType" SG_ 1332 FCWP_Charisma_Status 0;
BA_ "GenSigSendType" SG_ 1332 FCWP_Charisma_FahrPr 0;
BA_ "GenSigFuncType" SG_ 314 FCW_02_CRC 2;
BA_ "GenSigSendType" SG_ 314 FCW_02_CRC 0;
BA_ "GenSigFuncType" SG_ 314 FCW_02_BZ 1;
BA_ "GenSigSendType" SG_ 314 FCW_02_BZ 0;
BA_ "GenSigSendType" SG_ 314 FCWO_Ruck_Freigabe 0;
BA_ "GenSigSendType" SG_ 314 FCWO_Ruckprofil 0;
BA_ "GenSigSendType" SG_ 314 FCWO_Anf_Prefill 0;
BA_ "GenSigSendType" SG_ 314 FCWO_HBA_Param 0;
BA_ "GenSigSendType" SG_ 314 FCWP_Anf_Prefill 0;
BA_ "GenSigSendType" SG_ 314 FCWP_HBA_Param 0;
BA_ "GenSigSendType" SG_ 314 FCWP_Ruck_Freigabe 0;
BA_ "GenSigSendType" SG_ 314 FCWP_Ruckprofil 0;
BA_ "GenSigSendType" SG_ 1605 FLA_aktiv 3;
BA_ "GenSigSendType" SG_ 1605 FLA_ISP_defekt 3;
BA_ "GenSigSendType" SG_ 1605 FLA_Sensor_blockiert 3;
BA_ "Fehlerwert" SG_ 1605 FLA_Abblendursache 255;
BA_ "GenSigSendType" SG_ 1605 FLA_Abblendursache 3;
BA_ "Fehlerwert" SG_ 1605 FLA_Fernlicht_PWM 127;
BA_ "GenSigStartValue" SG_ 1605 FLA_Fernlicht_PWM 100;
BA_ "GenSigSendType" SG_ 1605 FLA_Fernlicht_PWM 3;
BA_ "Fehlerwert" SG_ 1605 ISP_EC_Lichtwert_vorne 63;
BA_ "GenSigStartValue" SG_ 1605 ISP_EC_Lichtwert_vorne 62;
BA_ "GenSigSendType" SG_ 1605 ISP_EC_Lichtwert_vorne 3;
BA_ "Fehlerwert" SG_ 1605 ISP_EC_Lichtwert_hinten 63;
BA_ "GenSigStartValue" SG_ 1605 ISP_EC_Lichtwert_hinten 62;
BA_ "GenSigSendType" SG_ 1605 ISP_EC_Lichtwert_hinten 3;
BA_ "Fehlerwert" SG_ 1605 ISP_Himmelsrichtung 31;
BA_ "GenSigStartValue" SG_ 1605 ISP_Himmelsrichtung 30;
BA_ "GenSigSendType" SG_ 1605 ISP_Himmelsrichtung 3;
BA_ "GenSigSendType" SG_ 1605 ISP_Taste_betaetigt 3;
BA_ "GenSigStartValue" SG_ 1605 ISP_EC_aktiv 1;
BA_ "GenSigSendType" SG_ 1605 ISP_EC_aktiv 3;
BA_ "GenSigStartValue" SG_ 1605 ISP_Kompass_aktiv 1;
BA_ "GenSigSendType" SG_ 1605 ISP_Kompass_aktiv 3;
BA_ "GenSigSendType" SG_ 1605 FLA_Aufblenden 3;
BA_ "GenSigSendType" SG_ 1605 FLA_SAE_Mode 3;
BA_ "GenSigSwitchedByIgnition" SG_ 987 BCM_01_alt 0;
BA_ "GenSigFuncType" SG_ 987 BCM_01_alt 5;
BA_ "GenSigStartValue" SG_ 987 BCM_01_alt 1;
BA_ "GenSigSendType" SG_ 987 BCM_01_alt 0;
BA_ "GenSigSwitchedByIgnition" SG_ 987 SMLS_01_alt 0;
BA_ "GenSigFuncType" SG_ 987 SMLS_01_alt 5;
BA_ "GenSigStartValue" SG_ 987 SMLS_01_alt 1;
BA_ "GenSigSendType" SG_ 987 SMLS_01_alt 0;
BA_ "GenSigSwitchedByIgnition" SG_ 987 ZV_02_alt 0;
BA_ "GenSigFuncType" SG_ 987 ZV_02_alt 5;
BA_ "GenSigStartValue" SG_ 987 ZV_02_alt 1;
BA_ "GenSigSendType" SG_ 987 ZV_02_alt 0;
BA_ "GenSigSwitchedByIgnition" SG_ 987 Wischer_01_alt 0;
BA_ "GenSigFuncType" SG_ 987 Wischer_01_alt 5;
BA_ "GenSigStartValue" SG_ 987 Wischer_01_alt 1;
BA_ "GenSigSendType" SG_ 987 Wischer_01_alt 0;
BA_ "GenSigSwitchedByIgnition" SG_ 987 Anhaenger_01_alt 0;
BA_ "GenSigFuncType" SG_ 987 Anhaenger_01_alt 5;
BA_ "GenSigStartValue" SG_ 987 Anhaenger_01_alt 1;
BA_ "GenSigSendType" SG_ 987 Anhaenger_01_alt 0;
BA_ "GenSigSwitchedByIgnition" SG_ 987 Klima_Sensor_02_alt 0;
BA_ "GenSigFuncType" SG_ 987 Klima_Sensor_02_alt 5;
BA_ "GenSigStartValue" SG_ 987 Klima_Sensor_02_alt 1;
BA_ "GenSigSendType" SG_ 987 Klima_Sensor_02_alt 0;
BA_ "GenSigSwitchedByIgnition" SG_ 987 Verdeck_01_alt 0;
BA_ "GenSigFuncType" SG_ 987 Verdeck_01_alt 5;
BA_ "GenSigStartValue" SG_ 987 Verdeck_01_alt 1;
BA_ "GenSigSendType" SG_ 987 Verdeck_01_alt 0;
BA_ "GenSigSwitchedByIgnition" SG_ 987 Klima_11_alt 0;
BA_ "GenSigFuncType" SG_ 987 Klima_11_alt 5;
BA_ "GenSigStartValue" SG_ 987 Klima_11_alt 1;
BA_ "GenSigSendType" SG_ 987 Klima_11_alt 0;
BA_ "GenSigSwitchedByIgnition" SG_ 987 WFS_01_alt 0;
BA_ "GenSigFuncType" SG_ 987 WFS_01_alt 5;
BA_ "GenSigStartValue" SG_ 987 WFS_01_alt 1;
BA_ "GenSigSendType" SG_ 987 WFS_01_alt 0;
BA_ "GenSigSwitchedByIgnition" SG_ 987 Licht_Anf_01_alt 0;
BA_ "GenSigFuncType" SG_ 987 Licht_Anf_01_alt 5;
BA_ "GenSigStartValue" SG_ 987 Licht_Anf_01_alt 1;
BA_ "GenSigSendType" SG_ 987 Licht_Anf_01_alt 0;
BA_ "GenSigSwitchedByIgnition" SG_ 987 ZV_verriegelt_extern_soll 0;
BA_ "GenSigSendType" SG_ 987 ZV_verriegelt_extern_soll 0;
BA_ "GenSigSwitchedByIgnition" SG_ 987 BH_Lichthupe 0;
BA_ "GenSigSendType" SG_ 987 BH_Lichthupe 3;
BA_ "GenSigSwitchedByIgnition" SG_ 987 WFS_Klemmenfreigabe 0;
BA_ "GenSigSendType" SG_ 987 WFS_Klemmenfreigabe 0;
BA_ "GenSigSwitchedByIgnition" SG_ 987 ZV_Tankklappe_offen 0;
BA_ "GenSigSendType" SG_ 987 ZV_Tankklappe_offen 0;
BA_ "GenSigSendType" SG_ 987 AAG_Anhaenger_abgesteckt 0;
BA_ "Fehlerwert" SG_ 987 BCM1_LDS_Stellung 7;
BA_ "GenSigSwitchedByIgnition" SG_ 987 BCM1_LDS_Stellung 0;
BA_ "GenSigSendType" SG_ 987 BCM1_LDS_Stellung 3;
BA_ "GenSigSendType" SG_ 987 VS_Verdeck_Anf 0;
BA_ "GenSigSendType" SG_ 987 VS_VD_entriegelt 0;
BA_ "GenSigSwitchedByIgnition" SG_ 987 ZV_HFS_offen 0;
BA_ "GenSigSendType" SG_ 987 ZV_HFS_offen 3;
BA_ "GenSigSwitchedByIgnition" SG_ 987 ZV_HBFS_offen 0;
BA_ "GenSigSendType" SG_ 987 ZV_HBFS_offen 3;
BA_ "GenSigSendType" SG_ 987 VS_VD_offen_ver 0;
BA_ "GenSigSendType" SG_ 987 VS_VD_zu_ver 0;
BA_ "GenSigSwitchedByIgnition" SG_ 987 ZV_BT_offen 0;
BA_ "GenSigSendType" SG_ 987 ZV_BT_offen 3;
BA_ "GenSigSwitchedByIgnition" SG_ 987 BCM1_Rueckfahrlicht_Schalter 0;
BA_ "GenSigSendType" SG_ 987 BCM1_Rueckfahrlicht_Schalter 3;
BA_ "GenSigSwitchedByIgnition" SG_ 987 ZV_FT_offen 0;
BA_ "GenSigSendType" SG_ 987 ZV_FT_offen 3;
BA_ "GenSigSwitchedByIgnition" SG_ 987 Wischer_vorne_aktiv 0;
BA_ "GenSigSendType" SG_ 987 Wischer_vorne_aktiv 3;
BA_ "GenSigSwitchedByIgnition" SG_ 987 AAG_Anhaenger_erkannt 0;
BA_ "NWM-WakeupAllowed" SG_ 987 AAG_Anhaenger_erkannt 1;
BA_ "GenSigSendType" SG_ 987 AAG_Anhaenger_erkannt 0;
BA_ "GenSigSwitchedByIgnition" SG_ 987 BCM1_MH_Schalter 0;
BA_ "GenSigSendType" SG_ 987 BCM1_MH_Schalter 3;
BA_ "GenSigSwitchedByIgnition" SG_ 987 ZV_HD_offen 0;
BA_ "GenSigSendType" SG_ 987 ZV_HD_offen 3;
BA_ "GenSigSwitchedByIgnition" SG_ 987 Waschen_vorne_aktiv 0;
BA_ "GenSigSendType" SG_ 987 Waschen_vorne_aktiv 3;
BA_ "GenSigSwitchedByIgnition" SG_ 987 KL_Thermomanagement 0;
BA_ "GenSigSendType" SG_ 987 KL_Thermomanagement 0;
BA_ "GenSigSwitchedByIgnition" SG_ 987 WFS_Schluessel_Fahrberecht 0;
BA_ "GenSigSendType" SG_ 987 WFS_Schluessel_Fahrberecht 0;
BA_ "GenSigSwitchedByIgnition" SG_ 987 BCM_Rueckfahrlicht_Anf 0;
BA_ "GenSigSendType" SG_ 987 BCM_Rueckfahrlicht_Anf 0;
BA_ "GenSigSwitchedByIgnition" SG_ 987 WWSs_01_alt 0;
BA_ "GenSigFuncType" SG_ 987 WWSs_01_alt 5;
BA_ "GenSigStartValue" SG_ 987 WWSs_01_alt 1;
BA_ "GenSigSendType" SG_ 987 WWSs_01_alt 3;
BA_ "Fehlerwert" SG_ 987 BCM_Tankklappensteller_Fehler 1;
BA_ "GenSigSwitchedByIgnition" SG_ 987 BCM_Tankklappensteller_Fehler 0;
BA_ "GenSigSendType" SG_ 987 BCM_Tankklappensteller_Fehler 0;
BA_ "GenSigSwitchedByIgnition" SG_ 987 ZV_verriegelt_soll 0;
BA_ "GenSigSendType" SG_ 987 ZV_verriegelt_soll 3;
BA_ "GenSigSwitchedByIgnition" SG_ 987 ZV_Schluessel_Zugang 0;
BA_ "GenSigSendType" SG_ 987 ZV_Schluessel_Zugang 0;
BA_ "GenSigSwitchedByIgnition" SG_ 987 WFS_ID_Geb_autorisiert_in_Kl15 0;
BA_ "GenSigSendType" SG_ 987 WFS_ID_Geb_autorisiert_in_Kl15 0;
BA_ "GenSigSwitchedByIgnition" SG_ 987 BH_Fernlicht 0;
BA_ "GenSigSendType" SG_ 987 BH_Fernlicht 3;
BA_ "GenSigSwitchedByIgnition" SG_ 987 BH_Blinker_li 0;
BA_ "GenSigSendType" SG_ 987 BH_Blinker_li 3;
BA_ "GenSigSwitchedByIgnition" SG_ 987 BH_Blinker_re 0;
BA_ "GenSigSendType" SG_ 987 BH_Blinker_re 3;
BA_ "GenSigSwitchedByIgnition" SG_ 987 BCM1_OBD_FStatus_ATemp 0;
BA_ "GenSigSendType" SG_ 987 BCM1_OBD_FStatus_ATemp 0;
BA_ "Fehlerwert" SG_ 987 BCM1_Aussen_Temp_ungef 255;
BA_ "GenSigSwitchedByIgnition" SG_ 987 BCM1_Aussen_Temp_ungef 0;
BA_ "GenSigStartValue" SG_ 987 BCM1_Aussen_Temp_ungef 254;
BA_ "GenSigSendType" SG_ 987 BCM1_Aussen_Temp_ungef 0;
BA_ "GenSigSwitchedByIgnition" SG_ 988 Motor_12_alt 0;
BA_ "GenSigFuncType" SG_ 988 Motor_12_alt 5;
BA_ "GenSigStartValue" SG_ 988 Motor_12_alt 1;
BA_ "GenSigSendType" SG_ 988 Motor_12_alt 0;
BA_ "GenSigSwitchedByIgnition" SG_ 988 ESP_07_alt 0;
BA_ "GenSigFuncType" SG_ 988 ESP_07_alt 5;
BA_ "GenSigStartValue" SG_ 988 ESP_07_alt 1;
BA_ "GenSigSendType" SG_ 988 ESP_07_alt 0;
BA_ "GenSigSwitchedByIgnition" SG_ 988 Getriebe_11_alt 0;
BA_ "GenSigFuncType" SG_ 988 Getriebe_11_alt 5;
BA_ "GenSigStartValue" SG_ 988 Getriebe_11_alt 1;
BA_ "GenSigSendType" SG_ 988 Getriebe_11_alt 0;
BA_ "GenSigSwitchedByIgnition" SG_ 988 Getriebe_13_alt 0;
BA_ "GenSigFuncType" SG_ 988 Getriebe_13_alt 5;
BA_ "GenSigStartValue" SG_ 988 Getriebe_13_alt 1;
BA_ "GenSigSendType" SG_ 988 Getriebe_13_alt 0;
BA_ "GenSigSwitchedByIgnition" SG_ 988 Getriebe_17_alt 0;
BA_ "GenSigFuncType" SG_ 988 Getriebe_17_alt 5;
BA_ "GenSigStartValue" SG_ 988 Getriebe_17_alt 1;
BA_ "GenSigSendType" SG_ 988 Getriebe_17_alt 0;
BA_ "GenSigSwitchedByIgnition" SG_ 988 GW_73_va_15 0;
BA_ "GenSigFuncType" SG_ 988 GW_73_va_15 5;
BA_ "GenSigStartValue" SG_ 988 GW_73_va_15 1;
BA_ "GenSigSendType" SG_ 988 GW_73_va_15 0;
BA_ "GenSigSwitchedByIgnition" SG_ 988 GW_73_va_16 0;
BA_ "GenSigFuncType" SG_ 988 GW_73_va_16 5;
BA_ "GenSigStartValue" SG_ 988 GW_73_va_16 1;
BA_ "GenSigSendType" SG_ 988 GW_73_va_16 0;
BA_ "GenSigSwitchedByIgnition" SG_ 988 GW_73_va_17 0;
BA_ "GenSigFuncType" SG_ 988 GW_73_va_17 5;
BA_ "GenSigStartValue" SG_ 988 GW_73_va_17 1;
BA_ "GenSigSendType" SG_ 988 GW_73_va_17 0;
BA_ "GenSigSwitchedByIgnition" SG_ 988 MO_QBit_Drehzahl_01 0;
BA_ "GenSigStartValue" SG_ 988 MO_QBit_Drehzahl_01 1;
BA_ "GenSigSendType" SG_ 988 MO_QBit_Drehzahl_01 0;
BA_ "GenSigSwitchedByIgnition" SG_ 988 MKE_Texte 0;
BA_ "GenSigSendType" SG_ 988 MKE_Texte 0;
BA_ "GenSigSwitchedByIgnition" SG_ 988 MKE_Stufe 0;
BA_ "GenSigSendType" SG_ 988 MKE_Stufe 0;
BA_ "GenSigSwitchedByIgnition" SG_ 988 MO_Drehzahl_01 0;
BA_ "GenSigSendType" SG_ 988 MO_Drehzahl_01 0;
BA_ "Fehlerwert" SG_ 988 GE_Fahrstufe 15;
BA_ "GenSigSwitchedByIgnition" SG_ 988 GE_Fahrstufe 0;
BA_ "GenSigStartValue" SG_ 988 GE_Fahrstufe 1;
BA_ "GenSigSendType" SG_ 988 GE_Fahrstufe 3;
BA_ "GenSigSwitchedByIgnition" SG_ 988 GE_reserv_Fahrstufe 0;
BA_ "GenSigSendType" SG_ 988 GE_reserv_Fahrstufe 0;
BA_ "GenSigSwitchedByIgnition" SG_ 988 GE_Notlauf 0;
BA_ "GenSigSendType" SG_ 988 GE_Notlauf 3;
BA_ "GenSigSwitchedByIgnition" SG_ 988 ESP_Rollenmodus_Deaktivieren 0;
BA_ "GenSigSendType" SG_ 988 ESP_Rollenmodus_Deaktivieren 0;
BA_ "Fehlerwert" SG_ 988 GE_Freilauf_Status 7;
BA_ "GenSigSwitchedByIgnition" SG_ 988 GE_Freilauf_Status 0;
BA_ "GenSigSendType" SG_ 988 GE_Freilauf_Status 0;
BA_ "GenSigSwitchedByIgnition" SG_ 991 Innenlicht_11_alt 0;
BA_ "GenSigFuncType" SG_ 991 Innenlicht_11_alt 5;
BA_ "GenSigStartValue" SG_ 991 Innenlicht_11_alt 1;
BA_ "GenSigSendType" SG_ 991 Innenlicht_11_alt 0;
BA_ "GenSigSwitchedByIgnition" SG_ 991 Spiegel_01_alt 0;
BA_ "GenSigFuncType" SG_ 991 Spiegel_01_alt 5;
BA_ "GenSigStartValue" SG_ 991 Spiegel_01_alt 1;
BA_ "GenSigSendType" SG_ 991 Spiegel_01_alt 0;
BA_ "GenSigSwitchedByIgnition" SG_ 991 Anhaenger_01_alt 0;
BA_ "GenSigFuncType" SG_ 991 Anhaenger_01_alt 5;
BA_ "GenSigStartValue" SG_ 991 Anhaenger_01_alt 1;
BA_ "GenSigSendType" SG_ 991 Anhaenger_01_alt 0;
BA_ "GenSigSwitchedByIgnition" SG_ 991 Licht_hinten_01_alt 0;
BA_ "GenSigFuncType" SG_ 991 Licht_hinten_01_alt 5;
BA_ "GenSigStartValue" SG_ 991 Licht_hinten_01_alt 1;
BA_ "GenSigSendType" SG_ 991 Licht_hinten_01_alt 0;
BA_ "GenSigSwitchedByIgnition" SG_ 991 LH_EPS_01_alt 0;
BA_ "GenSigFuncType" SG_ 991 LH_EPS_01_alt 5;
BA_ "GenSigStartValue" SG_ 991 LH_EPS_01_alt 1;
BA_ "GenSigSendType" SG_ 991 LH_EPS_01_alt 0;
BA_ "GenSigSwitchedByIgnition" SG_ 991 Klima_12_alt 0;
BA_ "GenSigFuncType" SG_ 991 Klima_12_alt 5;
BA_ "GenSigStartValue" SG_ 991 Klima_12_alt 1;
BA_ "GenSigSendType" SG_ 991 Klima_12_alt 0;
BA_ "GenSigSwitchedByIgnition" SG_ 991 SMLS_01_alt 0;
BA_ "GenSigFuncType" SG_ 991 SMLS_01_alt 5;
BA_ "GenSigStartValue" SG_ 991 SMLS_01_alt 1;
BA_ "GenSigSendType" SG_ 991 SMLS_01_alt 0;
BA_ "GenSigSwitchedByIgnition" SG_ 991 Getriebe_14_alt 0;
BA_ "GenSigFuncType" SG_ 991 Getriebe_14_alt 5;
BA_ "GenSigStartValue" SG_ 991 Getriebe_14_alt 1;
BA_ "GenSigSendType" SG_ 991 Getriebe_14_alt 0;
BA_ "GenSigSwitchedByIgnition" SG_ 991 PLA_01_alt 0;
BA_ "GenSigFuncType" SG_ 991 PLA_01_alt 5;
BA_ "GenSigStartValue" SG_ 991 PLA_01_alt 1;
BA_ "GenSigSendType" SG_ 991 PLA_01_alt 0;
BA_ "GenSigStartValue" SG_ 991 PLA_Status_PLA_EPS 9;
BA_ "GenSigSendType" SG_ 991 PLA_Status_PLA_EPS 3;
BA_ "GenSigSwitchedByIgnition" SG_ 991 IL_Innenlicht_aktiv 0;
BA_ "GenSigStartValue" SG_ 991 IL_Innenlicht_aktiv 1;
BA_ "GenSigSendType" SG_ 991 IL_Innenlicht_aktiv 3;
BA_ "Fehlerwert" SG_ 991 FAS_Taster_Fehler 1;
BA_ "GenSigSwitchedByIgnition" SG_ 991 FAS_Taster_Fehler 0;
BA_ "GenSigSendType" SG_ 991 FAS_Taster_Fehler 3;
BA_ "GenSigSwitchedByIgnition" SG_ 991 AAG_Bremslicht_H_def 0;
BA_ "GenSigSendType" SG_ 991 AAG_Bremslicht_H_def 0;
BA_ "GenSigSwitchedByIgnition" SG_ 991 LH_3_Bremsl_def 0;
BA_ "GenSigSendType" SG_ 991 LH_3_Bremsl_def 0;
BA_ "GenSigSwitchedByIgnition" SG_ 991 LH_Bremsl_li_ges_def 0;
BA_ "GenSigSendType" SG_ 991 LH_Bremsl_li_ges_def 0;
BA_ "GenSigSwitchedByIgnition" SG_ 991 LH_Bremsl_re_ges_def 0;
BA_ "GenSigSendType" SG_ 991 LH_Bremsl_re_ges_def 0;
BA_ "GenSigSwitchedByIgnition" SG_ 991 KL_Beschlagsgefahr 0;
BA_ "GenSigSendType" SG_ 991 KL_Beschlagsgefahr 0;
BA_ "GenSigSwitchedByIgnition" SG_ 991 FAS_Taster 0;
BA_ "GenSigSendType" SG_ 991 FAS_Taster 3;
BA_ "GenSigSwitchedByIgnition" SG_ 991 SP_abklappen 0;
BA_ "GenSigSendType" SG_ 991 SP_abklappen 0;
BA_ "GenSigSwitchedByIgnition" SG_ 991 SP_anklappen 0;
BA_ "GenSigSendType" SG_ 991 SP_anklappen 0;
BA_ "Fehlerwert" SG_ 991 KL_Umluftklappe_Status 15;
BA_ "GenSigSwitchedByIgnition" SG_ 991 KL_Umluftklappe_Status 0;
BA_ "GenSigStartValue" SG_ 991 KL_Umluftklappe_Status 14;
BA_ "GenSigSendType" SG_ 991 KL_Umluftklappe_Status 0;
BA_ "GenSigSwitchedByIgnition" SG_ 991 GE_amax_moeglich 0;
BA_ "GenSigStartValue" SG_ 991 GE_amax_moeglich 84;
BA_ "GenSigSendType" SG_ 991 GE_amax_moeglich 0;
BA_ "Fehlerwert" SG_ 991 KL_Geblspng_Soll 255;
BA_ "GenSigSwitchedByIgnition" SG_ 991 KL_Geblspng_Soll 0;
BA_ "GenSigSendType" SG_ 991 KL_Geblspng_Soll 0;
BA_ "GenSigSwitchedByIgnition" SG_ 991 EPS_Charisma_FahrPr 0;
BA_ "GenSigSendType" SG_ 991 EPS_Charisma_FahrPr 0;
BA_ "GenSigSwitchedByIgnition" SG_ 991 GE_Zustand_Kuppltemp 0;
BA_ "GenSigSendType" SG_ 991 GE_Zustand_Kuppltemp 0;
BA_ "GenSigSwitchedByIgnition" SG_ 173 Getriebe_11_CRC 0;
BA_ "GenSigFuncType" SG_ 173 Getriebe_11_CRC 2;
BA_ "GenSigSendType" SG_ 173 Getriebe_11_CRC 0;
BA_ "GenSigSwitchedByIgnition" SG_ 173 Getriebe_11_BZ 0;
BA_ "GenSigFuncType" SG_ 173 Getriebe_11_BZ 1;
BA_ "GenSigSendType" SG_ 173 Getriebe_11_BZ 0;
BA_ "Fehlerwert" SG_ 173 GE_MMom_Soll_02 1023;
BA_ "GenSigSwitchedByIgnition" SG_ 173 GE_MMom_Soll_02 0;
BA_ "GenSigStartValue" SG_ 173 GE_MMom_Soll_02 1022;
BA_ "GenSigSendType" SG_ 173 GE_MMom_Soll_02 0;
BA_ "Fehlerwert" SG_ 173 GE_MMom_Vorhalt_02 1023;
BA_ "GenSigSwitchedByIgnition" SG_ 173 GE_MMom_Vorhalt_02 0;
BA_ "GenSigStartValue" SG_ 173 GE_MMom_Vorhalt_02 1022;
BA_ "GenSigSendType" SG_ 173 GE_MMom_Vorhalt_02 0;
BA_ "Fehlerwert" SG_ 173 GE_Uefkt 1023;
BA_ "GenSigSwitchedByIgnition" SG_ 173 GE_Uefkt 0;
BA_ "GenSigSendType" SG_ 173 GE_Uefkt 0;
BA_ "Fehlerwert" SG_ 173 GE_Fahrstufe 15;
BA_ "GenSigSwitchedByIgnition" SG_ 173 GE_Fahrstufe 0;
BA_ "GenSigStartValue" SG_ 173 GE_Fahrstufe 1;
BA_ "GenSigSendType" SG_ 173 GE_Fahrstufe 0;
BA_ "GenSigSwitchedByIgnition" SG_ 173 GE_reserv_Fahrstufe 0;
BA_ "GenSigSendType" SG_ 173 GE_reserv_Fahrstufe 0;
BA_ "GenSigSwitchedByIgnition" SG_ 173 GE_Schaltablauf 0;
BA_ "GenSigSendType" SG_ 173 GE_Schaltablauf 0;
BA_ "GenSigSwitchedByIgnition" SG_ 173 GE_Uefkt_unplausibel 0;
BA_ "GenSigSendType" SG_ 173 GE_Uefkt_unplausibel 0;
BA_ "GenSigSwitchedByIgnition" SG_ 173 GE_MMom_Status_02 0;
BA_ "GenSigSendType" SG_ 173 GE_MMom_Status_02 0;
BA_ "GenSigSwitchedByIgnition" SG_ 173 GE_Status_Kraftschluss 0;
BA_ "GenSigSendType" SG_ 173 GE_Status_Kraftschluss 0;
BA_ "GenSigSwitchedByIgnition" SG_ 173 GE_MMom_Status 0;
BA_ "GenSigSendType" SG_ 173 GE_MMom_Status 0;
BA_ "GenSigSwitchedByIgnition" SG_ 173 GE_Freig_MMom_Vorhalt 0;
BA_ "GenSigSendType" SG_ 173 GE_Freig_MMom_Vorhalt 0;
BA_ "GenSigSwitchedByIgnition" SG_ 173 GE_Verbot_Ausblendung 0;
BA_ "GenSigSendType" SG_ 173 GE_Verbot_Ausblendung 0;
BA_ "Fehlerwert" SG_ 173 GE_Zielgang 15;
BA_ "GenSigSwitchedByIgnition" SG_ 173 GE_Zielgang 0;
BA_ "GenSigSendType" SG_ 173 GE_Zielgang 0;
BA_ "GenSigFuncType" SG_ 299 GRA_ACC_01_CRC 2;
BA_ "GenSigSendType" SG_ 299 GRA_ACC_01_CRC 0;
BA_ "GenSigFuncType" SG_ 299 GRA_ACC_01_BZ 1;
BA_ "GenSigSendType" SG_ 299 GRA_ACC_01_BZ 0;
BA_ "GenSigSendType" SG_ 299 GRA_Hauptschalter 0;
BA_ "GenSigSendType" SG_ 299 GRA_Abbrechen 0;
BA_ "GenSigSendType" SG_ 299 GRA_Typ_Hauptschalter 0;
BA_ "GenSigSendType" SG_ 299 GRA_Limiter 0;
BA_ "GenSigSendType" SG_ 299 GRA_Tip_Setzen 0;
BA_ "GenSigSendType" SG_ 299 GRA_Tip_Hoch 0;
BA_ "GenSigSendType" SG_ 299 GRA_Tip_Runter 0;
BA_ "GenSigSendType" SG_ 299 GRA_Tip_Wiederaufnahme 0;
BA_ "GenSigSendType" SG_ 299 GRA_Verstellung_Zeitluecke 0;
BA_ "GenSigSendType" SG_ 299 GRA_Codierung 0;
BA_ "Fehlerwert" SG_ 299 GRA_Fehler 1;
BA_ "GenSigSendType" SG_ 299 GRA_Fehler 0;
BA_ "GenSigFuncType" SG_ 299 GRA_LIM_Taste_verfuegbar 8;
BA_ "GenSigSendType" SG_ 299 GRA_LIM_Taste_verfuegbar 0;
BA_ "GenSigSendType" SG_ 299 GRA_Tip_Stufe_2 0;
BA_ "GenSigSendType" SG_ 299 GRA_Typ_Bedienteil 0;
BA_ "GenSigSendType" SG_ 299 GRA_reserveByte4 0;
BA_ "GenSigSendType" SG_ 299 GRA_reserveByte5 0;
BA_ "GenSigSendType" SG_ 299 GRA_reserveByte6 0;
BA_ "GenSigSendType" SG_ 299 GRA_reserveByte7 0;
BA_ "GenSigSendType" SG_ 299 GRA_reserveByte8 0;
BA_ "GenSigFuncType" SG_ 294 HCA_01_CRC 2;
BA_ "GenSigSendType" SG_ 294 HCA_01_CRC 0;
BA_ "GenSigFuncType" SG_ 294 HCA_01_BZ 1;
BA_ "GenSigSendType" SG_ 294 HCA_01_BZ 0;
BA_ "GenSigSendType" SG_ 294 HCA_01_Vib_Freq 0;
BA_ "GenSigSendType" SG_ 294 HCA_01_LM_Offset 0;
BA_ "GenSigSendType" SG_ 294 EA_ACC_Sollstatus 0;
BA_ "GenSigSendType" SG_ 294 EA_Ruckprofil 0;
BA_ "GenSigSendType" SG_ 294 HCA_01_Sendestatus 5;
BA_ "GenSigSendType" SG_ 294 HCA_01_LM_OffSign 0;
BA_ "GenSigSendType" SG_ 294 HCA_01_Status_HCA 0;
BA_ "GenSigSendType" SG_ 294 HCA_01_Vib_Amp 0;
BA_ "GenSigSendType" SG_ 294 EA_Ruckfreigabe 0;
BA_ "GenSigStartValue" SG_ 294 EA_ACC_Wunschgeschwindigkeit 1023;
BA_ "GenSigSendType" SG_ 294 EA_ACC_Wunschgeschwindigkeit 0;
BA_ "GenSigSwitchedByIgnition" SG_ 1385 HVEM_NVLeistungEmpf 0;
BA_ "GenSigSendType" SG_ 1385 HVEM_NVLeistungEmpf 3;
BA_ "GenSigSwitchedByIgnition" SG_ 1385 HVEM_DCDC_Freigabe 0;
BA_ "GenSigSendType" SG_ 1385 HVEM_DCDC_Freigabe 0;
BA_ "GenSigSwitchedByIgnition" SG_ 1385 HVEM_KlimaMaxHVStrom 0;
BA_ "GenSigSendType" SG_ 1385 HVEM_KlimaMaxHVStrom 3;
BA_ "GenSigSwitchedByIgnition" SG_ 1385 HVEM_Ladesteckerentr_Anf 0;
BA_ "GenSigSendType" SG_ 1385 HVEM_Ladesteckerentr_Anf 3;
BA_ "GenSigSwitchedByIgnition" SG_ 1385 HVEM_LeistungsAnf 0;
BA_ "GenSigSendType" SG_ 1385 HVEM_LeistungsAnf 3;
BA_ "GenSigSwitchedByIgnition" SG_ 1385 HVEM_Nachlad_Status 0;
BA_ "GenSigStartValue" SG_ 1385 HVEM_Nachlad_Status 3;
BA_ "GenSigSendType" SG_ 1385 HVEM_Nachlad_Status 3;
BA_ "GenSigSwitchedByIgnition" SG_ 1385 HVEM_Abschaltstatus 0;
BA_ "GenSigStartValue" SG_ 1385 HVEM_Abschaltstatus 7;
BA_ "GenSigSendType" SG_ 1385 HVEM_Abschaltstatus 3;
BA_ "Fehlerwert" SG_ 1385 HVEM_Anf_ReichweiteNV 3;
BA_ "GenSigSwitchedByIgnition" SG_ 1385 HVEM_Anf_ReichweiteNV 0;
BA_ "GenSigSendType" SG_ 1385 HVEM_Anf_ReichweiteNV 3;
BA_ "GenSigSwitchedByIgnition" SG_ 1385 HVEM_LadeklappenVerr_Anf 0;
BA_ "GenSigSendType" SG_ 1385 HVEM_LadeklappenVerr_Anf 3;
BA_ "GenSigSwitchedByIgnition" SG_ 1385 HVEM_HV_Anf 0;
BA_ "GenSigSendType" SG_ 1385 HVEM_HV_Anf 3;
BA_ "GenSigSwitchedByIgnition" SG_ 1385 HVEM_Text_1 0;
BA_ "GenSigSendType" SG_ 1385 HVEM_Text_1 3;
BA_ "GenSigSwitchedByIgnition" SG_ 1385 HVEM_Nachladen_Anf 0;
BA_ "GenSigSendType" SG_ 1385 HVEM_Nachladen_Anf 3;
BA_ "Fehlerwert" SG_ 1385 HVEM_FreigabeKlimatisierung 3;
BA_ "GenSigSwitchedByIgnition" SG_ 1385 HVEM_FreigabeKlimatisierung 0;
BA_ "GenSigStartValue" SG_ 1385 HVEM_FreigabeKlimatisierung 2;
BA_ "GenSigSendType" SG_ 1385 HVEM_FreigabeKlimatisierung 3;
BA_ "GenSigSwitchedByIgnition" SG_ 1879 ISO_ACC_Req_Data 0;
BA_ "GenSigFuncType" SG_ 1879 ISO_ACC_Req_Data 9;
BA_ "GenSigSendType" SG_ 1879 ISO_ACC_Req_Data 3;
BA_ "GenSigFuncType" SG_ 1985 ISO_ACC_Resp_Data 9;
BA_ "GenSigSendType" SG_ 1985 ISO_ACC_Resp_Data 3;
BA_ "GenSigSwitchedByIgnition" SG_ 1840 ISO_FLA_Req_Data 0;
BA_ "GenSigFuncType" SG_ 1840 ISO_FLA_Req_Data 9;
BA_ "GenSigSendType" SG_ 1840 ISO_FLA_Req_Data 3;
BA_ "GenSigFuncType" SG_ 1946 ISO_FLA_Resp_Data 9;
BA_ "GenSigSendType" SG_ 1946 ISO_FLA_Resp_Data 3;
BA_ "GenSigSwitchedByIgnition" SG_ 1793 ISO_01_Req_Data 0;
BA_ "GenSigFuncType" SG_ 1793 ISO_01_Req_Data 9;
BA_ "GenSigSendType" SG_ 1793 ISO_01_Req_Data 3;
BA_ "GenSigSwitchedByIgnition" SG_ 1794 ISO_02_Req_Data 0;
BA_ "GenSigFuncType" SG_ 1794 ISO_02_Req_Data 9;
BA_ "GenSigSendType" SG_ 1794 ISO_02_Req_Data 3;
BA_ "GenSigSwitchedByIgnition" SG_ 1796 ISO_04_Req_Data 0;
BA_ "GenSigFuncType" SG_ 1796 ISO_04_Req_Data 9;
BA_ "GenSigSendType" SG_ 1796 ISO_04_Req_Data 3;
BA_ "GenSigSwitchedByIgnition" SG_ 1797 ISO_05_Req_Data 0;
BA_ "GenSigFuncType" SG_ 1797 ISO_05_Req_Data 9;
BA_ "GenSigSendType" SG_ 1797 ISO_05_Req_Data 3;
BA_ "GenSigSwitchedByIgnition" SG_ 1798 ISO_06_Req_Data 0;
BA_ "GenSigFuncType" SG_ 1798 ISO_06_Req_Data 9;
BA_ "GenSigSendType" SG_ 1798 ISO_06_Req_Data 3;
BA_ "GenSigSwitchedByIgnition" SG_ 1799 ISO_07_Req_Data 0;
BA_ "GenSigFuncType" SG_ 1799 ISO_07_Req_Data 9;
BA_ "GenSigSendType" SG_ 1799 ISO_07_Req_Data 3;
BA_ "GenSigSwitchedByIgnition" SG_ 1800 ISO_08_Req_Data 0;
BA_ "GenSigFuncType" SG_ 1800 ISO_08_Req_Data 9;
BA_ "GenSigSendType" SG_ 1800 ISO_08_Req_Data 3;
BA_REL_ "GenSigTimeoutTime" BU_SG_REL_ Frontradar SG_ 262 ESP_05_CRC 500;
BA_REL_ "GenSigTimeoutTime" BU_SG_REL_ Frontsensorik SG_ 262 ESP_05_CRC 500;
BA_REL_ "GenSigTimeoutTime" BU_SG_REL_ Frontradar SG_ 262 ESP_05_BZ 500;
BA_REL_ "GenSigTimeoutTime" BU_SG_REL_ Frontsensorik SG_ 262 ESP_05_BZ 500;
BA_REL_ "GenSigTimeoutTime" BU_SG_REL_ Frontradar SG_ 262 ESP_QBit_Bremsdruck 500;
BA_REL_ "GenSigTimeoutTime" BU_SG_REL_ Frontsensorik SG_ 262 ESP_QBit_Bremsdruck 500;
BA_REL_ "GenSigTimeoutTime" BU_SG_REL_ Frontradar SG_ 262 ESP_QBit_Fahrer_bremst 500;
BA_REL_ "GenSigTimeoutTime" BU_SG_REL_ Frontradar SG_ 262 ESP_Bremsdruck 500;
BA_REL_ "GenSigTimeoutTime" BU_SG_REL_ Frontsensorik SG_ 262 ESP_Bremsdruck 500;
BA_REL_ "GenSigTimeoutTime" BU_SG_REL_ Frontradar SG_ 262 ESP_Fahrer_bremst 500;
BA_REL_ "GenSigTimeoutTime" BU_SG_REL_ Frontradar SG_ 262 ESP_Status_Bremsentemp 500;
BA_REL_ "GenSigTimeoutTime" BU_SG_REL_ Frontradar SG_ 262 ESP_Autohold_Standby 500;
BA_REL_ "GenSigTimeoutTime" BU_SG_REL_ Frontradar SG_ 262 ESP_HDC_Standby 500;
BA_REL_ "GenSigTimeoutTime" BU_SG_REL_ Frontradar SG_ 262 ESP_HDC_aktiv 500;
BA_REL_ "GenSigTimeoutTime" BU_SG_REL_ Frontradar SG_ 262 ESP_Autohold_aktiv 500;
BA_REL_ "GenSigTimeoutTime" BU_SG_REL_ Frontradar SG_ 262 ESP_Verz_EPB_aktiv 500;
BA_REL_ "GenSigTimeoutTime" BU_SG_REL_ Frontradar SG_ 262 ESP_Status_Bremsdruck 500;
BA_REL_ "GenSigTimeoutTime" BU_SG_REL_ Frontsensorik SG_ 262 ESP_Status_Bremsdruck 500;
BA_REL_ "GenSigTimeoutTime" BU_SG_REL_ Frontradar SG_ 278 ESP_10_CRC 500;
BA_REL_ "GenSigTimeoutTime" BU_SG_REL_ Frontradar SG_ 278 ESP_10_BZ 500;
BA_REL_ "GenSigTimeoutTime" BU_SG_REL_ Frontradar SG_ 278 ESP_QBit_Wegimpuls_VL 500;
BA_REL_ "GenSigTimeoutTime" BU_SG_REL_ Frontradar SG_ 278 ESP_QBit_Wegimpuls_VR 500;
BA_REL_ "GenSigTimeoutTime" BU_SG_REL_ Frontradar SG_ 278 ESP_QBit_Wegimpuls_HL 500;
BA_REL_ "GenSigTimeoutTime" BU_SG_REL_ Frontradar SG_ 278 ESP_QBit_Wegimpuls_HR 500;
BA_REL_ "GenSigTimeoutTime" BU_SG_REL_ Frontradar SG_ 278 ESP_Wegimpuls_VL 500;
BA_REL_ "GenSigTimeoutTime" BU_SG_REL_ Frontradar SG_ 278 ESP_Wegimpuls_VR 500;
BA_REL_ "GenSigTimeoutTime" BU_SG_REL_ Frontradar SG_ 278 ESP_Wegimpuls_HL 500;
BA_REL_ "GenSigTimeoutTime" BU_SG_REL_ Frontradar SG_ 278 ESP_Wegimpuls_HR 500;
BA_REL_ "GenSigTimeoutTime" BU_SG_REL_ Frontradar SG_ 278 ESP_VL_Fahrtrichtung 500;
BA_REL_ "GenSigTimeoutTime" BU_SG_REL_ Frontradar SG_ 278 ESP_VR_Fahrtrichtung 500;
BA_REL_ "GenSigTimeoutTime" BU_SG_REL_ Frontradar SG_ 278 ESP_HL_Fahrtrichtung 500;
BA_REL_ "GenSigTimeoutTime" BU_SG_REL_ Frontradar SG_ 278 ESP_HR_Fahrtrichtung 500;
BA_REL_ "GenSigTimeoutTime" BU_SG_REL_ Frontradar SG_ 418 ESP_15_CRC 2000;
BA_REL_ "GenSigTimeoutTime" BU_SG_REL_ Frontradar SG_ 418 ESP_15_BZ 2000;
BA_REL_ "GenSigTimeoutTime" BU_SG_REL_ Frontradar SG_ 418 HMS_Systemstatus 2000;
BA_REL_ "GenSigTimeoutTime" BU_SG_REL_ Frontradar SG_ 418 HMS_aktives_System 2000;
BA_REL_ "GenSigTimeoutTime" BU_SG_REL_ Frontradar SG_ 418 HMS_Fehlerstatus 2000;
BA_REL_ "GenSigTimeoutTime" BU_SG_REL_ Frontradar SG_ 178 ESP_HL_Radgeschw_02 500;
BA_REL_ "GenSigTimeoutTime" BU_SG_REL_ Frontradar SG_ 178 ESP_HR_Radgeschw_02 500;
BA_REL_ "GenSigTimeoutTime" BU_SG_REL_ Frontradar SG_ 178 ESP_VL_Radgeschw_02 500;
BA_REL_ "GenSigTimeoutTime" BU_SG_REL_ Frontradar SG_ 178 ESP_VR_Radgeschw_02 500;
BA_REL_ "GenSigTimeoutTime" BU_SG_REL_ Frontradar SG_ 1629 ESP_20_CRC 5000;
BA_REL_ "GenSigTimeoutTime" BU_SG_REL_ Frontsensorik SG_ 1629 ESP_20_CRC 5000;
BA_REL_ "GenSigTimeoutTime" BU_SG_REL_ Frontradar SG_ 1629 ESP_20_BZ 5000;
BA_REL_ "GenSigTimeoutTime" BU_SG_REL_ Frontsensorik SG_ 1629 ESP_20_BZ 5000;
BA_REL_ "GenSigTimeoutTime" BU_SG_REL_ Frontradar SG_ 1629 ESP_Zaehnezahl 5000;
BA_REL_ "GenSigTimeoutTime" BU_SG_REL_ Frontsensorik SG_ 1629 ESP_Zaehnezahl 5000;
BA_REL_ "GenSigTimeoutTime" BU_SG_REL_ Frontradar SG_ 1629 BR_QBit_Reifenumfang 5000;
BA_REL_ "GenSigTimeoutTime" BU_SG_REL_ Frontsensorik SG_ 1629 BR_QBit_Reifenumfang 5000;
BA_REL_ "GenSigTimeoutTime" BU_SG_REL_ Frontradar SG_ 1629 BR_Reifenumfang 5000;
BA_REL_ "GenSigTimeoutTime" BU_SG_REL_ Frontsensorik SG_ 1629 BR_Reifenumfang 5000;
BA_REL_ "GenSigTimeoutTime" BU_SG_REL_ Frontradar SG_ 253 ESP_21_CRC 500;
BA_REL_ "GenSigTimeoutTime" BU_SG_REL_ Frontsensorik SG_ 253 ESP_21_CRC 500;
BA_REL_ "GenSigTimeoutTime" BU_SG_REL_ Frontradar SG_ 253 ESP_21_BZ 500;
BA_REL_ "GenSigTimeoutTime" BU_SG_REL_ Frontsensorik SG_ 253 ESP_21_BZ 500;
BA_REL_ "GenSigTimeoutTime" BU_SG_REL_ Frontradar SG_ 253 ESP_Diagnose 500;
BA_REL_ "GenSigTimeoutTime" BU_SG_REL_ Frontradar SG_ 253 ESP_v_Signal 500;
BA_REL_ "GenSigTimeoutTime" BU_SG_REL_ Frontsensorik SG_ 253 ESP_v_Signal 500;
BA_REL_ "GenSigTimeoutTime" BU_SG_REL_ Frontradar SG_ 253 ASR_Tastung_passiv 500;
BA_REL_ "GenSigTimeoutTime" BU_SG_REL_ Frontsensorik SG_ 253 ASR_Tastung_passiv 500;
BA_REL_ "GenSigTimeoutTime" BU_SG_REL_ Frontradar SG_ 253 ESP_Tastung_passiv 500;
BA_REL_ "GenSigTimeoutTime" BU_SG_REL_ Frontsensorik SG_ 253 ESP_Tastung_passiv 500;
BA_REL_ "GenSigTimeoutTime" BU_SG_REL_ Frontradar SG_ 253 ESP_Systemstatus 500;
BA_REL_ "GenSigTimeoutTime" BU_SG_REL_ Frontradar SG_ 253 ESP_Haltebestaetigung 500;
BA_REL_ "GenSigTimeoutTime" BU_SG_REL_ Frontradar SG_ 253 ESP_QBit_v_Signal 500;
BA_REL_ "GenSigTimeoutTime" BU_SG_REL_ Frontsensorik SG_ 253 ESP_QBit_v_Signal 500;
BA_REL_ "GenSigTimeoutTime" BU_SG_REL_ Frontradar SG_ 253 ABS_Bremsung 500;
BA_REL_ "GenSigTimeoutTime" BU_SG_REL_ Frontsensorik SG_ 253 ABS_Bremsung 500;
BA_REL_ "GenSigTimeoutTime" BU_SG_REL_ Frontradar SG_ 253 ASR_Anf 500;
BA_REL_ "GenSigTimeoutTime" BU_SG_REL_ Frontradar SG_ 253 MSR_Anf 500;
BA_REL_ "GenSigTimeoutTime" BU_SG_REL_ Frontradar SG_ 253 EBV_Eingriff 500;
BA_REL_ "GenSigTimeoutTime" BU_SG_REL_ Frontradar SG_ 253 EDS_Eingriff 500;
BA_REL_ "GenSigTimeoutTime" BU_SG_REL_ Frontradar SG_ 253 ESP_Eingriff 500;
BA_REL_ "GenSigTimeoutTime" BU_SG_REL_ Frontsensorik SG_ 253 ESP_Eingriff 500;
BA_REL_ "GenSigTimeoutTime" BU_SG_REL_ Frontradar SG_ 253 ESP_ASP 500;
BA_REL_ "GenSigTimeoutTime" BU_SG_REL_ Frontradar SG_ 427 ESP_33_CRC 2000;
BA_REL_ "GenSigTimeoutTime" BU_SG_REL_ Frontradar SG_ 427 ESP_33_BZ 2000;
BA_REL_ "GenSigTimeoutTime" BU_SG_REL_ Frontradar SG_ 427 ESC_AHW_aktiv 2000;
BA_REL_ "GenSigTimeoutTime" BU_SG_REL_ Frontradar SG_ 427 ESC_AHW_nicht_verfuegbar 2000;
BA_REL_ "GenSigTimeoutTime" BU_SG_REL_ Frontradar SG_ 427 ESC_ANB_CM_aktiv 2000;
BA_REL_ "GenSigTimeoutTime" BU_SG_REL_ Frontradar SG_ 427 ESC_ANB_CM_nicht_verfuegbar 2000;
BA_REL_ "GenSigTimeoutTime" BU_SG_REL_ Frontradar SG_ 427 ESC_Warnruck_aktiv 2000;
BA_REL_ "GenSigTimeoutTime" BU_SG_REL_ Frontradar SG_ 427 ESC_Warnruck_nicht_verfuegbar 2000;
BA_REL_ "GenSigTimeoutTime" BU_SG_REL_ Frontradar SG_ 427 ESC_Prefill_aktiv 2000;
BA_REL_ "GenSigTimeoutTime" BU_SG_REL_ Frontradar SG_ 427 ESC_Prefill_nicht_verfuegbar 2000;
BA_REL_ "GenSigTimeoutTime" BU_SG_REL_ Frontradar SG_ 427 ESC_HBA_aktiv 2000;
BA_REL_ "GenSigTimeoutTime" BU_SG_REL_ Frontradar SG_ 427 ESC_HBA_nicht_verfuegbar 2000;
BA_REL_ "GenSigTimeoutTime" BU_SG_REL_ Frontradar SG_ 427 ESC_TSK_SRBM_Anf 2000;
BA_REL_ "GenSigTimeoutTime" BU_SG_REL_ Frontradar SG_ 427 ESC_Verz_Reg_aktiv 2000;
BA_REL_ "GenSigTimeoutTime" BU_SG_REL_ Frontradar SG_ 427 ESC_Verz_Reg_nicht_verfuegbar 2000;
BA_REL_ "GenSigTimeoutTime" BU_SG_REL_ Frontradar SG_ 427 ESC_Verz_Reg_TB_nicht_verfuegbar 2000;
BA_REL_ "GenSigTimeoutTime" BU_SG_REL_ Frontradar SG_ 427 ESC_Verz_Reg_ZB_nicht_verfuegbar 2000;
BA_REL_ "GenSigTimeoutTime" BU_SG_REL_ Frontradar SG_ 427 ESC_Bremslicht_unplausibel 2000;
BA_REL_ "GenSigTimeoutTime" BU_SG_REL_ Frontradar SG_ 427 ESC_Konsistenz_ACC 2000;
BA_REL_ "GenSigTimeoutTime" BU_SG_REL_ Frontradar SG_ 427 ESC_Konsistenz_AWV 2000;
BA_REL_ "GenSigTimeoutTime" BU_SG_REL_ Frontradar SG_ 427 ESC_Verz_ASIL_Verfuegbarkeit 2000;
BA_REL_ "GenSigTimeoutTime" BU_SG_REL_ Frontradar SG_ 427 ESC_Pumpenanlauf_aktiv 2000;
BA_REL_ "GenSigTimeoutTime" BU_SG_REL_ Frontradar SG_ 1332 FCWP_Warnlevel 2000;
BA_REL_ "GenSigTimeoutTime" BU_SG_REL_ Frontradar SG_ 987 BCM_01_alt 1000;
BA_REL_ "GenSigTimeoutTime" BU_SG_REL_ Frontsensorik SG_ 987 BCM_01_alt 1000;
BA_REL_ "GenSigTimeoutTime" BU_SG_REL_ Frontradar SG_ 987 SMLS_01_alt 1000;
BA_REL_ "GenSigTimeoutTime" BU_SG_REL_ Frontsensorik SG_ 987 SMLS_01_alt 1000;
BA_REL_ "GenSigTimeoutTime" BU_SG_REL_ Frontradar SG_ 987 ZV_02_alt 1000;
BA_REL_ "GenSigTimeoutTime" BU_SG_REL_ Frontradar SG_ 987 Wischer_01_alt 1000;
BA_REL_ "GenSigTimeoutTime" BU_SG_REL_ Frontsensorik SG_ 987 Wischer_01_alt 1000;
BA_REL_ "GenSigTimeoutTime" BU_SG_REL_ Frontradar SG_ 987 Anhaenger_01_alt 1000;
BA_REL_ "GenSigTimeoutTime" BU_SG_REL_ Frontsensorik SG_ 987 Anhaenger_01_alt 1000;
BA_REL_ "GenSigTimeoutTime" BU_SG_REL_ Frontradar SG_ 987 Klima_Sensor_02_alt 1000;
BA_REL_ "GenSigTimeoutTime" BU_SG_REL_ Frontsensorik SG_ 987 Klima_Sensor_02_alt 1000;
BA_REL_ "GenSigTimeoutTime" BU_SG_REL_ Frontradar SG_ 987 WFS_01_alt 1000;
BA_REL_ "GenSigTimeoutTime" BU_SG_REL_ Frontsensorik SG_ 987 WFS_01_alt 1000;
BA_REL_ "GenSigTimeoutTime" BU_SG_REL_ Frontradar SG_ 987 ZV_HFS_offen 1000;
BA_REL_ "GenSigTimeoutTime" BU_SG_REL_ Frontradar SG_ 987 ZV_HBFS_offen 1000;
BA_REL_ "GenSigTimeoutTime" BU_SG_REL_ Frontradar SG_ 987 ZV_BT_offen 1000;
BA_REL_ "GenSigTimeoutTime" BU_SG_REL_ Frontradar SG_ 987 BCM1_Rueckfahrlicht_Schalter 1000;
BA_REL_ "GenSigTimeoutTime" BU_SG_REL_ Frontsensorik SG_ 987 BCM1_Rueckfahrlicht_Schalter 1000;
BA_REL_ "GenSigTimeoutTime" BU_SG_REL_ Frontradar SG_ 987 ZV_FT_offen 1000;
BA_REL_ "GenSigTimeoutTime" BU_SG_REL_ Frontradar SG_ 987 Wischer_vorne_aktiv 1000;
BA_REL_ "GenSigTimeoutTime" BU_SG_REL_ Frontsensorik SG_ 987 Wischer_vorne_aktiv 1000;
BA_REL_ "GenSigTimeoutTime" BU_SG_REL_ Frontradar SG_ 987 AAG_Anhaenger_erkannt 1000;
BA_REL_ "GenSigTimeoutTime" BU_SG_REL_ Frontsensorik SG_ 987 AAG_Anhaenger_erkannt 1000;
BA_REL_ "GenSigTimeoutTime" BU_SG_REL_ Frontradar SG_ 987 BCM1_MH_Schalter 1000;
BA_REL_ "GenSigTimeoutTime" BU_SG_REL_ Frontradar SG_ 987 WFS_Schluessel_Fahrberecht 1000;
BA_REL_ "GenSigTimeoutTime" BU_SG_REL_ Frontsensorik SG_ 987 WFS_Schluessel_Fahrberecht 1000;
BA_REL_ "GenSigTimeoutTime" BU_SG_REL_ Frontradar SG_ 987 WWSs_01_alt 1000;
BA_REL_ "GenSigTimeoutTime" BU_SG_REL_ Frontsensorik SG_ 987 WWSs_01_alt 1000;
BA_REL_ "GenSigTimeoutTime" BU_SG_REL_ Frontsensorik SG_ 987 BH_Fernlicht 1000;
BA_REL_ "GenSigTimeoutTime" BU_SG_REL_ Frontradar SG_ 987 BH_Blinker_li 1000;
BA_REL_ "GenSigTimeoutTime" BU_SG_REL_ Frontsensorik SG_ 987 BH_Blinker_li 1000;
BA_REL_ "GenSigTimeoutTime" BU_SG_REL_ Frontradar SG_ 987 BH_Blinker_re 1000;
BA_REL_ "GenSigTimeoutTime" BU_SG_REL_ Frontsensorik SG_ 987 BH_Blinker_re 1000;
BA_REL_ "GenSigTimeoutTime" BU_SG_REL_ Frontradar SG_ 987 BCM1_Aussen_Temp_ungef 1000;
BA_REL_ "GenSigTimeoutTime" BU_SG_REL_ Frontsensorik SG_ 987 BCM1_Aussen_Temp_ungef 1000;
BA_REL_ "GenSigTimeoutTime" BU_SG_REL_ Frontradar SG_ 988 Motor_12_alt 500;
BA_REL_ "GenSigTimeoutTime" BU_SG_REL_ Frontradar SG_ 988 ESP_07_alt 500;
BA_REL_ "GenSigTimeoutTime" BU_SG_REL_ Frontradar SG_ 988 Getriebe_13_alt 500;
BA_REL_ "GenSigTimeoutTime" BU_SG_REL_ Frontradar SG_ 988 Getriebe_17_alt 500;
BA_REL_ "GenSigTimeoutTime" BU_SG_REL_ Frontradar SG_ 988 MO_QBit_Drehzahl_01 500;
BA_REL_ "GenSigTimeoutTime" BU_SG_REL_ Frontradar SG_ 988 MKE_Texte 500;
BA_REL_ "GenSigTimeoutTime" BU_SG_REL_ Frontradar SG_ 988 MKE_Stufe 500;
BA_REL_ "GenSigTimeoutTime" BU_SG_REL_ Frontradar SG_ 988 MO_Drehzahl_01 500;
BA_REL_ "GenSigTimeoutTime" BU_SG_REL_ Frontradar SG_ 988 GE_Notlauf 500;
BA_REL_ "GenSigTimeoutTime" BU_SG_REL_ Frontradar SG_ 988 ESP_Rollenmodus_Deaktivieren 500;
BA_REL_ "GenSigTimeoutTime" BU_SG_REL_ Frontradar SG_ 988 GE_Freilauf_Status 500;
BA_REL_ "GenSigTimeoutTime" BU_SG_REL_ Frontsensorik SG_ 991 Innenlicht_11_alt 1000;
BA_REL_ "GenSigTimeoutTime" BU_SG_REL_ Frontradar SG_ 991 Anhaenger_01_alt 1000;
BA_REL_ "GenSigTimeoutTime" BU_SG_REL_ Frontradar SG_ 991 Licht_hinten_01_alt 1000;
BA_REL_ "GenSigTimeoutTime" BU_SG_REL_ Frontsensorik SG_ 991 LH_EPS_01_alt 1000;
BA_REL_ "GenSigTimeoutTime" BU_SG_REL_ Frontsensorik SG_ 991 Klima_12_alt 1000;
BA_REL_ "GenSigTimeoutTime" BU_SG_REL_ Frontsensorik SG_ 991 SMLS_01_alt 1000;
BA_REL_ "GenSigTimeoutTime" BU_SG_REL_ Frontradar SG_ 991 Getriebe_14_alt 1000;
BA_REL_ "GenSigTimeoutTime" BU_SG_REL_ Frontradar SG_ 991 PLA_01_alt 1000;
BA_REL_ "GenSigTimeoutTime" BU_SG_REL_ Frontradar SG_ 991 PLA_Status_PLA_EPS 1000;
BA_REL_ "GenSigTimeoutTime" BU_SG_REL_ Frontsensorik SG_ 991 IL_Innenlicht_aktiv 1000;
BA_REL_ "GenSigTimeoutTime" BU_SG_REL_ Frontsensorik SG_ 991 FAS_Taster_Fehler 1000;
BA_REL_ "GenSigTimeoutTime" BU_SG_REL_ Frontradar SG_ 991 AAG_Bremslicht_H_def 1000;
BA_REL_ "GenSigTimeoutTime" BU_SG_REL_ Frontradar SG_ 991 LH_3_Bremsl_def 1000;
BA_REL_ "GenSigTimeoutTime" BU_SG_REL_ Frontradar SG_ 991 LH_Bremsl_li_ges_def 1000;
BA_REL_ "GenSigTimeoutTime" BU_SG_REL_ Frontradar SG_ 991 LH_Bremsl_re_ges_def 1000;
BA_REL_ "GenSigTimeoutTime" BU_SG_REL_ Frontsensorik SG_ 991 KL_Beschlagsgefahr 1000;
BA_REL_ "GenSigTimeoutTime" BU_SG_REL_ Frontsensorik SG_ 991 FAS_Taster 1000;
BA_REL_ "GenSigTimeoutTime" BU_SG_REL_ Frontradar SG_ 991 GE_amax_moeglich 1000;
BA_REL_ "GenSigTimeoutTime" BU_SG_REL_ Frontsensorik SG_ 991 EPS_Charisma_FahrPr 1000;
BA_REL_ "GenSigTimeoutTime" BU_SG_REL_ Frontradar SG_ 991 GE_Zustand_Kuppltemp 1000;
BA_REL_ "GenSigTimeoutTime" BU_SG_REL_ Frontradar SG_ 173 Getriebe_11_CRC 500;
BA_REL_ "GenSigTimeoutTime" BU_SG_REL_ Frontradar SG_ 173 Getriebe_11_BZ 500;
BA_REL_ "GenSigTimeoutTime" BU_SG_REL_ Frontradar SG_ 173 GE_Fahrstufe 500;
BA_REL_ "GenSigTimeoutTime" BU_SG_REL_ Frontradar SG_ 299 GRA_ACC_01_CRC 500;
BA_REL_ "GenSigTimeoutTime" BU_SG_REL_ Frontradar SG_ 299 GRA_ACC_01_BZ 500;
BA_REL_ "GenSigTimeoutTime" BU_SG_REL_ Frontradar SG_ 299 GRA_Hauptschalter 500;
BA_REL_ "GenSigTimeoutTime" BU_SG_REL_ Frontradar SG_ 299 GRA_Abbrechen 500;
BA_REL_ "GenSigTimeoutTime" BU_SG_REL_ Frontradar SG_ 299 GRA_Typ_Hauptschalter 500;
BA_REL_ "GenSigTimeoutTime" BU_SG_REL_ Frontradar SG_ 299 GRA_Tip_Setzen 500;
BA_REL_ "GenSigTimeoutTime" BU_SG_REL_ Frontradar SG_ 299 GRA_Tip_Hoch 500;
BA_REL_ "GenSigTimeoutTime" BU_SG_REL_ Frontradar SG_ 299 GRA_Tip_Runter 500;
BA_REL_ "GenSigTimeoutTime" BU_SG_REL_ Frontradar SG_ 299 GRA_Tip_Wiederaufnahme 500;
BA_REL_ "GenSigTimeoutTime" BU_SG_REL_ Frontradar SG_ 299 GRA_Verstellung_Zeitluecke 500;
BA_REL_ "GenSigTimeoutTime" BU_SG_REL_ Frontradar SG_ 299 GRA_Codierung 500;
BA_REL_ "GenSigTimeoutTime" BU_SG_REL_ Frontradar SG_ 299 GRA_Fehler 500;
BA_REL_ "GenSigTimeoutTime" BU_SG_REL_ Frontradar SG_ 299 GRA_Tip_Stufe_2 500;
BA_REL_ "GenSigTimeoutTime" BU_SG_REL_ Frontradar SG_ 299 GRA_Typ_Bedienteil 500;
BA_REL_ "GenSigTimeoutTime" BU_SG_REL_ Frontradar SG_ 294 EA_ACC_Sollstatus 5000;
BA_REL_ "GenSigTimeoutTime" BU_SG_REL_ Frontradar SG_ 294 EA_ACC_Wunschgeschwindigkeit 5000;
VAL_ 262 ESP_QBit_Bremsdruck 0 "gueltiger_Wert" 1 "Ersatz_Init_oder_Fehlerwert" ;
VAL_ 262 ESP_QBit_Fahrer_bremst 0 "gueltiger_Wert" 1 "Ersatz_Init_oder_Fehlerwert" ;
VAL_ 262 ESP_Schwelle_Unterdruck 0 "kein_Signal" 1 "Unterdruck_kleiner_gleich_450_mbar" 2 "Unterdruck_groesser_450_mbar" 3 "Fehler_Unterdrucksensor" ;
VAL_ 262 ESP_Bremsdruck 1023 "Fehler" ;
VAL_ 262 ESP_Fahrer_bremst 0 "Bremsdruckschwelle_nicht_ueberschritten" 1 "Bremsdruckschwelle_ueberschritten" ;
VAL_ 262 ESP_Verz_TSK_aktiv 0 "TSK_Verzoegerung_inaktiv" 1 "TSK_Verzoegerung_aktiv" ;
VAL_ 262 ESP_Lenkeingriff_ADS 0 "kein_Lenkeingriff" 1 "stabilisierender_Lenkeingriff" ;
VAL_ 262 ESP_Konsistenz_TSK 0 "Botschaft_fuer_Verzoegerungsanforderung_konsistent" 1 "Botschaft_fuer_Verzoegerungsanforderung_nicht_konsistent" ;
VAL_ 262 ESP_Bremsruck_AWV2 0 "kein_Bremsruck_ausgefuehrt" 1 "Bremsruck_ausgefuehrt" ;
VAL_ 262 ESP_Konsistenz_AWV2 0 "Botschaft_fuer_AWV2_konsistent" 1 "Botschaft_fuer_AWV2_nicht_konsistent" ;
VAL_ 262 ECD_Fehler 0 "ECD_iO" 1 "ECD_Fehler" ;
VAL_ 262 ECD_nicht_verfuegbar 0 "ECD_Funktion_verfuegbar" 1 "ECD_Funktion_nicht_verfuegbar" ;
VAL_ 262 ESP_Status_Bremsentemp 0 "Bremse_nicht_ueberhitzt" 1 "Bremse_ueberhitzt" ;
VAL_ 262 ESP_Autohold_Standby 0 "Autohold_nicht_im_Standby" 1 "Autohold_im_Standby" ;
VAL_ 262 ESP_HDC_Standby 0 "HDC_Funktion_nicht_im_Standby" 1 "HDC_Funktion_im_Standby" ;
VAL_ 262 ESP_HBA_aktiv 0 "HBA_nicht_aktiv" 1 "HBA_aktiv" ;
VAL_ 262 ESP_Prefill_ausgeloest 0 "nicht_ausgeloest" 1 "Prefill_ausgeloest" ;
VAL_ 262 ESP_Rueckwaertsfahrt_erkannt 0 "keine_Rueckwaetsfahrt" 1 "Rueckwaertsfahrt_sicher_erkannt" ;
VAL_ 262 ESP_Status_Anfahrhilfe 0 "Aus" 1 "Ein" ;
VAL_ 262 ESP_HDC_aktiv 0 "inaktiv" 1 "aktiv" ;
VAL_ 262 ESP_StartStopp_Info 0 "Motorlauf_nicht_notwendig_(Stoppfreigabe)" 1 "Motoranlauf_nicht_zwingend_notwendig_(Stoppverbot,keine_Startanforderung)" 2 "Motoranlauf_zwingend_notwendig_(Startanforderung)" 3 "Systemfehler" ;
VAL_ 262 ESP_Eingr_HL 0 "kein_Eingriff" 1 "ESP_Eingriff_HL" ;
VAL_ 262 ESP_Eingr_HR 0 "kein_Eingriff" 1 "ESP_Eingriff_HR" ;
VAL_ 262 ESP_Eingr_VL 0 "kein_Eingriff" 1 "ESP_Eingriff_VL" ;
VAL_ 262 ESP_Eingr_VR 0 "kein_Eingriff" 1 "ESP_Eingriff_VR" ;
VAL_ 262 ESP_BKV_Unterdruck 0 "nicht_verbaut_oder_nicht_kodiert" 254 "Init" 255 "Fehler" ;
VAL_ 262 ESP_Autohold_aktiv 0 "Autohold_inaktiv" 1 "Autohold_aktiv" ;
VAL_ 262 ESP_FStatus_Anfahrhilfe 0 "kein_Fehler" 1 "Fehler" ;
VAL_ 262 ESP_Verz_EPB_aktiv 0 "nicht_aktiviert" 1 "aktiviert" ;
VAL_ 262 ECD_Bremslicht 0 "Aus" 1 "Ein" ;
VAL_ 262 ESP_Verzoeg_EPB_verf 0 "nicht_verfuegbar" 1 "System_verfuegbar" ;
VAL_ 262 ESP_Status_Bremsdruck 0 "Bremse_drucklos" 1 "mit_Bremsdruck" ;
VAL_ 262 ESP_Anforderung_EPB 0 "keine_Anforderung" 1 "Anforderung_Oeffnen" 2 "Anforderung_Schliessen" 3 "reserviert" ;
VAL_ 286 ESP_ANB_CM_Rueckk_Umsetz 0 "keine_Ausfuehrung" 1 "Ausfuehrung" ;
VAL_ 286 ESP_Konsistenz_ACC_Botschaft 0 "Botschaft_fuer_ACC_konsistent" 1 "Botschaft_fuer_ACC_nicht_konsistent" ;
VAL_ 286 ESP_Stillstandsphase_erschoepft 0 "sicheres_Halten_moeglich" 1 "kein_sicheres_Halten_moeglich" ;
VAL_ 286 ESP_ZT_Rueckk_Umsetz 0 "keine_Ausfuehrung" 1 "Ausfuehrung" ;
VAL_ 286 ESP_Tuerkontakt_Fahrertuer 0 "Schalter_geschlossen" 1 "Schalter_offen" ;
VAL_ 286 ESP_Abrutschen_Stillstand 0 "kein_Abrutschen_erkannt" 1 "Abrutschen_erkannt" ;
VAL_ 286 ESP_Fahrer_tritt_ZBR_Schw 0 "Fahrer_uebertritt_ZBR_Schwelle_nicht" 1 "Fahrer_uebertritt_ZBR_Schwelle" ;
VAL_ 286 ESP_QBit_v_ref 0 "gueltiger_Wert" 1 "Ersatz_Init_oder_Fehlerwert" ;
VAL_ 286 ESP_v_ref_Fahrtrichtung 0 "Fahrtrichtung_nicht_definiert" 1 "Vorwaerts" 2 "Rueckwaerts" 3 "Stillstand" ;
VAL_ 286 ESC_Bremsdruckgradient 251 "groesser_2500_bar_per_sec" 254 "Init" 255 "Fehler" ;
VAL_ 286 ESP_v_ref 4093 "Unterspannung" 4094 "Init" 4095 "Fehler" ;
VAL_ 278 ESP_QBit_Wegimpuls_VL 0 "gueltiger_Wert" 1 "Ersatz_Init_oder_Fehlerwert" ;
VAL_ 278 ESP_QBit_Wegimpuls_VR 0 "gueltiger_Wert" 1 "Ersatz_Init_oder_Fehlerwert" ;
VAL_ 278 ESP_QBit_Wegimpuls_HL 0 "gueltiger_Wert" 1 "Ersatz_Init_oder_Fehlerwert" ;
VAL_ 278 ESP_QBit_Wegimpuls_HR 0 "gueltiger_Wert" 1 "Ersatz_Init_oder_Fehlerwert" ;
VAL_ 278 ESP_Wegimpuls_VL 1021 "Init" 1022 "Unterspannung" 1023 "Fehler" ;
VAL_ 278 ESP_Wegimpuls_VR 1021 "Init" 1022 "Unterspannung" 1023 "Fehler" ;
VAL_ 278 ESP_Wegimpuls_HL 1021 "Init" 1022 "Unterspannung" 1023 "Fehler" ;
VAL_ 278 ESP_Wegimpuls_HR 1021 "Init" 1022 "Unterspannung" 1023 "Fehler" ;
VAL_ 278 ESP_VL_Fahrtrichtung 0 "Vorwaerts" 1 "Rueckwaerts" 2 "Init" 3 "ungueltig_oder_nicht_verbaut" ;
VAL_ 278 ESP_VR_Fahrtrichtung 0 "Vorwaerts" 1 "Rueckwaerts" 2 "Init" 3 "ungueltig_oder_nicht_verbaut" ;
VAL_ 278 ESP_HL_Fahrtrichtung 0 "Vorwaerts" 1 "Rueckwaerts" 2 "Init" 3 "ungueltig_oder_nicht_verbaut" ;
VAL_ 278 ESP_HR_Fahrtrichtung 0 "Vorwaerts" 1 "Rueckwaerts" 2 "Init" 3 "ungueltig_oder_nicht_verbaut" ;
VAL_ 418 HMS_P_beibehalten_GE 0 "P_nicht_beibehalten" 1 "P_beibehalten" 2 "Init" 3 "Fehler" ;
VAL_ 418 HMS_Konsistenz_GE 0 "kein_Fehler_erkannt" 1 "Fehler_erkannt" ;
VAL_ 418 HMS_Konsistenz_IPA 0 "kein_Fehler_erkannt" 1 "Fehler_erkannt" ;
VAL_ 418 HMS_Konsistenz_EBKV 0 "kein_Fehler_erkannt" 1 "Fehler_erkannt" ;
VAL_ 418 HMS_Konsistenz_RCTA 0 "kein_Fehler_erkannt" 1 "Fehler_erkannt" ;
VAL_ 418 HMS_Konsistenz_STA 0 "kein_Fehler_erkannt" 1 "Fehler_erkannt" ;
VAL_ 418 HMS_Konsistenz_MO 0 "kein_Fehler_erkannt" 1 "Fehler_erkannt" ;
VAL_ 418 HMS_halten_nicht_verfuegbar 0 "verfuegbar" 1 "nicht_verfuegbar" ;
VAL_ 418 NL_PRIM_STP_01_Status 0 "Primaersystem_Notlauf_off" 1 "Primaersystem_Notlauf_inaktiv" 2 "Primaersystem_Notlauf_standby" 3 "Primaersystem_Notlauf_ready" 4 "Primaersystem_Notlauf_aktiv" 5 "Primaersystem_Notlauf_nicht_verf" ;
VAL_ 418 HMS_Notstopp_Status 0 "Off_Init" 1 "Inaktiv" 2 "Ready" 3 "Aktiv" 7 "nicht_Verfuegbar" ;
VAL_ 418 HMS_parken_nicht_verfuegbar 0 "verfuegbar" 1 "nicht_verfuegbar" ;
VAL_ 418 HMS_Anforderung_GE 0 "keine_Anforderung" 1 "P_einlegen" ;
VAL_ 418 HMS_Systemstatus 0 "keine_Funktion_aktiv" 1 "Halten_aktiv" 2 "Parken_angefordert" 3 "Parken_aktiv" 4 "Parken_beibehalten_aktiv" 5 "Anfahren_aktiv" 6 "Loeseanforderung_aktiv" 7 "Loeseanforderung_durch_Fahrer" 8 "Abrutschen_erkannt" 9 "Halten_Standby_aktiv" 10 "Anfahren_Standby_aktiv" 14 "Init" 15 "Fehler" ;
VAL_ 418 HMS_Stillstand 0 "kein_Stillstand" 1 "Stillstand_frueh" 2 "Stillstand" 6 "Init" 7 "Fehler" ;
VAL_ 418 HMS_aktives_System 0 "kein_System__Init_Fehler" 1 "Fahreranforderung_aktiv" 2 "HMS_intern_aktiv" 3 "ACC_aktiv" 4 "Autohold_aktiv" 5 "HHC_aktiv" 6 "HVLM_aktiv" 7 "Getriebe_aktiv" 8 "EBKV_aktiv" 9 "IPA_aktiv" 10 "ARA_aktiv" 11 "RCTA_aktiv" 12 "autonomous_Hold_aktiv" 13 "STA_aktiv" 14 "Motor_aktiv" ;
VAL_ 418 HMS_Konsistenz_HVLM 0 "kein_Fehler_erkannt" 1 "Fehler_erkannt" ;
VAL_ 418 HMS_Konsistenz_ACC 0 "kein_Fehler_erkannt" 1 "Fehler_erkannt" ;
VAL_ 418 HMS_Fehlerstatus 0 "kein_Fehler" 1 "Halten_nicht_moeglich" 2 "Sonderbetriebsmodus_aktiv" 3 "Systemeinschraenkung" 4 "Systemstoerung" ;
VAL_ 418 ESP_Index_Haltemoment 0 "Bremsmoment" 1 "Antriebsmoment" ;
VAL_ 418 ESP_Haltemoment 1022 "Init" 1023 "Fehler" ;
VAL_ 178 ESP_HL_Radgeschw_02 65533 "Unterspannung" 65534 "Init" 65535 "Fehler" ;
VAL_ 178 ESP_HR_Radgeschw_02 65533 "Unterspannung" 65534 "Init" 65535 "Fehler" ;
VAL_ 178 ESP_VL_Radgeschw_02 65533 "Unterspannung" 65534 "Init" 65535 "Fehler" ;
VAL_ 178 ESP_VR_Radgeschw_02 65533 "Unterspannung" 65534 "Init" 65535 "Fehler" ;
VAL_ 1629 BR_Systemart 0 "ABS" 1 "ABS_ASR" 2 "ESP" 3 "ESP_mit_integrierter_EPB" ;
VAL_ 1629 ESP_SpannungsAnf_02 0 "keine_Anforderung" 1 "Anforderung_Stufe1" 2 "Anforderung_Stufe2" 3 "Anforderung_Stufe3" ;
VAL_ 1629 ESP_Charisma_FahrPr 0 "keine_Funktion" 1 "Programm_1" 2 "Programm_2" 3 "Programm_3" 4 "Programm_4" 5 "Programm_5" 6 "Programm_6" 7 "Programm_7" 8 "Programm_8" 9 "Programm_9" 10 "Programm_10" 11 "Programm_11" 12 "Programm_12" 13 "Programm_13" 14 "Programm_14" 15 "Programm_15" ;
VAL_ 1629 ESP_Charisma_Status 0 "Init" 1 "verfuegbar" 2 "nicht_verfuegbar" 3 "asynchron_durch_Fahrerwunsch" ;
VAL_ 1629 ESP_Wiederstart_Anz_01 0 "keine_Anzeige" 1 "Rueckwaertsrollen" ;
VAL_ 1629 ESP_Wiederstart_Anz_02 0 "keine_Anzeige" 1 "Autohold_Rutschen" ;
VAL_ 1629 ESP_Wiederstart_Anz_03 0 "keine_Anzeige" 1 "Offroad_HDC" ;
VAL_ 1629 ESP_Wiederstart_Anz_04 0 "keine_Anzeige" 1 "ESC_Off" ;
VAL_ 1629 ESP_Stoppverbot_Anz_01 0 "keine_Anzeige" 1 "Notbremsung_aktiv" ;
VAL_ 1629 ESP_Stoppverbot_Anz_02 0 "keine_Anzeige" 1 "Autohold_AVH_Rutschen" ;
VAL_ 1629 ESP_Stoppverbot_Anz_03 0 "keine_Anzeige" 1 "Rueckwaertsrollen" ;
VAL_ 1629 ESP_Stoppverbot_Anz_04 0 "keine_Anzeige" 1 "ESP_Pumpenlauf" ;
VAL_ 1629 ESP_Stoppverbot_Anz_05 0 "keine_Anzeige" 1 "ESP_OFF" ;
VAL_ 1629 ESP_Stoppverbot_Anz_06 0 "keine_Anzeige" 1 "Offroad_HDC" ;
VAL_ 1629 ESP_Stoppverbot_Anz_07 0 "keine_Anzeige" 1 "ESP_Haltefunktion_nicht_verfuegbar" ;
VAL_ 1629 ESP_Stoppverbot_Anz_Std 0 "keine_Anzeige" 1 "Standard_Stoppvetogrund" ;
VAL_ 1629 ESP_Dachrelingsensor 0 "Sensor_nicht_verbaut" 1 "Quertraeger_montiert" 2 "Quertraeger_nicht_montiert" 3 "Fehler" ;
VAL_ 1629 ESP_Stoppverbot_Anz_08 0 "keine_Anzeige" 1 "Neigungsbegrenzung" ;
VAL_ 1629 HDC_Charisma_FahrPr 0 "keine_Funktion" 1 "Programm_1" 2 "Programm_2" 3 "Programm_3" 4 "Programm_4" 5 "Programm_5" 6 "Programm_6" 7 "Programm_7" 8 "Programm_8" 9 "Programm_9" 10 "Programm_10" 11 "Programm_11" 12 "Programm_12" 13 "Programm_13" 14 "Programm_14" 15 "Programm_15" ;
VAL_ 1629 HDC_Charisma_Status 0 "Init" 1 "verfuegbar" 2 "nicht_verfuegbar" 3 "asynchron_durch_Fahrerwunsch" ;
VAL_ 1629 BR_QBit_Reifenumfang 0 "gueltiger_Wert" 1 "Ersatz_Init_oder_Fehlerwert" ;
VAL_ 253 BR_Eingriffsmoment 1022 "Init" 1023 "Fehler" ;
VAL_ 253 ESP_PLA_Bremseingriff 0 "inaktiv" 1 "aktiv" ;
VAL_ 253 ESP_Diagnose 0 "ESP_nicht_in_Diagnose" 1 "ESP_in_Diagnose" ;
VAL_ 253 ESC_Reku_Freigabe 0 "keine_Freigabe_der_Rekuperation" 1 "Freigabe_der_Rekuperation" ;
VAL_ 253 ESC_v_Signal_Qualifier_High_Low 0 "Gueteschwelle_kleiner_1kmh" 1 "Gueteschwelle_kleiner_3kmh" 2 "Gueteschwelle_kleiner_5kmh" 3 "Gueteschwelle_kleiner_10kmh" 4 "Gueteschwelle_kleiner_20kmh" 5 "Gueteschwelle_groessergleich_20kmh" 6 "Init" 7 "Fehler" ;
VAL_ 253 ESP_Vorsteuerung 0 "keine_Vorsteuerung_aktiv" 1 "Vorsteuerung_aktiv" ;
VAL_ 253 ESP_AWV3_Brems_aktiv 0 "inaktiv" 1 "aktiv" ;
VAL_ 253 OBD_Schlechtweg 0 "kein_Schlechtweg_erkannt" 1 "Schlechtweg_erkannt" ;
VAL_ 253 OBD_QBit_Schlechtweg 0 "gueltiger_Wert" 1 "Ersatz_Init_oder_Fehlerwert" ;
VAL_ 253 ESP_v_Signal 65533 "Unterspannung" 65534 "Init" 65535 "Fehler" ;
VAL_ 253 ASR_Tastung_passiv 0 "ASR_aktiviert" 1 "ASR_passiv_getastet_oder_Schwellen_geaendert" ;
VAL_ 253 ESP_Tastung_passiv 0 "ESP_aktiviert" 1 "ESP_passiv_getastet_oder_Schwellen_geaendert" ;
VAL_ 253 ESP_Systemstatus 0 "iO" 1 "Fehler" ;
VAL_ 253 ASR_Schalteingriff 0 "keine_Anforderung" 1 "ASR_Schaltkennfeld" 2 "Rueckschaltung" 3 "Schaltverbot" ;
VAL_ 253 ESP_Haltebestaetigung 0 "kein_sicheres_Halten" 1 "sicheres_Halten" ;
VAL_ 253 ESP_MKB_Abbruch_Geschw 0 "MKB_nicht_beendet_wg_v_Schwelle" 1 "MKB_beendet_wg_v_Schwelle" ;
VAL_ 253 ESP_QBit_v_Signal 0 "gueltiger_Wert" 1 "Ersatz_Init_oder_Fehlerwert" ;
VAL_ 253 ABS_Bremsung 0 "keine_ABS_Regelung" 1 "ABS_Regelung_aktiv" ;
VAL_ 253 ASR_Anf 0 "keine_Anforderung" 1 "ASR_Anforderung" ;
VAL_ 253 MSR_Anf 0 "keine Anfoderung" 1 "MSR-Anforderung" ;
VAL_ 253 EBV_Eingriff 0 "kein_EBV_Eingriff" 1 "EBV_Eingriff" ;
VAL_ 253 EDS_Eingriff 0 "kein_EDS_Eingriff" 1 "EDS_Eingriff" ;
VAL_ 253 ESP_Eingriff 0 "kein_ESP_Eingriff" 1 "ESP_Eingriff_aktiv" ;
VAL_ 253 ESP_ASP 0 "inaktiv" 1 "aktiv" ;
VAL_ 253 ESP_Anhaltevorgang_ACC_aktiv 0 "inaktiv" 1 "aktiv" ;
VAL_ 427 ESC_AHW_aktiv 0 "keine_Aktivitaet" 1 "Aktivitaet_durch_IPA" 2 "Aktivitaet_durch_ARA" 3 "Aktivitaet_durch_ACC" 4 "tbd" 5 "tbd" 6 "tbd" 7 "tbd" ;
VAL_ 427 ESC_AHW_nicht_verfuegbar 0 "verfuegbar" 1 "nicht_verfuegbar" ;
VAL_ 427 ESC_ANB_CM_aktiv 0 "keine_Aktivitaet" 1 "Aktivitaet_durch_AWV" ;
VAL_ 427 ESC_ANB_CM_nicht_verfuegbar 0 "verfuegbar" 1 "nicht_verfuegbar" ;
VAL_ 427 ESC_Warnruck_aktiv 0 "keine_Aktivitaet" 1 "Aktivitaet_durch_AWV" 2 "Aktivitaet_durch_vFGS" 3 "Aktivitaet_durch_RCTA" 4 "Aktivitaet_durch_FCWO" 5 "Aktivitaet_durch_FCWP" 6 "Aktivitaet_durch_EA" 7 "Aktivitaet_durch_PCF" 8 "Aktivitaet_durch_KAS" 9 "Aktivitaet_durch_AGW" ;
VAL_ 427 ESC_Warnruck_nicht_verfuegbar 0 "verfuegbar" 1 "nicht_verfuegbar" ;
VAL_ 427 ESC_Prefill_aktiv 0 "keine_Aktivitaet" 1 "Prefill_aktiv" ;
VAL_ 427 ESC_Prefill_nicht_verfuegbar 0 "verfuegbar" 1 "nicht_verfuegbar" ;
VAL_ 427 ESC_HBA_aktiv 0 "keine_Aktivitaet" 1 "HBA_aktiv" ;
VAL_ 427 ESC_HBA_nicht_verfuegbar 0 "verfuegbar" 1 "nicht_verfuegbar" ;
VAL_ 427 ESC_TSK_SRBM_Anf 0 "keine_Aktivitaet" 1 "Aktivitaet_durch_TSK" ;
VAL_ 427 ESC_TSK_SRBM_nicht_verfuegbar 0 "verfuegbar" 1 "nicht_verfuegbar" ;
VAL_ 427 ESC_Verz_Reg_aktiv 0 "keine_Aktivitaet" 1 "Aktivitaet_TB_durch_AWV" 2 "Aktivitaet_ZB_durch_AWV" 3 "Aktivitaet_durch_vFGS" 4 "Aktivitaet_durch_TSK" 5 "Aktivitaet_durch_RCTA" 6 "Aktivitaet_durch_PLA_IPA" 7 "Aktivitaet_durch_STA" 8 "Aktivitaet_durch_ARA" 9 "Aktivitaet_durch_MKB" 10 "Aktivitaet_durch_BFF" 11 "Aktivitaet_durch_EA" 12 "Aktivitaet_durch_PCF" 14 "reserviert" 15 "Initialisierung" ;
VAL_ 427 ESC_Verz_Reg_nicht_verfuegbar 0 "verfuegbar" 1 "nicht_verfuegbar" ;
VAL_ 427 ESC_Verz_Reg_TB_nicht_verfuegbar 0 "verfuegbar" 1 "nicht_verfuegbar" ;
VAL_ 427 ESC_Verz_Reg_ZB_nicht_verfuegbar 0 "verfuegbar" 1 "nicht_verfuegbar" ;
VAL_ 427 ESC_Bremslicht_unplausibel 0 "plausibel" 1 "unplausibel" ;
VAL_ 427 ESC_Konsistenz_ACC 0 "konsistent" 1 "nicht_konsistent" ;
VAL_ 427 ESC_Konsistenz_AWV 0 "konsistent" 1 "nicht_konsistent" ;
VAL_ 427 ESC_Konsistenz_ARA 0 "konsistent" 1 "nicht_konsistent" ;
VAL_ 427 ESC_Konsistenz_IPA 0 "konsistent" 1 "nicht_konsistent" ;
VAL_ 427 ESC_Konsistenz_FCW 0 "konsistent" 1 "nicht_konsistent" ;
VAL_ 427 ESC_Konsistenz_NV 0 "konsistent" 1 "nicht_konsistent" ;
VAL_ 427 ESC_Konsistenz_RCTA 0 "konsistent" 1 "nicht_konsistent" ;
VAL_ 427 ESC_Konsistenz_TSK 0 "konsistent" 1 "nicht_konsistent" ;
VAL_ 427 ESC_Konsistenz_vFGS 0 "konsistent" 1 "nicht_konsistent" ;
VAL_ 427 ESC_Konsistenz_STA 0 "konsistent" 1 "nicht_konsistent" ;
VAL_ 427 ESC_Fahrer_Bremsdruck_bestimmend 0 "Fahrer_nicht_Bremsdruck_bestimmend" 1 "Fahrer_Bremsdruck_bestimmend" ;
VAL_ 427 ESC_Konsistenz_EA 0 "konsistent" 1 "nicht_konsistent" ;
VAL_ 427 ESC_Konsistenz_BFF 0 "konsistent" 1 "nicht_konsistent" ;
VAL_ 427 ESC_Konsistenz_MKB 0 "konsistent" 1 "nicht_konsistent" ;
VAL_ 427 ESC_Verz_ASIL_Verfuegbarkeit 0 "Nicht_verfuegbar" 1 "Verfuegbar_ab_ASIL_QM" 2 "Verfuegbar_ab_ASIL_A" 3 "Verfuegbar_ab_ASIL_B" 4 "Verfuegbar_ab_ASIL_C" 5 "reserved" 6 "reserved" 7 "reserved" ;
VAL_ 427 ESC_Pumpenanlauf_aktiv 0 "inaktiv" 1 "aktiv" ;
VAL_ 427 ESC_Konsistenz_AGW 0 "konsistent" 1 "nicht_konsistent" ;
VAL_ 427 ESC_Konsistenz_KAS 0 "konsistent" 1 "nicht_konsistent" ;
VAL_ 427 ESC_Konsistenz_PCF 0 "konsistent" 1 "nicht_konsistent" ;
VAL_ 264 FA_Hoehenwerte_kalibriert 0 "kalibrierte Höhenwerte in mm" 1 "Rohwerte" ;
VAL_ 264 FA_ESP_Zuschaltung 0 "keine_ESP_Beeinflussung" 1 "ESP_Zwangszuschaltung_angefordert" ;
VAL_ 264 FA_Hoehenwert_VL_00 254 "nicht initialisiert" 255 "Fehler" ;
VAL_ 264 FA_Hoehenwert_VL_01 254 "nicht initialisiert" 255 "Fehler" ;
VAL_ 264 FA_Hoehenwert_VR_00 254 "nicht initialisiert" 255 "Fehler" ;
VAL_ 264 FA_Hoehenwert_VR_01 254 "nicht initialisiert" 255 "Fehler" ;
VAL_ 264 FA_Hoehenwert_HL_00 254 "nicht initialisiert" 255 "Fehler" ;
VAL_ 264 FA_Hoehenwert_HL_01 254 "nicht initialisiert" 255 "Fehler" ;
VAL_ 264 FA_Hoehenwert_HR_00 254 "nicht initialisiert" 255 "Fehler" ;
VAL_ 264 FA_Hoehenwert_HR_01 254 "nicht initialisiert" 255 "Fehler" ;
VAL_ 1332 FCWO_Texte 0 "keine_Anzeige" 1 "Systemstoerung" 2 "keine_Sensorsicht" 3 "Demomodus" 4 "System_aus" 5 "nicht_definiert" 6 "ESC_aus" 7 "zurzeit_eingeschraenkt" ;
VAL_ 1332 FCWO_Warnung 0 "keine_Anzeige" 1 "latente_Vorwarnung" 2 "Vorwarnung" 3 "Akutwarnung" 4 "nicht_definiert" 5 "nicht_definiert" 6 "nicht_definiert" 7 "nicht_definiert" ;
VAL_ 1332 FCWP_Texte 0 "keine_Anzeige" 1 "Systemstoerung" 2 "keine_Sensorsicht" 3 "Demomodus" 4 "System_aus" 5 "nicht_definiert" 6 "ESC_aus" 7 "zurzeit_eingeschraenkt" ;
VAL_ 1332 FCWP_Warnung 0 "keine_Anzeige" 1 "latente_Vorwarnung" 2 "Vorwarnung" 3 "Akutwarnung" 4 "nicht_definiert" 5 "nicht_definiert" 6 "nicht_definiert" 7 "nicht_definiert" ;
VAL_ 1332 FCWO_LED_Leiste 0 "keine_Anzeige" 1 "Stufe_1_glimmen" 2 "Stufe_2_leuchten" 3 "nicht_definiert" ;
VAL_ 1332 FCWP_LED_Leiste 0 "keine_Anzeige" 1 "Stufe_1_glimmen" 2 "Stufe_2_leuchten" 3 "nicht_definiert" ;
VAL_ 1332 FCWO_Warnlevel 0 "keine Gefährdung" 63 "max. Gefährdung" ;
VAL_ 1332 FCWP_Warnlevel 0 "keine Gefährdung" 63 "max. Gefährdung" ;
VAL_ 1332 FCWO_Charisma_FahrPr 0 "keine_Funktion" 1 "Programm_1" 2 "Programm_2" 3 "Programm_3" 4 "Programm_4" 5 "Programm_5" 6 "Programm_6" 7 "Programm_7" 8 "Programm_8" 9 "Programm_9" 10 "Programm_10" 11 "Programm_11" 12 "Programm_12" 13 "Programm_13" 14 "Programm_14" 15 "Programm_15" ;
VAL_ 1332 FCWO_Charisma_Status 0 "Init" 1 "verfuegbar" 2 "nicht_verfuegbar" 3 "asynchron_durch_Fahrerwunsch" ;
VAL_ 1332 FCWP_Charisma_Status 0 "Init" 1 "verfuegbar" 2 "nicht_verfuegbar" 3 "asynchron_durch_Fahrerwunsch" ;
VAL_ 1332 FCWP_Charisma_FahrPr 0 "keine_Funktion" 1 "Programm_1" 2 "Programm_2" 3 "Programm_3" 4 "Programm_4" 5 "Programm_5" 6 "Programm_6" 7 "Programm_7" 8 "Programm_8" 9 "Programm_9" 10 "Programm_10" 11 "Programm_11" 12 "Programm_12" 13 "Programm_13" 14 "Programm_14" 15 "Programm_15" ;
VAL_ 314 FCWO_Ruck_Freigabe 0 "keine_Freigabe" 1 "Freigabe" ;
VAL_ 314 FCWO_Ruckprofil 0 "kein_Ruckprofil" 1 "Ruckprofil_1" 2 "Ruckprofil_2" 3 "Ruckprofil_3" 4 "Ruckprofil_4" 5 "Ruckprofil_5" 6 "Ruckprofil_6" 7 "Ruckprofil_7" ;
VAL_ 314 FCWO_Anf_Prefill 0 "Prefill_nicht_aktivieren" 1 "Prefill_aktivieren" ;
VAL_ 314 FCWO_HBA_Param 0 "Defaultparametersatz" 1 "leicht_erh_Empfindlichkeit" 2 "erhoehte_Empfindlichkeit" 3 "hoechste_Empfindlichkeit" ;
VAL_ 314 FCWP_Anf_Prefill 0 "Prefill_nicht_aktivieren" 1 "Prefill_aktivieren" ;
VAL_ 314 FCWP_HBA_Param 0 "Defaultparametersatz" 1 "leicht_erh_Empfindlichkeit" 2 "erhoehte_Empfindlichkeit" 3 "hoechste_Empfindlichkeit" ;
VAL_ 314 FCWP_Ruck_Freigabe 0 "keine_Freigabe" 1 "Freigabe" ;
VAL_ 314 FCWP_Ruckprofil 0 "kein_Ruckprofil" 1 "Ruckprofil_1" 2 "Ruckprofil_2" 3 "Ruckprofil_3" 4 "Ruckprofil_4" 5 "Ruckprofil_5" 6 "Ruckprofil_6" 7 "Ruckprofil_7" ;
VAL_ 1605 FLA_aktiv 0 "inaktiv" 1 "aktiv" ;
VAL_ 1605 FLA_ISP_defekt 0 "iO" 1 "defekt" ;
VAL_ 1605 FLA_Sensor_blockiert 0 "Sensor in Ordnung" 1 "Sensor blockiert" ;
VAL_ 1605 FLA_Abblendursache 0 "nichts erkannt (Init-Wert) " 1 "enentgegenkommendes Fahrzeug (Scheinwerfer erkannt) " 2 "vorausfahrendes Fahrzeug (Heckleuchten erkannt) " 4 "Geschwindigkeitslimit unterschritten" 8 "Ortschaft_erkannt" 16 "Umgebungshelligkeit_generell_zu_hell" 32 "Nebel erkannt " 64 "Übertemperatur Imager" 128 "Verzögerungsbedingung" 255 "Fehler" ;
VAL_ 1605 FLA_Fernlicht_PWM 127 "Fehler" ;
VAL_ 1605 ISP_EC_Lichtwert_vorne 62 "Init" 63 "Fehler" ;
VAL_ 1605 ISP_EC_Lichtwert_hinten 62 "Init" 63 "Fehler" ;
VAL_ 1605 ISP_Himmelsrichtung 30 "nicht verfuegbar bzw. Init" 31 "Fehler" ;
VAL_ 1605 ISP_Taste_betaetigt 0 "nicht_betaetigt" 1 "betaetigt" ;
VAL_ 1605 ISP_EC_aktiv 0 "inaktiv" 1 "aktiv" ;
VAL_ 1605 ISP_Kompass_aktiv 0 "inaktiv" 1 "aktiv" ;
VAL_ 1605 FLA_Aufblenden 0 "nicht_aufblenden" 1 "aufblenden" ;
VAL_ 1605 FLA_SAE_Mode 0 "Init" 1 "FLA_Icon_invertiert" ;
VAL_ 987 BCM_01_alt 0 "aktuell" 1 "veraltet" ;
VAL_ 987 SMLS_01_alt 0 "aktuell" 1 "veraltet" ;
VAL_ 987 ZV_02_alt 0 "aktuell" 1 "veraltet" ;
VAL_ 987 Wischer_01_alt 0 "aktuell" 1 "veraltet" ;
VAL_ 987 Anhaenger_01_alt 0 "aktuell" 1 "veraltet" ;
VAL_ 987 Klima_Sensor_02_alt 0 "aktuell" 1 "veraltet" ;
VAL_ 987 Verdeck_01_alt 0 "aktuell" 1 "veraltet" ;
VAL_ 987 Klima_11_alt 0 "aktuell" 1 "veraltet" ;
VAL_ 987 WFS_01_alt 0 "aktuell" 1 "veraltet" ;
VAL_ 987 Licht_Anf_01_alt 0 "aktuell" 1 "veraltet" ;
VAL_ 987 ZV_verriegelt_extern_soll 1 "Fahrzeug verriegelt extern; Sollzusstand" ;
VAL_ 987 BH_Lichthupe 0 "nicht_betaetigt" 1 "Blinkerhebel in Richtung Lichthupe betaetigt" ;
VAL_ 987 WFS_Klemmenfreigabe 0 "keine_Freigabe" 1 "Freigabe" ;
VAL_ 987 ZV_Tankklappe_offen 0 "Tankklappe_geschlossen" 1 "Tankklappe_offen" ;
VAL_ 987 AAG_Anhaenger_abgesteckt 1 "Anhaenger_wurde_bei_KL15_aus_abgesteckt" ;
VAL_ 987 BCM1_LDS_Stellung 0 "Init" 1 "Stellung_0" 2 "Auto" 3 "Standlicht" 4 "Abblendlicht" 7 "Fehler" ;
VAL_ 987 VS_VD_entriegelt 1 "Zustand des Verdeck entriegelt" ;
VAL_ 987 ZV_HFS_offen 0 "geschlossen" 1 "offen" ;
VAL_ 987 ZV_HBFS_offen 0 "geschlossen" 1 "offen" ;
VAL_ 987 VS_VD_offen_ver 0 "Init" 1 "Zustand des Verdecks verriegelt und offen" ;
VAL_ 987 VS_VD_zu_ver 1 "Zustand des Verdecks verriegelt und geschlossen" ;
VAL_ 987 ZV_BT_offen 1 "BT_geoeffnet" ;
VAL_ 987 BCM1_Rueckfahrlicht_Schalter 0 "nicht_betaetigt" 1 "betaetigt" ;
VAL_ 987 ZV_FT_offen 1 "FT_geoeffnet" ;
VAL_ 987 Wischer_vorne_aktiv 1 "Wischer vorne läuft" ;
VAL_ 987 AAG_Anhaenger_erkannt 0 "kein_Anhaenger_erkannt" 1 "AAG_Anhaenger_erkannt" ;
VAL_ 987 BCM1_MH_Schalter 0 "MH_geschlossen" 1 "MH_offen" ;
VAL_ 987 ZV_HD_offen 1 "Heckdeckel_auf" ;
VAL_ 987 Waschen_vorne_aktiv 1 "Waschen aktiv" ;
VAL_ 987 KL_Thermomanagement 0 "keine_Freigabe_TMM__max_Heizbedarf" 1 "kleine_Freigabe_TMM" 2 "mittlere_Freigabe_TMM" 3 "volle_Freigabe_TMM__kein_Heizbedarf" ;
VAL_ 987 WFS_Schluessel_Fahrberecht 0 "kein authorisierter Schluessel erkannt " 1 "aktive_Funkschluessel_Nr_01" 2 "aktive_Funkschluessel_Nr_02" 3 "aktive_Funkschluessel_Nr_03" 4 "aktive_Funkschluessel_Nr_04" 5 "aktive_Funkschluessel_Nr_05" 6 "aktive_Funkschluessel_Nr_06" 7 "aktive_Funkschluessel_Nr_07" 8 "aktive_Funkschluessel_Nr_08" 9 "ungueltig_09" 10 "ungueltig_10" 11 "ungueltig_11" 12 "ungueltig_12" 13 "ungueltig_13" 14 "ungueltig_14" 15 "ungueltig_15" ;
VAL_ 987 BCM_Rueckfahrlicht_Anf 0 "Licht_nicht_angefordert" 1 "Licht_angefordert" ;
VAL_ 987 WWSs_01_alt 0 "aktuell" 1 "veraltet" ;
VAL_ 987 BCM_Tankklappensteller_Fehler 0 "kein_Fehler" 1 "Fehler" ;
VAL_ 987 ZV_verriegelt_soll 0 "Init" 1 "nicht_verriegelt" 2 "verriegelt" ;
VAL_ 987 ZV_Schluessel_Zugang 0 "kein authorisierter Schluessel erkannt " 1 "aktive_Funkschluessel_Nr_01" 2 "aktive_Funkschluessel_Nr_02" 3 "aktive_Funkschluessel_Nr_03" 4 "aktive_Funkschluessel_Nr_04" 5 "aktive_Funkschluessel_Nr_05" 6 "aktive_Funkschluessel_Nr_06" 7 "aktive_Funkschluessel_Nr_07" 8 "aktive_Funkschluessel_Nr_08" 9 "ungueltig_09" 10 "ungueltig_10" 11 "ungueltig_11" 12 "ungueltig_12" 13 "ungueltig_13" 14 "ungueltig_14" 15 "ungueltig_15" ;
VAL_ 987 WFS_ID_Geb_autorisiert_in_Kl15 0 "nicht_authorisiert_in_Kl15" 1 "authorisiert_in_Kl15" ;
VAL_ 987 BH_Fernlicht 0 "nicht_betaetigt" 1 "Blinkerhebel_in_Richtung_Fernlicht_betaetigt" ;
VAL_ 987 BH_Blinker_li 0 "nicht_betaetigt" 1 "Blinkerhebel_Richtung_links_betaetigt" ;
VAL_ 987 BH_Blinker_re 0 "nicht_betaetigt" 1 "Blinkerhebel_Richtung_rechts_betaetigt" ;
VAL_ 987 BCM1_OBD_FStatus_ATemp 0 "kein Fehler / Init / nicht verbaut" 1 "KS- (Kurzschluss nach minus)" 2 "KS+ (Kurzschluss nach plus)" 3 "OC (Leitungsunterbrechung)" 4 "OOR+ (Signal zu gross)" 5 "OOR- (Signal zu klein)" 6 "RC+ (Signal unplausibel zu gross)" 7 "RC- (Signal unplausibel zu klein)" 8 "KS+/OC (Kurzschluss nach plus/Unterbrechung)" 9 "KS-/OC  (Kurzschluss nach minus/Unterbrechung)" 10 "KS-/KS+  (Kurzschluss nach minus/plus)" 11 "KS-/KS+/OC (Kurzschluss nach minus/plus/Unterbrechung)" 12 "frei" 13 "frei" 14 "frei" 15 "frei" ;
VAL_ 987 BCM1_Aussen_Temp_ungef 253 "nicht_verbaut" 254 "Initwert" 255 "Fehler" ;
VAL_ 988 Motor_12_alt 0 "aktuell" 1 "veraltet" ;
VAL_ 988 ESP_07_alt 0 "aktuell" 1 "veraltet" ;
VAL_ 988 Getriebe_11_alt 0 "aktuell" 1 "veraltet" ;
VAL_ 988 Getriebe_13_alt 0 "aktuell" 1 "veraltet" ;
VAL_ 988 Getriebe_17_alt 0 "aktuell" 1 "veraltet" ;
VAL_ 988 MO_QBit_Drehzahl_01 0 "gueltiger_Wert" 1 "Ersatz_Init_oder_Fehlerwert" ;
VAL_ 988 MKE_Texte 0 "keine_Anzeige" 1 "Warnstufe_1" 2 "Warnstufe_2" ;
VAL_ 988 MKE_Stufe 0 "deaktiviert" 1 "nicht_verfügbar" 2 "Stufe_1" 3 "Stufe_2" 4 "Stufe_3" 5 "Stufe_4" 6 "reserviert" 7 "reserviert" ;
VAL_ 988 GE_Fahrstufe 0 "Zwischenstellung" 1 "Init" 5 "Position_P" 6 "Position_R" 7 "Position_N" 8 "Position_D" 9 "Position_S" 10 "Effizienz" 13 "Tipp_in_S" 14 "Tipp_in_D" 15 "Fehler" ;
VAL_ 988 GE_Notlauf 0 "kein Notlauf / Init" 1 "Getriebe im Notlauf" ;
VAL_ 988 ESP_Rollenmodus_Deaktivieren 0 "keine_Aenderung" 1 "Abbruch" ;
VAL_ 988 GE_Freilauf_Status 0 "Freilauf_inaktiv_aber_moeglich" 1 "Freilauf_aktiv" 2 "Freilauf_nicht_moegl_1Verhinderer" 3 "Freilauf_nicht_moegl_gr_1Verhinderer" 7 "Fehler" ;
VAL_ 991 Innenlicht_11_alt 0 "aktuell" 1 "veraltet" ;
VAL_ 991 Spiegel_01_alt 0 "aktuell" 1 "veraltet" ;
VAL_ 991 Anhaenger_01_alt 0 "aktuell" 1 "veraltet" ;
VAL_ 991 Licht_hinten_01_alt 0 "aktuell" 1 "veraltet" ;
VAL_ 991 LH_EPS_01_alt 0 "aktuell" 1 "veraltet" ;
VAL_ 991 Klima_12_alt 0 "aktuell" 1 "veraltet" ;
VAL_ 991 SMLS_01_alt 0 "aktuell" 1 "veraltet" ;
VAL_ 991 Getriebe_14_alt 0 "aktuell" 1 "veraltet" ;
VAL_ 991 PLA_01_alt 0 "aktuell" 1 "veraltet" ;
VAL_ 991 PLA_Status_PLA_EPS 0 "reserviert" 1 "reserviert" 2 "reserviert" 3 "reserviert" 4 "PLA_EPS_aktivierbar" 5 "reserviert" 6 "PLA_EPS_Lenkwinkel_aktiv" 7 "reserviert" 8 "PLA_EPS_funktionsbereit" 9 "PLA_EPS_Neustart" 10 "PLA_EPS_Abbruch" 11 "reserviert" 12 "reserviert" 13 "reserviert" 14 "reserviert" 15 "reserviert" ;
VAL_ 991 IL_Innenlicht_aktiv 0 "Innenlicht inaktiv" 1 "Innenlicht aktiv" ;
VAL_ 991 FAS_Taster_Fehler 0 "kein_Fehler" 1 "Fehler" ;
VAL_ 991 AAG_Bremslicht_H_def 1 "Anhaenger_Bremslicht_defekt" ;
VAL_ 991 LH_3_Bremsl_def 0 "OK" 1 "hochgesetzte  Bremsleuchte defekt" ;
VAL_ 991 LH_Bremsl_li_ges_def 0 "OK" 1 "Alle Bremslichter hinten links defekt" ;
VAL_ 991 LH_Bremsl_re_ges_def 0 "OK" 1 "Alle Bremslichter hinten rechts defekt" ;
VAL_ 991 KL_Beschlagsgefahr 0 "keine_Beschlagsgefahr" 1 "Beschlagsgefahr" ;
VAL_ 991 FAS_Taster 0 "nicht_betaetigt" 1 "betaetigt" ;
VAL_ 991 SP_abklappen 0 "Spiegel_abklappen_nicht_aktiv" 1 "Spiegel_abklappen_aktiv" ;
VAL_ 991 SP_anklappen 0 "Spiegle_anklappen_nicht_aktiv" 1 "Spiegel_anklappen_aktiv" ;
VAL_ 991 KL_Umluftklappe_Status 0 "Frischluft" 1 "Teilumluft_10" 2 "Teilumluft_20" 3 "Teilumluft_30" 4 "Teilumluft_40" 5 "Teilumluft_50" 6 "Teilumluft_60" 7 "Teilumluft_70" 8 "Teilumluft_80" 9 "Teilumluft_90" 10 "Umluft" 15 "Fehler" ;
VAL_ 991 GE_amax_moeglich 511 "nicht_definiert" ;
VAL_ 991 KL_Geblspng_Soll 0 "0V_Motorspannung" 252 "0V_sofort_Abschalten" 253 "0V_senken_mit_Rampe" 254 "reserviert" 255 "Fehler" ;
VAL_ 991 EPS_Charisma_FahrPr 0 "keine_Funktion" 1 "Programm_1" 2 "Programm_2" 3 "Programm_3" 4 "Programm_4" 5 "Programm_5" 6 "Programm_6" 7 "Programm_7" 8 "Programm_8" 9 "Programm_9" 10 "Programm_10" 11 "Programm_11" 12 "Programm_12" 13 "Programm_13" 14 "Programm_14" 15 "Programm_15" ;
VAL_ 991 GE_Zustand_Kuppltemp 0 "Init" 1 "Kupplungstemp_normal" 2 "Kupplungstemp_hoch" 3 "Kupplungsschutz_aktivieren" ;
VAL_ 173 GE_MMom_Soll_02 1022 "keine_Anforderung_Init" 1023 "Fehler" ;
VAL_ 173 GE_MMom_Vorhalt_02 1022 "Init" 1023 "Fehler" ;
VAL_ 173 GE_Uefkt 1023 "Fehler" ;
VAL_ 173 GE_Fahrstufe 0 "Zwischenstellung" 1 "Init" 5 "Position_P" 6 "Position_R" 7 "Position_N" 8 "Position_D" 9 "Position_S" 10 "Effizienz" 13 "Tipp_in_S" 14 "Tipp_in_D" 15 "Fehler" ;
VAL_ 173 GE_Schaltablauf 0 "keine_Schaltung" 1 "Momentenueberschneidung" 2 "Befuellphase" 3 "Drehzahlueberfuehrung" ;
VAL_ 173 GE_Uefkt_unplausibel 0 "Uefkt_plausibel" 1 "Uefkt_unplausibel" ;
VAL_ 173 GE_MMom_Status_02 0 "kein_Eingriff" 1 "abs_reduzierender_Eingriff_auf_Gesamt_Antrieb_nur_schneller_Pfad" 2 "abs_erhoehender_Eingriff_auf_Gesamt_Antrieb" 3 "relativer_Eingriff_auf_Gesamt_Antrieb" 4 "relativer_Eingriff_auf_E_Maschine" 5 "abs_red_Eingr_auf_Gesamt_Antrieb_nur_Luftpfad" 6 "abs_red_Eingr_auf_Gesamt_Antrieb_Luft-_und_schnellen_Pfad" 7 "abs_Eingriff_auf_Gesamtantrieb_erhoehend_und_reduzierend" ;
VAL_ 173 GE_Status_Kraftschluss 0 "offen_kein_Kraftschluss" 1 "offen_mit_Kraftschluss" 2 "schlupfend_geregelt" 4 "geschlossen_mit_Mikroschlupf" 5 "geschlossen_mit_Ueberanpressung" 6 "sonstige_Fehler" 7 "fehlerhaft_geschlossen" ;
VAL_ 173 GE_MMom_Status 0 "keine Anforderung" 1 "reduzierender Getriebeeingriff" 2 "erhöhender Getriebeeingriff" 3 "Änderung mit Sprung" ;
VAL_ 173 GE_Freig_MMom_Vorhalt 0 "nicht_freigegeben" 1 "freigegeben" ;
VAL_ 173 GE_Verbot_Ausblendung 0 "kein_Verbot" 1 "Verbot" ;
VAL_ 173 GE_Zielgang 0 "Gang P/N (ausgekuppelt)" 1 "Gang 1" 2 "Gang 2" 3 "Gang 3" 4 "Gang 4" 5 "Gang 5" 6 "Gang 6" 7 "Gang 7" 8 "Gang R" 11 "Gang 8" 12 "Gang 9" 13 "Gang10" 14 "Istgang nicht definiert" 15 "Fehler" ;
VAL_ 299 GRA_Hauptschalter 0 "Hauptschalter_aus__Taster_nicht_betaetigt" 1 "Hauptschalter_ein__Taster_betaetigt" ;
VAL_ 299 GRA_Abbrechen 0 "nicht_betaetigt" 1 "betaetigt" ;
VAL_ 299 GRA_Typ_Hauptschalter 0 "gerasteter_Lenkstockschalter" 1 "getasteter_Lenkstockschalter" ;
VAL_ 299 GRA_Limiter 0 "nicht_betaetigt" 1 "betaetigt" ;
VAL_ 299 GRA_Tip_Setzen 0 "nicht_betaetigt" 1 "betaetigt" ;
VAL_ 299 GRA_Tip_Hoch 0 "nicht_betaetigt" 1 "betaetigt" ;
VAL_ 299 GRA_Tip_Runter 0 "nicht_betaetigt" 1 "betaetigt" ;
VAL_ 299 GRA_Tip_Wiederaufnahme 0 "nicht_betaetigt" 1 "betaetigt" ;
VAL_ 299 GRA_Verstellung_Zeitluecke 0 "Taste_nicht_betaetigt" 1 "Dist_minus_1" 2 "Dist_plus_1" 3 "Dist_Toggle" ;
VAL_ 299 GRA_Codierung 0 "kein_Hebel" 1 "GRA_Hebel" 2 "ACC_Hebel" 3 "Limiter_Only" ;
VAL_ 299 GRA_Fehler 0 "kein_Fehler" 1 "Fehler" ;
VAL_ 299 GRA_LIM_Taste_verfuegbar 0 "Limiter_Taste_nicht_vorhanden" 1 "Limiter_Taste_vorhanden" ;
VAL_ 299 GRA_Tip_Stufe_2 0 "Tip_Stufe_1__keine_Betaetigung" 1 "Tip_Stufe_2" ;
VAL_ 299 GRA_Typ_Bedienteil 0 "Init" 1 "4_Positions_Bedienteil" 2 "6_Positions_Bedienteil" 3 "8_Positions_Bedienteil" 4 "PAG_5_Positions_Bedienteil" 5 "VW_MFL_Gen2" 6 "reserviert" 7 "reserviert" ;
VAL_ 294 EA_ACC_Sollstatus 0 "Init" 1 "ACC_aktivieren" 2 "ACC_deaktivieren" ;
VAL_ 294 EA_Ruckprofil 0 "Init" 1 "Profil_1" 2 "Profil_2" 3 "Profil_3" 4 "Profil_4" 5 "Profil_5" 6 "Profil_6" 7 "Profil_7" ;
VAL_ 294 HCA_01_Sendestatus 0 "HCA_sendet_mit_1000ms" 1 "HCA_sendet_mit_20ms" ;
VAL_ 294 HCA_01_LM_OffSign 0 "positives_Vorzeichen" 1 "negatives_Vorzeichen" ;
VAL_ 294 HCA_01_Status_HCA 0 "deaktiviert" 1 "reserviert" 2 "reserviert" 3 "funktionsbereit" 4 "reserviert" 5 "HCA_Momenteneingriff_1" 6 "MA_Aktiv" 7 "HCA_Momenteneingriff_2" 8 "reserviert" 9 "reserviert" 10 "reserviert" 11 "reserviert" 12 "reserviert" 13 "reserviert" 14 "reserviert" 15 "reserviert" ;
VAL_ 294 EA_Ruckfreigabe 0 "keine_Freigabe" 1 "Freigabe" ;
VAL_ 294 EA_ACC_Wunschgeschwindigkeit 1023 "Init" ;
VAL_ 1385 HVEM_DCDC_Freigabe 0 "keine_Freigabe" 1 "Freigabe" ;
VAL_ 1385 HVEM_Ladesteckerentr_Anf 0 "keine_Anforderung" 1 "Anf_Ladestecker_Entr" ;
VAL_ 1385 HVEM_LeistungsAnf 0 "nicht_angefordert" 1 "angefordert" ;
VAL_ 1385 HVEM_Nachlad_Status 0 "nicht_moeglich__Fehler" 1 "moeglich__begonnen" 2 "Beendet" 3 "Init" ;
VAL_ 1385 HVEM_Abschaltstatus 0 "100" 1 "75" 2 "50" 3 "25" 7 "Init" ;
VAL_ 1385 HVEM_Anf_ReichweiteNV 0 "keine_Massnahme_notwendig" 1 "Reduktion_Stufe_1" 2 "Reduktion_Stufe_2" 3 "Fehler" ;
VAL_ 1385 HVEM_LadeklappenVerr_Anf 0 "Init" 1 "Ladeklappe_verriegeln" 2 "Ladeklappe_entriegeln" ;
VAL_ 1385 HVEM_HV_Anf 0 "keine_Anforderung" 1 "HV_angefordert" ;
VAL_ 1385 HVEM_Text_1 0 "kein_Text" 1 "Text" ;
VAL_ 1385 HVEM_Nachladen_Anf 0 "keine_Anforderung" 1 "Nachladen_angefordert" ;
VAL_ 1385 HVEM_FreigabeKlimatisierung 0 "keine_Freigabe" 1 "Freigabe" 2 "Init" 3 "Fehler" ;
